VERSION "HNNBNNNYNNNNNNNNNNNNNNNNNNNNNNNNNNNNNNNNNN/4/%%%/4/'%**4NNN///"

NS_ :

BS_:

BU_: BAP_Tester BCM Gateway_Max TSGGen3_BFS TSGGen3_FS TSGGen3_HBFS TSGGen3_HFS WLC_01_CFD

BO_ 1178 Mem_FS_01: 8 Gateway_Max
 SG_ Mem_FS_01_MQB_CRC : 0|8@1+ (1,0) [0|255] ""  Vector__XXX
 SG_ Mem_FS_01_MQB_BZ : 8|4@1+ (1,0) [0|15] ""  Vector__XXX
 SG_ FS_Fond_Bed_enable : 12|1@1+ (1.0,0.0) [0.0|1] ""  Vector__XXX
 SG_ FS_Lehne_nicht_verriegelt : 13|1@1+ (1.0,0.0) [0.0|1] ""  Vector__XXX
 SG_ FS_Spezialposition_anfahren : 14|1@1+ (1.0,0.0) [0.0|1] ""  Vector__XXX
 SG_ FS_Gurtbringer_Sperre : 15|1@1+ (1.0,0.0) [0.0|1] ""  TSGGen3_BFS,TSGGen3_FS,TSGGen3_HBFS,TSGGen3_HFS
 SG_ FS_BFS_Sitzsym_Anfahrt : 16|1@1+ (1.0,0.0) [0.0|1] ""  Vector__XXX
 SG_ FS_Sitzfahrt_aktiv : 17|1@1+ (1.0,0.0) [0.0|1] ""  TSGGen3_BFS,TSGGen3_FS,TSGGen3_HBFS,TSGGen3_HFS
 SG_ FS_SLV_aktiv : 18|1@1+ (1.0,0.0) [0.0|1] ""  Vector__XXX
 SG_ FS_SHV_aktiv : 19|1@1+ (1.0,0.0) [0.0|1] ""  Vector__XXX
 SG_ FS_LNV_aktiv : 20|1@1+ (1.0,0.0) [0.0|1] ""  Vector__XXX
 SG_ FS_SNV_aktiv : 21|1@1+ (1.0,0.0) [0.0|1] ""  Vector__XXX
 SG_ FS_KSV_aktiv : 22|1@1+ (1.0,0.0) [0.0|1] ""  Vector__XXX
 SG_ FS_LKV_aktiv : 23|1@1+ (1.0,0.0) [0.0|1] ""  Vector__XXX
 SG_ FS_STV_aktiv : 24|1@1+ (1.0,0.0) [0.0|1] ""  Vector__XXX
 SG_ FS_LHV_aktiv : 25|1@1+ (1.0,0.0) [0.0|1] ""  Vector__XXX
 SG_ FS_LWV_aktiv : 26|1@1+ (1.0,0.0) [0.0|1] ""  Vector__XXX
 SG_ FS_GHV_aktiv : 27|1@1+ (1.0,0.0) [0.0|1] ""  Vector__XXX
 SG_ FS_BFS_KSS_Anfahrt : 28|1@1+ (1.0,0.0) [0.0|1] ""  Vector__XXX
 SG_ FS_MMB_lokal_Stop : 29|1@1+ (1.0,0.0) [0.0|1] ""  Vector__XXX
 SG_ FS_MMB_storage : 32|4@1+ (1.0,0.0) [0.0|15] ""  BCM,TSGGen3_FS
 SG_ FS_MMB_tipp : 36|1@1+ (1.0,0.0) [0.0|1] ""  BCM,TSGGen3_FS
 SG_ FS_MMB_tast : 37|1@1+ (1.0,0.0) [0.0|1] ""  BCM,TSGGen3_FS
 SG_ FS_MMB_store_LED_on : 38|1@1+ (1.0,0.0) [0.0|1] ""  TSGGen3_FS
 SG_ FS_MMB_storage_beep : 39|1@1+ (1.0,0.0) [0.0|1] ""  Vector__XXX
 SG_ FS_MMB_store : 40|1@1+ (1.0,0.0) [0.0|1] ""  TSGGen3_FS
 SG_ FS_MMB_glob_stop : 41|1@1+ (1.0,0.0) [0.0|1] ""  BCM,TSGGen3_FS
 SG_ FS_EE_Fond_FS_enable : 42|1@1+ (1.0,0.0) [0.0|1] ""  Vector__XXX
 SG_ FS_EE_Fond_BFS_enable : 43|1@1+ (1.0,0.0) [0.0|1] ""  Vector__XXX
 SG_ FS_BFS_Fond_Verst_enable : 44|1@1+ (1.0,0.0) [0.0|1] ""  Vector__XXX
 SG_ FS_EE_BFS_enable : 45|1@1+ (1.0,0.0) [0.0|1] ""  Vector__XXX

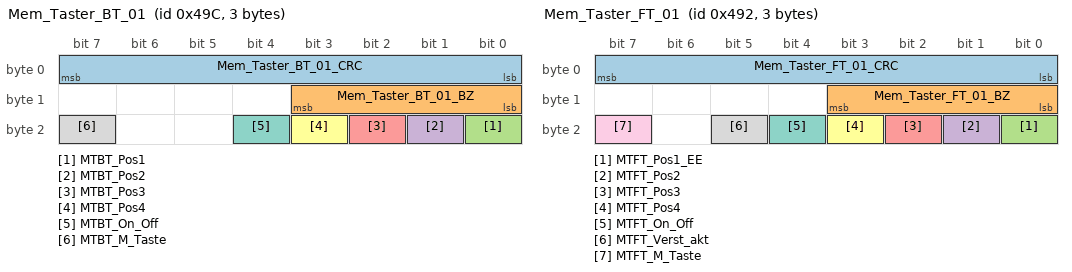
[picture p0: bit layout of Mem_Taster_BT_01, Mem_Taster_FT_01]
BO_ 1180 Mem_Taster_BT_01: 3 TSGGen3_BFS
 SG_ Mem_Taster_BT_01_CRC : 0|8@1+ (1,0) [0|255] ""  Gateway_Max
 SG_ Mem_Taster_BT_01_BZ : 8|4@1+ (1,0) [0|15] ""  Gateway_Max
 SG_ MTBT_Pos1 : 16|1@1+ (1.0,0.0) [0.0|1] ""  Gateway_Max
 SG_ MTBT_Pos2 : 17|1@1+ (1.0,0.0) [0.0|1] ""  Gateway_Max
 SG_ MTBT_Pos3 : 18|1@1+ (1.0,0.0) [0.0|1] ""  Gateway_Max
 SG_ MTBT_Pos4 : 19|1@1+ (1.0,0.0) [0.0|1] ""  Gateway_Max
 SG_ MTBT_On_Off : 20|1@1+ (1.0,0.0) [0.0|1] ""  Gateway_Max
 SG_ MTBT_M_Taste : 23|1@1+ (1.0,0.0) [0.0|1] ""  Gateway_Max

BO_ 1170 Mem_Taster_FT_01: 3 TSGGen3_FS
 SG_ Mem_Taster_FT_01_CRC : 0|8@1+ (1,0) [0|255] ""  Gateway_Max
 SG_ Mem_Taster_FT_01_BZ : 8|4@1+ (1,0) [0|15] ""  Gateway_Max
 SG_ MTFT_Pos1_EE : 16|1@1+ (1.0,0.0) [0.0|1] ""  Gateway_Max
 SG_ MTFT_Pos2 : 17|1@1+ (1.0,0.0) [0.0|1] ""  Gateway_Max
 SG_ MTFT_Pos3 : 18|1@1+ (1.0,0.0) [0.0|1] ""  Gateway_Max
 SG_ MTFT_Pos4 : 19|1@1+ (1.0,0.0) [0.0|1] ""  Gateway_Max
 SG_ MTFT_On_Off : 20|1@1+ (1.0,0.0) [0.0|1] ""  Gateway_Max
 SG_ MTFT_Verst_akt : 21|1@1+ (1.0,0.0) [0.0|1] ""  Gateway_Max
 SG_ MTFT_M_Taste : 23|1@1+ (1.0,0.0) [0.0|1] ""  Gateway_Max

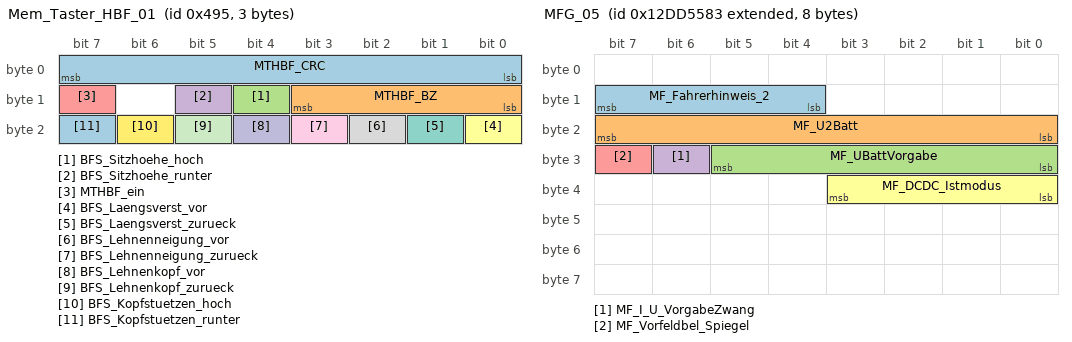
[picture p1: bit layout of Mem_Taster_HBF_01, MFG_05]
BO_ 1173 Mem_Taster_HBF_01: 3 TSGGen3_HBFS
 SG_ MTHBF_CRC : 0|8@1+ (1,0) [0|255] ""  Gateway_Max
 SG_ MTHBF_BZ : 8|4@1+ (1,0) [0|15] ""  Gateway_Max
 SG_ BFS_Sitzhoehe_hoch : 12|1@1+ (1.0,0.0) [0.0|1] ""  Gateway_Max
 SG_ BFS_Sitzhoehe_runter : 13|1@1+ (1.0,0.0) [0.0|1] ""  Gateway_Max
 SG_ MTHBF_ein : 15|1@1+ (1.0,0.0) [0.0|1] ""  Gateway_Max
 SG_ BFS_Laengsverst_vor : 16|1@1+ (1.0,0.0) [0.0|1] ""  Gateway_Max
 SG_ BFS_Laengsverst_zurueck : 17|1@1+ (1.0,0.0) [0.0|1] ""  Gateway_Max
 SG_ BFS_Lehnenneigung_vor : 18|1@1+ (1.0,0.0) [0.0|1] ""  Gateway_Max
 SG_ BFS_Lehnenneigung_zurueck : 19|1@1+ (1.0,0.0) [0.0|1] ""  Gateway_Max
 SG_ BFS_Lehnenkopf_vor : 20|1@1+ (1.0,0.0) [0.0|1] ""  Gateway_Max
 SG_ BFS_Lehnenkopf_zurueck : 21|1@1+ (1.0,0.0) [0.0|1] ""  Gateway_Max
 SG_ BFS_Kopfstuetzen_hoch : 22|1@1+ (1.0,0.0) [0.0|1] ""  Gateway_Max
 SG_ BFS_Kopfstuetzen_runter : 23|1@1+ (1.0,0.0) [0.0|1] ""  Gateway_Max

BO_ 1171 MFG_01: 8 Gateway_Max
 SG_ MFG_01_CRC : 0|8@1+ (1,0) [0|255] ""  BCM
 SG_ MFG_01_BZ : 8|4@1+ (1,0) [0|15] ""  BCM
 SG_ MF_ZV_Lock : 12|1@1+ (1.0,0.0) [0.0|1] ""  BCM
 SG_ MF_Motorweiterlauf : 13|1@1+ (1.0,0.0) [0.0|1] ""  BCM
 SG_ MF_Abzugssperre : 14|1@1+ (1.0,0.0) [0.0|1] ""  Vector__XXX
 SG_ MF_Anlassersperre : 15|1@1+ (1.0,0.0) [0.0|1] ""  Vector__XXX
 SG_ MF_Variante : 16|3@1+ (1.0,0.0) [0.0|7] ""  BCM,TSGGen3_BFS,TSGGen3_FS,TSGGen3_HBFS,TSGGen3_HFS
 SG_ MF_Schluessel_scan : 19|1@1+ (1.0,0.0) [0.0|1] ""  Vector__XXX
 SG_ MF_Laderelais : 20|1@1+ (1.0,0.0) [0.0|1] ""  Vector__XXX
 SG_ MF_StartStopp_Info : 21|2@1+ (1.0,0.0) [0.0|3] ""  Vector__XXX
 SG_ MF_Fernbed_ein : 23|1@1+ (1.0,0.0) [0.0|1] ""  BCM,TSGGen3_BFS,TSGGen3_FS,TSGGen3_HBFS,TSGGen3_HFS
 SG_ MF_Standlicht : 24|1@1+ (1.0,0.0) [0.0|1] ""  BCM
 SG_ MF_Fahrlicht : 25|1@1+ (1.0,0.0) [0.0|1] ""  BCM
 SG_ MF_interm_Fernlicht : 26|1@1+ (1.0,0.0) [0.0|1] ""  BCM
 SG_ MF_Warnblinker : 27|1@1+ (1.0,0.0) [0.0|1] ""  BCM
 SG_ MF_Fussraumbel : 28|1@1+ (1.0,0.0) [0.0|1] ""  BCM,TSGGen3_FS
 SG_ MF_Innenraumbel : 29|1@1+ (1.0,0.0) [0.0|1] ""  BCM,TSGGen3_BFS,TSGGen3_FS,TSGGen3_HBFS,TSGGen3_HFS
 SG_ MF_Innenraumbel_Unterdrueck : 30|1@1+ (1.0,0.0) [0.0|1] ""  BCM,TSGGen3_BFS,TSGGen3_FS,TSGGen3_HBFS,TSGGen3_HFS
 SG_ MF_Notstart : 31|1@1+ (1.0,0.0) [0.0|1] ""  Vector__XXX
 SG_ MF_Blk_li : 32|1@1+ (1.0,0.0) [0.0|1] ""  BCM
 SG_ MF_Blk_re : 33|1@1+ (1.0,0.0) [0.0|1] ""  BCM
 SG_ MF_Lichthupe : 34|1@1+ (1.0,0.0) [0.0|1] ""  BCM
 SG_ MF_Fernlicht : 35|1@1+ (1.0,0.0) [0.0|1] ""  BCM
 SG_ MF_HFS_verriegeln : 36|1@1+ (1.0,0.0) [0.0|1] ""  BCM
 SG_ MF_HFS_entriegeln : 37|1@1+ (1.0,0.0) [0.0|1] ""  BCM
 SG_ MF_HBFS_verriegeln : 38|1@1+ (1.0,0.0) [0.0|1] ""  BCM
 SG_ MF_HBFS_entriegeln : 39|1@1+ (1.0,0.0) [0.0|1] ""  BCM
 SG_ MF_Tippwischen : 40|1@1+ (1.0,0.0) [0.0|1] ""  BCM
 SG_ MF_Frontintervall : 41|1@1+ (1.0,0.0) [0.0|1] ""  BCM
 SG_ MF_Wischerstufe_1 : 42|1@1+ (1.0,0.0) [0.0|1] ""  BCM
 SG_ MF_Wischerstufe_2 : 43|1@1+ (1.0,0.0) [0.0|1] ""  BCM
 SG_ MF_Frontwaschen : 44|1@1+ (1.0,0.0) [0.0|1] ""  BCM
 SG_ MF_nachtr_Stopp_Anf : 45|1@1+ (1.0,0.0) [0.0|1] ""  Vector__XXX
 SG_ MF_Heckintervall : 46|1@1+ (1.0,0.0) [0.0|1] ""  BCM
 SG_ MF_Heckwaschen : 47|1@1+ (1.0,0.0) [0.0|1] ""  BCM
 SG_ MF_Summer : 48|1@1+ (1.0,0.0) [0.0|1] ""  Vector__XXX
 SG_ MF_Alarm_Blinkertakt : 49|1@1+ (1.0,0.0) [0.0|1] ""  BCM
 SG_ MF_Alarm_Blinker : 50|1@1+ (1.0,0.0) [0.0|1] ""  BCM
 SG_ MF_TFL_Abschaltung : 51|1@1+ (1.0,0.0) [0.0|1] ""  BCM
 SG_ MF_interm_Takt : 52|1@1+ (1.0,0.0) [0.0|1] ""  BCM
 SG_ MF_Tuerentriegelung_hinten : 53|1@1+ (1.0,0.0) [0.0|1] ""  BCM
 SG_ MF_interm_Fahrlicht : 54|1@1+ (1.0,0.0) [0.0|1] ""  BCM
 SG_ MF_Signalhorn : 55|1@1+ (1.0,0.0) [0.0|1] ""  BCM
 SG_ MF_FH_FT_hoch : 56|1@1+ (1.0,0.0) [0.0|1] ""  TSGGen3_FS
 SG_ MF_FH_FT_tief : 57|1@1+ (1.0,0.0) [0.0|1] ""  TSGGen3_FS
 SG_ MF_FH_BT_hoch : 58|1@1+ (1.0,0.0) [0.0|1] ""  TSGGen3_BFS
 SG_ MF_FH_BT_tief : 59|1@1+ (1.0,0.0) [0.0|1] ""  TSGGen3_BFS
 SG_ MF_FT_verriegeln : 60|1@1+ (1.0,0.0) [0.0|1] ""  BCM
 SG_ MF_FT_entriegeln : 61|1@1+ (1.0,0.0) [0.0|1] ""  BCM
 SG_ MF_BT_verriegeln : 62|1@1+ (1.0,0.0) [0.0|1] ""  BCM
 SG_ MF_BT_entriegeln : 63|1@1+ (1.0,0.0) [0.0|1] ""  BCM

BO_ 1164 MFG_03: 8 Gateway_Max
 SG_ MFG_Infotainment_Autark : 12|1@1+ (1.0,0.0) [0.0|1] ""  Vector__XXX
 SG_ MFG_Klappe_Status : 13|3@1+ (1.0,0.0) [0.0|7] ""  Vector__XXX
 SG_ MFG_LSH_DBetr_Ein : 16|1@1+ (1.0,0.0) [0.0|1] ""  Vector__XXX
 SG_ MFG_LSH_Betriebsdauer : 17|7@1+ (1,0) [0|120] "Unit_Minut"  Vector__XXX
 SG_ MFG_LSH_DBetr_Bestaet : 24|1@1+ (1.0,0.0) [0.0|1] ""  Vector__XXX
 SG_ MFG_LSH_Ansteuerung : 25|2@1+ (1.0,0.0) [0.0|3] ""  Vector__XXX
 SG_ MF_Radiomute : 27|1@1+ (1.0,0.0) [0.0|1] ""  Vector__XXX
 SG_ MF_Relais_2_Batterie : 28|1@1+ (1.0,0.0) [0.0|1] ""  Vector__XXX
 SG_ MF_Batteriediagnose : 29|3@1+ (1.0,0.0) [0.0|7] ""  Vector__XXX
 SG_ MFG_AppConnect_Anf : 32|2@1+ (1.0,0.0) [0.0|3] ""  Vector__XXX
 SG_ MF_Lampenausfall : 34|1@1+ (1.0,0.0) [0.0|1] ""  BCM
 SG_ MF_Blinker_L_Sta : 35|1@1+ (1.0,0.0) [0.0|1] ""  BCM
 SG_ MF_Blinker_R_Sta : 36|1@1+ (1.0,0.0) [0.0|1] ""  BCM
 SG_ MF_interm_Nebelscheinwerfer : 37|1@1+ (1.0,0.0) [0.0|1] ""  Vector__XXX
 SG_ MF_Generatordiagnose : 38|2@1+ (1.0,0.0) [0.0|3] ""  Vector__XXX
 SG_ MF_Heck_entriegeln : 40|1@1+ (1.0,0.0) [0.0|1] ""  BCM
 SG_ MF_Heck_verriegeln : 41|1@1+ (1.0,0.0) [0.0|1] ""  BCM
 SG_ MF_2BatSOCzugering : 42|1@1+ (1.0,0.0) [0.0|1] ""  Vector__XXX
 SG_ MF_Fahrerhinweis : 43|3@1+ (1.0,0.0) [0.0|7] ""  Vector__XXX
 SG_ MF_ZV_Unlock : 46|1@1+ (1.0,0.0) [0.0|1] ""  BCM
 SG_ MF_Tuerverriegelung_hinten : 47|1@1+ (1.0,0.0) [0.0|1] ""  BCM
 SG_ MF_2BattAb : 48|1@1+ (1.0,0.0) [0.0|1] ""  Vector__XXX
 SG_ MF_2BattHlkAnf : 49|1@1+ (1.0,0.0) [0.0|1] ""  Vector__XXX
 SG_ MF_2BattLadWarn : 50|1@1+ (1.0,0.0) [0.0|1] ""  Vector__XXX
 SG_ MF_2BattLlaAnf : 51|1@1+ (1.0,0.0) [0.0|1] ""  Vector__XXX
 SG_ MF_2BattSpannungsAnf : 52|2@1+ (1.0,0.0) [0.0|3] ""  Vector__XXX
 SG_ MF_NotStartAktiv : 54|1@1+ (1.0,0.0) [0.0|1] ""  Vector__XXX
 SG_ MF_ExterneLadungWarn : 55|1@1+ (1.0,0.0) [0.0|1] ""  Vector__XXX
 SG_ MF_LSH_Zielzeit : 56|4@1+ (10,0) [0|130] "Unit_Minut"  Vector__XXX
 SG_ MF_LSH_Abschaltstufe : 60|3@1+ (1.0,0.0) [0.0|7] ""  Vector__XXX
 SG_ MF_LSH_Einschaltverbot : 63|1@1+ (1.0,0.0) [0.0|1] ""  Vector__XXX

BO_ 2463978883 MFG_05: 8 Gateway_Max
 SG_ MF_Fahrerhinweis_2 : 12|4@1+ (1.0,0.0) [0.0|15] ""  Vector__XXX
 SG_ MF_U2Batt : 16|8@1+ (0.01,12.5) [12.50|15.00] "Unit_Volt"  Vector__XXX
 SG_ MF_UBattVorgabe : 24|6@1+ (0.1,12) [12.0|18.0] "Unit_Volt"  Vector__XXX
 SG_ MF_I_U_VorgabeZwang : 30|1@1+ (1.0,0.0) [0.0|1] ""  Vector__XXX
 SG_ MF_Vorfeldbel_Spiegel : 31|1@1+ (1.0,0.0) [0.0|1] ""  TSGGen3_BFS,TSGGen3_FS
 SG_ MF_DCDC_Istmodus : 32|4@1+ (1.0,0.0) [0.0|15] ""  Vector__XXX

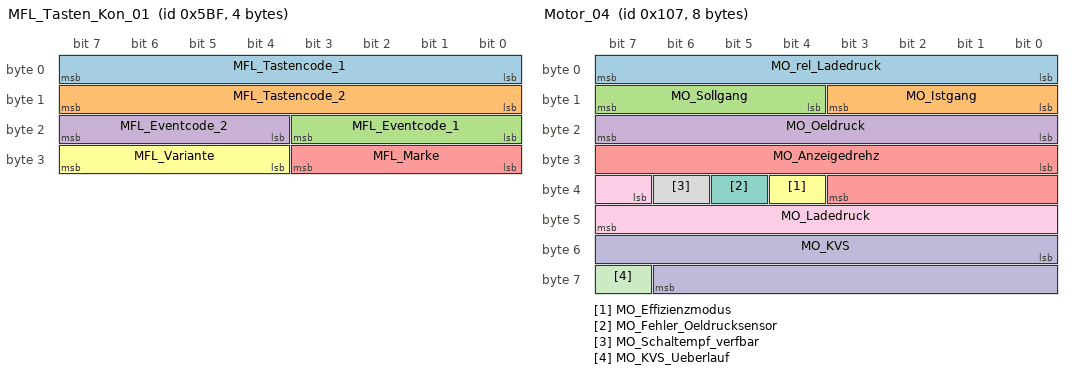
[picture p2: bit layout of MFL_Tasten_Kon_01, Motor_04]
BO_ 1471 MFL_Tasten_Kon_01: 4 Gateway_Max
 SG_ MFL_Tastencode_1 : 0|8@1+ (1.0,0.0) [0.0|255] ""  BCM
 SG_ MFL_Tastencode_2 : 8|8@1+ (1.0,0.0) [0.0|255] ""  BCM
 SG_ MFL_Eventcode_1 : 16|4@1+ (1.0,0.0) [0.0|15] ""  BCM
 SG_ MFL_Eventcode_2 : 20|4@1+ (1.0,0.0) [0.0|15] ""  BCM
 SG_ MFL_Marke : 24|4@1+ (1.0,0.0) [0.0|15] ""  BCM
 SG_ MFL_Variante : 28|4@1+ (1,0) [0|15] ""  BCM

BO_ 2463978865 MIK_01: 32 Gateway_Max
 SG_ MIK_01_CRC : 0|8@1+ (1,0) [0|255] ""  BCM
 SG_ MIK_01_BZ : 8|4@1+ (1,0) [0|15] ""  BCM
 SG_ MIK_Fahrer_erkannt : 12|2@1+ (1.0,0.0) [0.0|3] ""  BCM
 SG_ MIK_TotDurEyesNotOnTfc : 14|10@1+ (0.1,0) [0.0|102.0] "Unit_Secon"  Vector__XXX
 SG_ MIK_BlinkRate : 24|5@1+ (1,0) [0|27] "Unit_None"  Vector__XXX
 SG_ MIK_Status : 29|3@1+ (1.0,0.0) [0.0|7] ""  Vector__XXX
 SG_ MIK_LeftHandPos : 32|4@1+ (1.0,0.0) [0.0|15] ""  Vector__XXX
 SG_ MIK_LeftHandPosQual : 36|4@1+ (10,0) [0|100] "Unit_PerCent"  Vector__XXX
 SG_ MIK_RightHandPos : 40|4@1+ (1.0,0.0) [0.0|15] ""  Vector__XXX
 SG_ MIK_RightHandPosQual : 44|4@1+ (10,0) [0|100] "Unit_PerCent"  Vector__XXX
 SG_ MIK_DrowsinessLevel : 48|4@1+ (1.0,0.0) [0.0|15] ""  Vector__XXX
 SG_ MIK_DrowsinessLevelQual : 52|4@1+ (10,0) [0|100] "Unit_PerCent"  Vector__XXX
 SG_ MIK_DriverSmoking : 56|3@1+ (1.0,0.0) [0.0|7] ""  Vector__XXX
 SG_ MIK_PassengerPresence : 59|1@1+ (1.0,0.0) [0.0|1] ""  Vector__XXX
 SG_ MIK_DriverSmokingQual : 60|4@1+ (10,0) [0|100] "Unit_PerCent"  Vector__XXX
 SG_ MIK_DriverTelephoneUsage : 64|3@1+ (1.0,0.0) [0.0|7] ""  Vector__XXX
 SG_ MIK_DriverSpeaking : 67|1@1+ (1.0,0.0) [0.0|1] ""  Vector__XXX
 SG_ MIK_DriverTelephoneUsageQual : 68|4@1+ (10,0) [0|100] "Unit_PerCent"  Vector__XXX
 SG_ MIK_DriverYawning : 72|3@1+ (1.0,0.0) [0.0|7] ""  Vector__XXX
 SG_ FaceRec_Auth_Challenge_Request : 75|1@1+ (1.0,0.0) [0.0|1] ""  Vector__XXX
 SG_ MIK_DriverYawningQual : 76|4@1+ (10,0) [0|100] "Unit_PerCent"  Vector__XXX
 SG_ MIK_Microsleep : 80|3@1+ (1.0,0.0) [0.0|7] ""  Vector__XXX
 SG_ FaceRec2_Status_Challenge_Req : 83|1@1+ (1.0,0.0) [0.0|1] ""  Vector__XXX
 SG_ MIK_MicrosleepQual : 84|4@1+ (10,0) [0|100] "Unit_PerCent"  Vector__XXX
 SG_ MIK_UnusualHeadPose : 88|3@1+ (1.0,0.0) [0.0|7] ""  Vector__XXX
 SG_ MIK_UnusualHeadPoseQual : 92|4@1+ (10,0) [0|100] "Unit_PerCent"  Vector__XXX
 SG_ MIK_VisualDistractionLevel : 96|3@1+ (1.0,0.0) [0.0|7] ""  Vector__XXX
 SG_ MIK_VisualDistractionLevelQual : 100|4@1+ (10,0) [0|100] "Unit_PerCent"  Vector__XXX
 SG_ MIK_DurEyesNotOnTfc : 104|9@1+ (0.1,0) [0.0|50.7] "Unit_Secon"  Vector__XXX
 SG_ MIK_DurEyesCl : 113|7@1+ (0.1,0) [0.0|12.3] "Unit_Secon"  Vector__XXX
 SG_ MIK_PercentageEyesOnTraffic : 120|7@1+ (1,0) [0|100] "Unit_PerCent"  Vector__XXX
 SG_ MIK_SpaAttDstrAr_01 : 127|5@1+ (1.0,0.0) [0.0|31] ""  Vector__XXX
 SG_ MIK_SpaAttDstrProb_01 : 132|4@1+ (10,0) [0|100] "Unit_PerCent"  Vector__XXX
 SG_ MIK_DetectionMode : 136|3@1+ (1.0,0.0) [0.0|7] ""  Vector__XXX
 SG_ MIK_DriverChange : 139|1@1+ (1.0,0.0) [0.0|1] ""  Vector__XXX
 SG_ MIK_DriverPresence : 140|3@1+ (1.0,0.0) [0.0|7] ""  Vector__XXX
 SG_ MIK_FakeDetected : 143|1@1+ (1.0,0.0) [0.0|1] ""  Vector__XXX
 SG_ MIK_ICV_Brightness : 144|7@1+ (1,0) [0|100] "Unit_PerCent"  Vector__XXX
 SG_ MIK_ICV_FrameRate : 151|5@1+ (1,0) [15|30] "Unit_SeconInver"  Vector__XXX
 SG_ MIK_ICV_FieldOfView : 156|2@1+ (1.0,0.0) [0.0|3] ""  Vector__XXX
 SG_ MIK_ICV_FunctionState : 158|2@1+ (1.0,0.0) [0.0|3] ""  Vector__XXX
 SG_ MIK_ICV_Resolution : 160|3@1+ (1.0,0.0) [0.0|7] ""  Vector__XXX
 SG_ MIK_ICV_Videostream_State : 163|3@1+ (1.0,0.0) [0.0|7] ""  Vector__XXX
 SG_ MIK_ICV_VideostreamResult : 166|2@1+ (1.0,0.0) [0.0|3] ""  Vector__XXX
 SG_ MIK_ICV_ColorMode : 168|2@1+ (1.0,0.0) [0.0|3] ""  Vector__XXX
 SG_ MIK_ICV_HDR : 170|2@1+ (1.0,0.0) [0.0|3] ""  Vector__XXX
 SG_ MIK_ICV_Contrast : 172|7@1+ (1,0) [0|100] "Unit_PerCent"  Vector__XXX
 SG_ MIK_Selfie_FunctionState : 179|3@1+ (1.0,0.0) [0.0|7] ""  Vector__XXX
 SG_ MIK_Selfie_Resolution : 182|2@1+ (1.0,0.0) [0.0|3] ""  Vector__XXX
 SG_ MIK_ICV_AspectRatio : 184|3@1+ (1.0,0.0) [0.0|7] ""  Vector__XXX
 SG_ MIK_ICV_VideoLength : 187|3@1+ (1.0,0.0) [0.0|7] ""  Vector__XXX
 SG_ MIK_ChildStatus : 190|2@1+ (1.0,0.0) [0.0|3] ""  Vector__XXX
 SG_ MIK_PetPresence : 192|2@1+ (1.0,0.0) [0.0|3] ""  Vector__XXX
 SG_ MIK_CabinCare_state : 194|3@1+ (1.0,0.0) [0.0|7] ""  Vector__XXX
 SG_ MIK_PetsMode_Active : 197|1@1+ (1.0,0.0) [0.0|1] ""  Vector__XXX
 SG_ MIK_ChildPresence : 198|2@1+ (1.0,0.0) [0.0|3] ""  Vector__XXX
 SG_ MIK_CabinCare_Active : 200|1@1+ (1.0,0.0) [0.0|1] ""  Vector__XXX
 SG_ MIK_ICC_RemoteAccessStatus : 201|2@1+ (1.0,0.0) [0.0|3] ""  Vector__XXX

BO_ 2527679795 MKGO_FBS_01: 64 WLC_01_CFD
 SG_ MKGO_FBS_01 : 0|512@1+ (1.0,0.0) [0.0|13407807929942597099574024998205846127479365820592393377723561443721764030073546976801874298166903427690031858186486050853753882811946569946433649006084095] ""  BCM

BO_ 2527679796 MKGO_FBS_02: 64 WLC_01_CFD
 SG_ MKGO_FBS_02 : 0|512@1+ (1.0,0.0) [0.0|13407807929942597099574024998205846127479365820592393377723561443721764030073546976801874298166903427690031858186486050853753882811946569946433649006084095] ""  BCM

BO_ 2527679797 MKGO_FBS_03: 64 WLC_01_CFD
 SG_ MKGO_FBS_03 : 0|512@1+ (1.0,0.0) [0.0|13407807929942597099574024998205846127479365820592393377723561443721764030073546976801874298166903427690031858186486050853753882811946569946433649006084095] ""  BCM

BO_ 2527679798 MKGO_FBS_04: 64 WLC_01_CFD
 SG_ MKGO_FBS_04 : 0|512@1+ (1.0,0.0) [0.0|13407807929942597099574024998205846127479365820592393377723561443721764030073546976801874298166903427690031858186486050853753882811946569946433649006084095] ""  BCM

BO_ 2527679799 MKGO_FBS_05: 64 WLC_01_CFD
 SG_ MKGO_FBS_05 : 0|512@1+ (1.0,0.0) [0.0|13407807929942597099574024998205846127479365820592393377723561443721764030073546976801874298166903427690031858186486050853753882811946569946433649006084095] ""  BCM

BO_ 263 Motor_04: 8 Gateway_Max
 SG_ MO_rel_Ladedruck : 0|8@1+ (0.4,0) [0.0|100.0] "Unit_PerCent"  Vector__XXX
 SG_ MO_Istgang : 8|4@1+ (1.0,0.0) [0.0|15] ""  Vector__XXX
 SG_ MO_Sollgang : 12|4@1+ (1.0,0.0) [0.0|15] ""  Vector__XXX
 SG_ MO_Oeldruck : 16|8@1+ (0.04,0) [0.00|10.00] "Unit_Bar"  Vector__XXX
 SG_ MO_Anzeigedrehz : 24|12@1+ (3,0) [0|12282] "Unit_MinutInver"  BCM
 SG_ MO_Effizienzmodus : 36|1@1+ (1.0,0.0) [0.0|1] ""  Vector__XXX
 SG_ MO_Fehler_Oeldrucksensor : 37|1@1+ (1.0,0.0) [0.0|1] ""  Vector__XXX
 SG_ MO_Schaltempf_verfbar : 38|1@1+ (1.0,0.0) [0.0|1] ""  Vector__XXX
 SG_ MO_Ladedruck : 39|9@1+ (0.01,0) [0.00|5.10] "Unit_Bar"  Vector__XXX
 SG_ MO_KVS : 48|15@1+ (1,0) [0|32767] "Unit_MicroLiter"  Vector__XXX
 SG_ MO_KVS_Ueberlauf : 63|1@1+ (1.0,0.0) [0.0|1] ""  Vector__XXX

BO_ 1600 Motor_07: 8 Gateway_Max
 SG_ MO_QBit_Ansaugluft_Temp : 0|1@1+ (1.0,0.0) [0.0|1] ""  Vector__XXX
 SG_ MO_QBit_Oel_Temp : 1|1@1+ (1.0,0.0) [0.0|1] ""  Vector__XXX
 SG_ MO_QBit_Kuehlmittel_Temp : 2|1@1+ (1.0,0.0) [0.0|1] ""  Vector__XXX
 SG_ MO_KL15_Abschaltempfehlung : 3|1@1+ (1.0,0.0) [0.0|1] ""  BCM
 SG_ MO_HYB_Fehler_HV_Netz : 4|1@1+ (1.0,0.0) [0.0|1] ""  Vector__XXX
 SG_ MO_aktives_Getriebeheizen : 5|1@1+ (1.0,0.0) [0.0|1] ""  Vector__XXX
 SG_ MO_Absperrventil_oeffnen : 6|2@1+ (1.0,0.0) [0.0|3] ""  Vector__XXX
 SG_ MO_Ansaugluft_Temp : 8|8@1+ (0.75,-48) [-48.00|141.75] "Unit_DegreCelsi"  Vector__XXX
 SG_ MO_Oel_Temp : 16|8@1+ (1,-60) [-60|192] "Unit_DegreCelsi"  Vector__XXX
 SG_ MO_Kuehlmittel_Temp : 24|8@1+ (0.75,-48) [-48.00|141.75] "Unit_DegreCelsi"  Vector__XXX
 SG_ MO_Hoeheninfo : 32|8@1+ (0.00781,0) [0.00000|1.98374] ""  Vector__XXX
 SG_ MO_Kennfeldk : 40|1@1+ (1.0,0.0) [0.0|1] ""  Vector__XXX
 SG_ MO_Versionsinfo_02 : 41|5@1+ (1.0,0.0) [0.0|31] ""  Vector__XXX
 SG_ MO_QBit_Hoeheninfo : 46|1@1+ (1.0,0.0) [0.0|1] ""  Vector__XXX
 SG_ MO_Getriebe_kuehlen : 47|1@1+ (1.0,0.0) [0.0|1] ""  Vector__XXX
 SG_ MO_Mom_Traegheit_02 : 48|5@1+ (0.01,0) [0.00|0.31] "Unit_KiloGramMeterSquar"  Vector__XXX
 SG_ MO_Heizungspumpenansteuerung : 53|4@1+ (10,0) [0|100] "Unit_PerCent"  Vector__XXX
 SG_ MO_SpannungsAnf : 57|1@1+ (1.0,0.0) [0.0|1] ""  Vector__XXX
 SG_ MO_Nachlaufzeit_Heizungspumpe : 58|6@1+ (15,0) [0|945] "Unit_Secon"  Vector__XXX

BO_ 958 Motor_14: 8 Gateway_Max
 SG_ Motor_14_CRC : 0|8@1+ (1,0) [0|255] ""  BCM
 SG_ Motor_14_BZ : 8|4@1+ (1,0) [0|15] ""  BCM
 SG_ MO_StartStopp_Status : 12|2@1+ (1.0,0.0) [0.0|3] ""  BCM
 SG_ MO_StartStopp_Wiederstart : 14|1@1+ (1.0,0.0) [0.0|1] ""  BCM,TSGGen3_BFS,TSGGen3_FS,TSGGen3_HBFS,TSGGen3_HFS
 SG_ MO_StartStopp_Motorstopp : 15|1@1+ (1.0,0.0) [0.0|1] ""  BCM
 SG_ MO_Freig_Reku : 16|2@1+ (1.0,0.0) [0.0|3] ""  BCM
 SG_ MO_Kl_75 : 18|1@1+ (1.0,0.0) [0.0|1] ""  BCM,TSGGen3_BFS,TSGGen3_FS,TSGGen3_HBFS,TSGGen3_HFS
 SG_ MO_Kl_50 : 19|1@1+ (1.0,0.0) [0.0|1] ""  BCM,TSGGen3_BFS,TSGGen3_FS,TSGGen3_HBFS,TSGGen3_HFS
 SG_ MO_Gangposition : 20|4@1+ (1.0,0.0) [0.0|15] ""  BCM
 SG_ MO_StartStopp_Fahrerwunsch : 24|2@1+ (1.0,0.0) [0.0|3] ""  BCM
 SG_ MO_HYB_Fahrbereitschaft : 26|1@1+ (1.0,0.0) [0.0|1] ""  BCM
 SG_ MO_Ext_E_Fahrt_aktiv : 27|1@1+ (1.0,0.0) [0.0|1] ""  BCM
 SG_ MO_Fahrer_bremst : 28|1@1+ (1.0,0.0) [0.0|1] ""  BCM
 SG_ MO_QBit_Fahrer_bremst : 29|1@1+ (1.0,0.0) [0.0|1] ""  BCM
 SG_ MO_BLS : 30|1@1+ (1.0,0.0) [0.0|1] ""  BCM
 SG_ MO_Konsistenz_Bremsped : 31|1@1+ (1.0,0.0) [0.0|1] ""  BCM
 SG_ MO_Timeout_ESP : 32|1@1+ (1.0,0.0) [0.0|1] ""  BCM
 SG_ MO_Klima_Eingr : 33|2@1+ (1.0,0.0) [0.0|3] ""  BCM
 SG_ MO_Aussp_Anlass : 35|1@1+ (1.0,0.0) [0.0|1] ""  BCM
 SG_ MO_Freig_Anlass : 36|1@1+ (1.0,0.0) [0.0|1] ""  BCM
 SG_ MO_Kuppl_schalter : 37|1@1+ (1.0,0.0) [0.0|1] ""  BCM
 SG_ MO_Interlock : 38|1@1+ (1.0,0.0) [0.0|1] ""  BCM
 SG_ MO_Motor_laeuft : 39|1@1+ (1.0,0.0) [0.0|1] ""  BCM,TSGGen3_BFS,TSGGen3_FS,TSGGen3_HBFS,TSGGen3_HFS
 SG_ MO_Kickdown : 40|1@1+ (1.0,0.0) [0.0|1] ""  BCM
 SG_ MO_QBit_KL_75 : 41|1@1+ (1.0,0.0) [0.0|1] ""  BCM,TSGGen3_BFS,TSGGen3_FS,TSGGen3_HBFS,TSGGen3_HFS
 SG_ MO_EKlKomLeiRed : 42|2@1+ (1.0,0.0) [0.0|3] ""  BCM
 SG_ MO_Handshake_STH : 44|1@1+ (1.0,0.0) [0.0|1] ""  BCM
 SG_ MO_BKV_Unterdruckwarnung : 45|1@1+ (1.0,0.0) [0.0|1] ""  BCM
 SG_ MO_Freigabe_Segeln : 46|1@1+ (1.0,0.0) [0.0|1] ""  BCM
 SG_ MO_PTC_Status : 47|3@1+ (1.0,0.0) [0.0|7] ""  BCM
 SG_ MO_QBit_Gangposition : 50|1@1+ (1.0,0.0) [0.0|1] ""  BCM
 SG_ MO_Signalquelle_Gangposition : 51|1@1+ (1.0,0.0) [0.0|1] ""  BCM
 SG_ MO_Remotestart_Betrieb : 52|1@1+ (1.0,0.0) [0.0|1] ""  BCM
 SG_ MO_Remotestart_moeglich : 53|1@1+ (1.0,0.0) [0.0|1] ""  BCM
 SG_ MO_FMAus_aktiv : 55|1@1+ (1.0,0.0) [0.0|1] ""  BCM
 SG_ MO_FMAus_Startvariante : 56|2@1+ (1.0,0.0) [0.0|3] ""  BCM
 SG_ MO_BMS_NV_Anf_stuetzen : 58|1@1+ (1.0,0.0) [0.0|1] ""  BCM
 SG_ MO_Zylinderabschaltung : 59|2@1+ (1.0,0.0) [0.0|3] ""  BCM
 SG_ MO_HYB_VM_aktiv : 61|1@1+ (1.0,0.0) [0.0|1] ""  BCM
 SG_ MO_StartVorauss_erfuellt : 62|2@1+ (1.0,0.0) [0.0|3] ""  BCM

BO_ 1648 Motor_18: 8 Gateway_Max
 SG_ MO_max_Ladedruck : 0|6@1+ (0.1,0) [0.0|6.3] "Unit_Bar"  Vector__XXX
 SG_ MO_ANC_Kennfeld_Anf : 6|2@1+ (1.0,0.0) [0.0|3] ""  Vector__XXX
 SG_ MO_Bremslicht_Reku : 8|1@1+ (1.0,0.0) [0.0|1] ""  BCM
 SG_ MO_StartStopp_PopUp : 9|2@1+ (1.0,0.0) [0.0|3] ""  Vector__XXX
 SG_ MO1_Sperr_Info_WFS : 11|1@1+ (1.0,0.0) [0.0|1] ""  BCM
 SG_ MO1_Freigabe_Info_WFS : 12|1@1+ (1.0,0.0) [0.0|1] ""  Vector__XXX
 SG_ MO_EPCL : 13|3@1+ (1.0,0.0) [0.0|7] ""  Vector__XXX
 SG_ MO_Zylabsch_Texte_02 : 16|4@1+ (1.0,0.0) [0.0|15] ""  Vector__XXX
 SG_ MO_Fahrzeugtyp : 20|3@1+ (1.0,0.0) [0.0|7] ""  BCM
 SG_ MO_NMAX_Schaltanzeige : 23|9@1+ (25,0) [0|12775] "Unit_MinutInver"  Vector__XXX
 SG_ MO_Abstellzeit : 32|8@1+ (8,0) [0|2024] "Unit_Minut"  Vector__XXX
 SG_ MO_Abstellzeit_Status : 40|2@1+ (1.0,0.0) [0.0|3] ""  Vector__XXX
 SG_ MO1_Freigabe_Verfallsinfo_WFS : 42|1@1+ (1.0,0.0) [0.0|1] ""  Vector__XXX
 SG_ MO_Hybrid_StartStopp_LED : 43|2@1+ (1.0,0.0) [0.0|3] ""  BCM
 SG_ MO_Fehler_Zylabsch : 45|2@1+ (1.0,0.0) [0.0|3] ""  Vector__XXX
 SG_ MO_Anzahl_Abgesch_Zyl : 47|3@1+ (1.0,0.0) [0.0|7] ""  Vector__XXX
 SG_ MO_Zylabsch_Texte : 50|2@1+ (1.0,0.0) [0.0|3] ""  Vector__XXX
 SG_ MO_Ethanol_BS_Texte : 52|3@1+ (1.0,0.0) [0.0|7] ""  Vector__XXX
 SG_ MO_Drehzahl_Warnung : 55|1@1+ (1.0,0.0) [0.0|1] ""  Vector__XXX
 SG_ MO_obere_Drehzahlgrenze : 56|8@1+ (50,0) [50|12750] "Unit_MinutInver"  Vector__XXX

BO_ 967 Motor_26: 8 Gateway_Max
 SG_ MO_Kuehlerluefter_MUX M  : 0|1@1+ (1.0,0.0) [0.0|1] ""  BCM
 SG_ MO_Kuehlerluefter_1 m0  : 1|7@1+ (1,0) [0|100] "Unit_PerCent"  BCM
 SG_ MO_Kuehlerluefter_2 m1  : 1|7@1+ (1,0) [0|100] "Unit_PerCent"  BCM
 SG_ MO_EFLEX_Lampe : 8|2@1+ (1.0,0.0) [0.0|3] ""  BCM
 SG_ MO_KJS_nicht_bereit : 10|1@1+ (1.0,0.0) [0.0|1] ""  BCM
 SG_ MO_ITM_Warnung_Pumpe : 11|1@1+ (1.0,0.0) [0.0|1] ""  BCM
 SG_ WIV_Anzeige_aktiv : 12|1@1+ (1.0,0.0) [0.0|1] ""  BCM
 SG_ WIV_Oelmin_Warn : 13|1@1+ (1.0,0.0) [0.0|1] ""  BCM
 SG_ WIV_Sensorfehler : 14|1@1+ (1.0,0.0) [0.0|1] ""  BCM
 SG_ WIV_Schieflage : 15|1@1+ (1.0,0.0) [0.0|1] ""  BCM
 SG_ WIV_Oelstand : 16|4@1+ (12.5,0) [0.0|100.0] "Unit_PerCent"  BCM
 SG_ MO_Zustand_HWP : 20|2@1+ (1.0,0.0) [0.0|3] ""  BCM
 SG_ OLEV_Systemstoerung : 22|1@1+ (1.0,0.0) [0.0|1] ""  BCM
 SG_ MO_Oelwarnung_max : 23|1@1+ (1.0,0.0) [0.0|1] ""  BCM
 SG_ WIV_Oelsystem_aktiv : 24|1@1+ (1.0,0.0) [0.0|1] ""  BCM
 SG_ WIV_nicht_betriebswarm : 25|1@1+ (1.0,0.0) [0.0|1] ""  BCM
 SG_ WIV_Ueberfuell_Warn : 26|1@1+ (1.0,0.0) [0.0|1] ""  BCM
 SG_ WIV_laufender_Motor : 27|1@1+ (1.0,0.0) [0.0|1] ""  BCM
 SG_ MO_E_Warnungen : 28|4@1+ (1.0,0.0) [0.0|15] ""  BCM
 SG_ MO_Text_Motorstart : 32|4@1+ (1.0,0.0) [0.0|15] ""  BCM
 SG_ MO_E_Texte : 36|4@1+ (1.0,0.0) [0.0|15] ""  BCM
 SG_ WIV_Oeldyn_avl : 40|1@1+ (1.0,0.0) [0.0|1] ""  BCM
 SG_ MO_Text_Partikelfil_Reg : 41|1@1+ (1,0) [0|1] ""  BCM
 SG_ OLEV_Oelstand_nicht_vorhanden : 42|1@1+ (1.0,0.0) [0.0|1] ""  BCM
 SG_ WIV_Oelmenge : 43|5@1+ (125,0) [0|3875] "Unit_MilliLiter"  BCM
 SG_ MO_Systemlampe : 48|1@1+ (1.0,0.0) [0.0|1] ""  BCM
 SG_ MO_OBD2_Lampe : 49|1@1+ (1.0,0.0) [0.0|1] ""  BCM
 SG_ MO_Heissleuchte : 50|1@1+ (1.0,0.0) [0.0|1] ""  BCM
 SG_ MO_Partikel_Lampe : 51|1@1+ (1.0,0.0) [0.0|1] ""  BCM
 SG_ MO_RedFahrleistung_Lampe : 52|1@1+ (1.0,0.0) [0.0|1] ""  BCM
 SG_ WIV_Oelstand_nicht_vorhanden : 53|1@1+ (1.0,0.0) [0.0|1] ""  BCM
 SG_ WIV_nachfuellanzeige_ein : 54|1@1+ (1.0,0.0) [0.0|1] ""  BCM
 SG_ WIV_Ueberfuell_deaktiv : 55|1@1+ (1.0,0.0) [0.0|1] ""  BCM
 SG_ WIV_Unterfuell_Warn : 56|1@1+ (1.0,0.0) [0.0|1] ""  BCM
 SG_ MO_Tankdeckel_Lampe : 57|1@1+ (1.0,0.0) [0.0|1] ""  BCM
 SG_ MO_Text_Tankdeckelwarn : 58|1@1+ (1.0,0.0) [0.0|1] ""  BCM
 SG_ MO_Vorglueh_Lampe : 59|1@1+ (1.0,0.0) [0.0|1] ""  BCM
 SG_ WIV_Oeldr_Warn_Motor : 60|1@1+ (1.0,0.0) [0.0|1] ""  BCM
 SG_ MO_E_Mode : 61|3@1+ (1.0,0.0) [0.0|7] ""  BCM

BO_ 267 Motor_51_Auth: 48 Gateway_Max
 SG_ Motor_51_CRC : 0|8@1+ (1,0) [0|255] ""  BCM
 SG_ Motor_51_BZ : 8|4@1+ (1,0) [0|15] ""  BCM
 SG_ MO_Fahrpedalrohwert_01 : 12|8@1+ (0.4,0) [0.0|101.6] "Unit_PerCent"  BCM
 SG_ MO_QBit_Fahrpedalwerte_01 : 20|1@1+ (1.0,0.0) [0.0|1] ""  BCM
 SG_ MO_Fahrpedalgradient : 21|8@1+ (25,0) [0|6350] "Unit_PerCentPerSecon"  Vector__XXX
 SG_ MO_Sig_Fahrpedalgradient : 29|1@1+ (1.0,0.0) [0.0|1] ""  Vector__XXX
 SG_ MO_rel_Saugrohrdruck : 30|6@1+ (18,0) [0|1116] "Unit_MilliBar"  Vector__XXX
 SG_ MO_rel_Saugrohrdruck_gem_err : 36|1@1+ (1.0,0.0) [0.0|1] ""  Vector__XXX
 SG_ MO_Moment_im_Leerlauf : 37|1@1+ (1.0,0.0) [0.0|1] ""  Vector__XXX
 SG_ MO_Schubabschaltung : 38|1@1+ (1.0,0.0) [0.0|1] ""  Vector__XXX
 SG_ MO_StartStopp_StoppVorbereitung : 39|1@1+ (1.0,0.0) [0.0|1] ""  Vector__XXX
 SG_ MO_Solldrehz_Leerlauf : 40|8@1+ (10,0) [0|2540] "Unit_MinutInver"  Vector__XXX
 SG_ MO_Entkopplung_Sollschlupf : 48|7@1+ (20,0) [0|2480] "Unit_MinutInver"  Vector__XXX
 SG_ MO_temporaere_Fahrerabwesenheit : 55|1@1+ (1.0,0.0) [0.0|1] ""  Vector__XXX
 SG_ TSK_a_Soll_gradientenbegrenzt : 57|7@1+ (0.1,-7.2) [-7.2|5.4] "Unit_MeterPerSeconSquar"  Vector__XXX
 SG_ TSK_Radbremsmom : 76|12@1+ (8,0) [0|32760] "Unit_NewtoMeter"  Vector__XXX
 SG_ TSK_Status : 88|3@1+ (1.0,0.0) [0.0|7] ""  Vector__XXX
 SG_ TSK_v_Begrenzung_aktiv : 91|1@1+ (1.0,0.0) [0.0|1] ""  Vector__XXX
 SG_ TSK_Standby_Anf_ESP : 92|1@1+ (1.0,0.0) [0.0|1] ""  Vector__XXX
 SG_ TSK_Freig_Verzoeg_Anf : 94|1@1+ (1.0,0.0) [0.0|1] ""  Vector__XXX
 SG_ TSK_Limiter_ausgewaehlt : 95|1@1+ (1.0,0.0) [0.0|1] ""  Vector__XXX
 SG_ TSK_Hauptschalter_GRA_ACC : 106|2@1+ (1.0,0.0) [0.0|3] ""  Vector__XXX
 SG_ TSK_SRBM_Anf_ASIL : 108|3@1+ (1.0,0.0) [0.0|7] ""  Vector__XXX
 SG_ TSK_ax_Getriebe_02 : 112|9@1+ (0.024,-2.016) [-2.016|10.224] "Unit_MeterPerSeconSquar"  Vector__XXX
 SG_ TSK_Zwangszusch_ESP : 121|1@1+ (1.0,0.0) [0.0|1] ""  Vector__XXX
 SG_ TSK_zul_Regelabw : 122|6@1+ (0.024,0) [0.000|1.512] "Unit_MeterPerSeconSquar"  Vector__XXX
 SG_ TSK_Radsollmoment : 128|16@1+ (0.5,-16383) [-16383.0|16383.5] "Unit_NewtoMeter"  Vector__XXX
 SG_ TSK_Kategorie_Verzoegerungsfkt : 144|2@1+ (1.0,0.0) [0.0|3] ""  Vector__XXX
 SG_ TSK_Notstopp_Anf : 233|2@1+ (1.0,0.0) [0.0|3] ""  Vector__XXX
 SG_ MO_Status_MinDrzEingriff : 235|3@1+ (1.0,0.0) [0.0|7] ""  Vector__XXX
 SG_ MO_Status_MaxDrzEingriff : 238|3@1+ (1.0,0.0) [0.0|7] ""  Vector__XXX
 SG_ MO_Status_MinDrzEingriff_sek : 241|3@1+ (1.0,0.0) [0.0|7] ""  Vector__XXX
 SG_ MO_Status_MaxDrzEingriff_sek : 244|3@1+ (1.0,0.0) [0.0|7] ""  Vector__XXX
 SG_ TSK_SRBM_max_Gradient : 248|7@1+ (50,0) [0|6250] "Unit_NewtoMeterPerSecon"  Vector__XXX
 SG_ SOK_Motor_51_Signatur : 352|32@1+ (1,0) [0|4294967295] ""  Vector__XXX

CM_ BO_ 1178 "ab MQB 7.2";
CM_ BO_ 1180 "Ab MLBevo - CRC
";
CM_ BO_ 1170 "Ab MLBevo - CRC
";
CM_ BO_ 1173 "Ab MLBevo - CRC";
CM_ BO_ 1171 "ab MQB 7.2 gültig";
CM_ BO_ 1600 "ab MQB mit QBit Höheneinfo und MO_Versionsinfo_02";
CM_ BO_ 1648 "Kombischnittstelle";
CM_ BO_ 967 "MQB - vorher Motor_06 / Umbenennung wg. ID-Wechsel";

CM_ SG_ 1178 FS_BFS_Fond_Verst_enable "Verstellung Fond (vom MMI)
";
CM_ SG_ 1178 FS_BFS_KSS_Anfahrt "Komfortseitensicht Anfahrt BFS";
CM_ SG_ 1178 FS_BFS_Sitzsym_Anfahrt "Sitzsymetrie Anfahrt BFS";
CM_ SG_ 1178 FS_EE_BFS_enable "EasyEntry Freigabe für Befahrersitz.";
CM_ SG_ 1178 FS_EE_Fond_BFS_enable "EE Fond rechts

";
CM_ SG_ 1178 FS_EE_Fond_FS_enable "EE Fond links
";
CM_ SG_ 1178 FS_Fond_Bed_enable "Freigabe für Fondsitzverstellungen";
CM_ SG_ 1178 FS_GHV_aktiv "Verstellung Gurthöhe
";
CM_ SG_ 1178 FS_Gurtbringer_Sperre "Freigabesignal für den Gurtzubringer";
CM_ SG_ 1178 FS_KSV_aktiv "Verstellung Kopfstütze
";
CM_ SG_ 1178 FS_Lehne_nicht_verriegelt "Fahrer Sitz Lehne Verstellung Verriegelt Status

Verwendung nur im Bentley";
CM_ SG_ 1178 FS_LHV_aktiv "Verstellung Lordose Höhe
";
CM_ SG_ 1178 FS_LKV_aktiv "Verstellung Lehnenkopf
";
CM_ SG_ 1178 FS_LNV_aktiv "Verstellung Lehnenneigung
";
CM_ SG_ 1178 FS_LWV_aktiv "Verstellung Lordose W
";
CM_ SG_ 1178 FS_MMB_glob_stop "Abbruch Memoryverstellung";
CM_ SG_ 1178 FS_MMB_lokal_Stop "mit dem lokal Stop moechte man, dass ein Sitz mit Pneumatik - Lordose sich im Memoryfall wie ein Sitz mit elektromechanischer Lordose verhaelt. Nur lokler Abbruch im TIP-Betrieb.";
CM_ SG_ 1178 FS_MMB_storage "Memory-Positionstaste, Funkschlüssel-Memory-ID, Benutzerkonto-Nummer";
CM_ SG_ 1178 FS_MMB_storage_beep "Quittierungston Sitzmemory FS (Anforderung Kombi)";
CM_ SG_ 1178 FS_MMB_store "Memoryposition Speichern";
CM_ SG_ 1178 FS_MMB_store_LED_on "LED für Speichern
";
CM_ SG_ 1178 FS_MMB_tast "Memoryverstellung im Tastbetrieb";
CM_ SG_ 1178 FS_MMB_tipp "Memoryverstellung im Tippbetrieb";
CM_ SG_ 1178 FS_SHV_aktiv "Verstellung Sitzhöhe

";
CM_ SG_ 1178 FS_Sitzfahrt_aktiv "Aktive Sitzfahrt Fahrersitz
";
CM_ SG_ 1178 FS_SLV_aktiv "Sitzlängsverstellung
";
CM_ SG_ 1178 FS_SNV_aktiv "Verstellung Sitzneigung
";
CM_ SG_ 1178 FS_Spezialposition_anfahren "paralell zu diesem Signal wird eine Botschaft auf den KCAN gesendet in der spezielle Anforderungen für den Empfänger stehen. 
Dieses Signal dient zusätzlich der Checksummenabsicherung bei einer Remotverstellung ";
CM_ SG_ 1178 FS_STV_aktiv "Verstellung Sitztiefe
";
CM_ SG_ 1178 Mem_FS_01_MQB_BZ "4bit Botschaftszähler, wird mit jeder Sendebotschaft inkrementiert";
CM_ SG_ 1178 Mem_FS_01_MQB_CRC "Für MLB:
Berechnung siehe Lastenheft 'Kommunikationsabsicherung für FlexRay und CAN'
Ab MQB und MLBevo:
Berechnung siehe Lastenheft 'End-to-End Kommunikationsabsicherung'

Endwerte siehe Begleitdokument 'S-PDU Kennungsfolgen'";

CM_ SG_ 1180 Mem_Taster_BT_01_BZ "4bit Botschaftszähler, wird in jeder Sendebotschaft inkrementiert";
CM_ SG_ 1180 Mem_Taster_BT_01_CRC "Für MLB:
'Berechnung siehe Lastenheft 'Kommunikationsabsicherung für FlexRay und CAN''

Ab MQB und MLBevo:
'Berechnung siehe Lastenheft 'End-to-End Kommunikationsabsicherung''

Endwerte siehe Begleitdokument 'S-PDU Kennungsfolgen'";
CM_ SG_ 1180 MTBT_M_Taste "Betätigung M-Taste BT";
CM_ SG_ 1180 MTBT_On_Off "Betätigung On-Off Taste BT";
CM_ SG_ 1180 MTBT_Pos1 "Betätigung Postionstaste 1 BT";
CM_ SG_ 1180 MTBT_Pos2 "Betätigung Postionstaste 2 BT";
CM_ SG_ 1180 MTBT_Pos3 "Betätigung Postionstaste 3 BT";
CM_ SG_ 1180 MTBT_Pos4 "Betätigung Postionstaste 4 BT";

CM_ SG_ 1170 Mem_Taster_FT_01_BZ "4bit Botschaftszähler, wird in jeder Sendebotschaft inkrementiert";
CM_ SG_ 1170 Mem_Taster_FT_01_CRC "Für MLB:
'Berechnung siehe Lastenheft 'Kommunikationsabsicherung für FlexRay und CAN''

Ab MQB und MLBevo:
'Berechnung siehe Lastenheft 'End-to-End Kommunikationsabsicherung''

Endwerte siehe Begleitdokument 'S-PDU Kennungsfolgen'";
CM_ SG_ 1170 MTFT_M_Taste "Betätigung M-Taste FT";
CM_ SG_ 1170 MTFT_On_Off "Betätigung On-Off Taste FT";
CM_ SG_ 1170 MTFT_Pos1_EE "Betätigung Postionstaste 1 FT";
CM_ SG_ 1170 MTFT_Pos2 "Betätigung Postionstaste 2 FT";
CM_ SG_ 1170 MTFT_Pos3 "Betätigung Postionstaste 3 FT";
CM_ SG_ 1170 MTFT_Pos4 "Betätigung Postionstaste 4 FT";
CM_ SG_ 1170 MTFT_Verst_akt "Mem Taster Verstellung aktiv";

CM_ SG_ 1173 BFS_Kopfstuetzen_hoch "Kopfstützen hoch (Wird bei Rechtslenker vom TSG HL gesendet)";
CM_ SG_ 1173 BFS_Kopfstuetzen_runter "Kopfstützen runter (Wird bei Rechtslenker vom TSG HL gesendet)";
CM_ SG_ 1173 BFS_Laengsverst_vor "Längsverstellung vor (Wird bei Rechtslenker vom TSG HL gesendet)";
CM_ SG_ 1173 BFS_Laengsverst_zurueck "Längsverstellung zurück (Wird bei Rechtslenker vom TSG HL gesendet)";
CM_ SG_ 1173 BFS_Lehnenkopf_vor "Lehnenkopf vor (Wird bei Rechtslenker vom TSG HL gesendet)";
CM_ SG_ 1173 BFS_Lehnenkopf_zurueck "Lehnenkopf zurück (Wird bei Rechtslenker vom TSG HL gesendet)";
CM_ SG_ 1173 BFS_Lehnenneigung_vor "Lehnenneigung vor (Wird bei Rechtslenker vom TSG HL gesendet)";
CM_ SG_ 1173 BFS_Lehnenneigung_zurueck "Lehnenneigung zurück (Wird bei Rechtslenker vom TSG HL gesendet)";
CM_ SG_ 1173 BFS_Sitzhoehe_hoch "Dient der Sitzhoehenverstellung des Beifahrersitzes aus dem Fond";
CM_ SG_ 1173 BFS_Sitzhoehe_runter "Dient der Sitzhoehenverstellung des Beifahrersitzes aus dem Fond";
CM_ SG_ 1173 MTHBF_BZ "4bit Botschaftszähler, wird in jeder Sendebotschaft inkrementiert
(Wird bei Rechtslenker vom TSG HL gesendet)
";
CM_ SG_ 1173 MTHBF_CRC "Für MLB:
'Berechnung siehe Lastenheft 'Kommunikationsabsicherung für FlexRay und CAN''

Ab MQB und MLBevo:
'Berechnung siehe Lastenheft 'End-to-End Kommunikationsabsicherung''

Endwerte siehe Begleitdokument 'S-PDU Kennungsfolgen'";
CM_ SG_ 1173 MTHBF_ein "Wird bei Rechtslenker vom TSG HL gesendet";

CM_ SG_ 1171 MF_Abzugssperre "Schlüsselabzugssperre";
CM_ SG_ 1171 MF_Alarm_Blinker "Taxialarmblinken, wie DWA ohne Fanfare";
CM_ SG_ 1171 MF_Alarm_Blinkertakt "Ansteuerung Blinker bei Alarm. Signal wird getaktet.
0 = Blinker für Alarm aus
1 = Blinker für Alarm ein";
CM_ SG_ 1171 MF_Anlassersperre "Notarzt 230V-Steckdose";
CM_ SG_ 1171 MF_Blk_li "Versehrte oder Fahrschule; Prio über Fernbedienung ein";
CM_ SG_ 1171 MF_Blk_re "Versehrte oder Fahrschule; Prio über Fernbedienung ein";
CM_ SG_ 1171 MF_BT_entriegeln "Beifahrertür entriegeln";
CM_ SG_ 1171 MF_BT_verriegeln "Beifahrertür verriegeln";
CM_ SG_ 1171 MF_Fahrlicht "statisch oder auch mit Blink_modi für interm.  Fahrlicht";
CM_ SG_ 1171 MF_Fernbed_ein "Fernbedienung für Petri+Lehr; Versehrte und Fahrschule";
CM_ SG_ 1171 MF_Fernlicht "Versehrte oder Fahrschule; Oder-Verknüpfung";
CM_ SG_ 1171 MF_FH_BT_hoch "Versehrte";
CM_ SG_ 1171 MF_FH_BT_tief "Versehrte";
CM_ SG_ 1171 MF_FH_FT_hoch "Versehrte";
CM_ SG_ 1171 MF_FH_FT_tief "Versehrte";
CM_ SG_ 1171 MF_Frontintervall "Versehrte oder Fahrschule; Oder-Verknüpfung";
CM_ SG_ 1171 MF_Frontwaschen "Versehrte oder Fahrschule; Oder-Verknüpfung";
CM_ SG_ 1171 MF_FT_entriegeln "Fahrertür entriegeln";
CM_ SG_ 1171 MF_FT_verriegeln "Fahrertür verriegeln";
CM_ SG_ 1171 MF_Fussraumbel "Fussraumbeleuchtung, Fahrschule";
CM_ SG_ 1171 MF_HBFS_entriegeln "Hinten Beifahrertür entriegeln";
CM_ SG_ 1171 MF_HBFS_verriegeln "Hinten Beifahrertür verriegeln";
CM_ SG_ 1171 MF_Heckintervall "Versehrte oder Fahrschule; Oder-Verknüpfung";
CM_ SG_ 1171 MF_Heckwaschen "Versehrte oder Fahrschule; Oder-Verknüpfung";
CM_ SG_ 1171 MF_HFS_entriegeln "Hinten Fahrertür entriegeln";
CM_ SG_ 1171 MF_HFS_verriegeln "Hinten Fahrertür verriegeln";
CM_ SG_ 1171 MF_Innenraumbel "sämtliche Beleuchtungen akitivieren (Fussraum, Tür u.a.)";
CM_ SG_ 1171 MF_Innenraumbel_Unterdrueck "Unterdrückung des Innenlichts/Fussraumbeleuchtung, sowie Schließblinken";
CM_ SG_ 1171 MF_interm_Fahrlicht "Ansteuerung intermittierendes Abblendlicht";
CM_ SG_ 1171 MF_interm_Fernlicht "mit Blink_modi für SoSi oder Taxialarm";
CM_ SG_ 1171 MF_interm_Takt "Taktung von intermittierenden Fernlicht/Fahrlicht bei einer Einsatzfahrt
0 = Licht aus
1 = Licht ein";
CM_ SG_ 1171 MF_Laderelais "Signal für die Auswertung zur Anzeige der Batterie-Schwach-Anzeige im Kombi";
CM_ SG_ 1171 MF_Lichthupe "Versehrte oder Fahrschule; Oder-Verknuepfung
";
CM_ SG_ 1171 MF_Motorweiterlauf "Motorstop Behoerdenfahrzeug";
CM_ SG_ 1171 MF_nachtr_Stopp_Anf "Dieses Signal dient dem Motor als Trigger, dass ein nachträglicher Motorstopp eingeleitet werden kann, wenn es die Bedingungen des StSt Koordinators dies zulassen.";
CM_ SG_ 1171 MF_Notstart "Signal zeigt an, dass ein Notstart über DBMC erfolgte.

Verwendung in Verbindung mit Signal MF_Variante = DBMC.";
CM_ SG_ 1171 MF_Schluessel_scan "Anforderung eines Innenraumscans - Schlüsselsuche";
CM_ SG_ 1171 MF_Signalhorn "Versehrte, Fahrschule oder Taxi (bei Alarm)";
CM_ SG_ 1171 MF_Standlicht "statisch oder auch mit Blink_modi für Taxialarm";
CM_ SG_ 1171 MF_StartStopp_Info "Stopp-Freigabe und Start-Anforderung an den Start-Stopp-Koordinator";
CM_ SG_ 1171 MF_Summer "Warnsummer für Funkhauptschalter und Fahrschulpedal";
CM_ SG_ 1171 MF_TFL_Abschaltung "Abschaltung des Tagfahrlicht
0 = keine Auswirkung
1 = Tagfahrlicht deaktiviert";
CM_ SG_ 1171 MF_Tippwischen "Versehrte oder Fahrschule; Oder-Verknüpfung";
CM_ SG_ 1171 MF_Tuerentriegelung_hinten "Bei von innen verriegelten Fahrzeug Türen hinten entriegeln
0 = keine Auswirkung
1 = Türen hinten entriegeln
";
CM_ SG_ 1171 MF_Variante "Sonderfahrzeugvariante
0 = keine Sonderfunktion 
1 = Sondersignalfahrzeug
2 = Taxi 
3 = Fahrhilfe 
4 = Fahrschule+Extra 
5 = SSF
6 =  DBMC
7 = Arbeitsmaschine";
CM_ SG_ 1171 MF_Warnblinker "Versehrte";
CM_ SG_ 1171 MF_Wischerstufe_1 "Versehrte oder Fahrschule; Oder-Verknüpfung";
CM_ SG_ 1171 MF_Wischerstufe_2 "Versehrte oder Fahrschule; Oder-Verknüpfung";
CM_ SG_ 1171 MF_ZV_Lock "Verriegelungsanforderung durch MFG analog Meldung einer Locktasterbetätigung durch TSG.";
CM_ SG_ 1171 MFG_01_BZ "4bit Botschaftszähler, wird in jeder Sendebotschaft inkrementiert
";
CM_ SG_ 1171 MFG_01_CRC "Für MLB:
'Berechnung siehe Lastenheft 'Kommunikationsabsicherung für FlexRay und CAN''

Ab MQB und MLBevo:
'Berechnung siehe Lastenheft 'End-to-End Kommunikationsabsicherung''

Endwerte siehe Begleitdokument 'S-PDU Kennungsfolgen'";

CM_ SG_ 1164 MF_2BatSOCzugering "Anzeige bei geringer Ladung der Zweitbatterie";
CM_ SG_ 1164 MF_2BattAb "Batterie Ab Warnung der Zweitbatterie";
CM_ SG_ 1164 MF_2BattHlkAnf "Anforderung einer HLK - Stufe an das BEM";
CM_ SG_ 1164 MF_2BattLadWarn "Anzeige das bei Motorlauf die Zweitbatterie entladen wird im KI";
CM_ SG_ 1164 MF_2BattLlaAnf "Anforderung einer Drehzahlanhebung an das BEM";
CM_ SG_ 1164 MF_2BattSpannungsAnf "Mindestspannugnsanforderung der Zusatbatterie an den BEM";
CM_ SG_ 1164 MF_Batteriediagnose "Erstellt für Zusatzbatterie Crafter";
CM_ SG_ 1164 MF_Blinker_L_Sta "Status Blinker links Sonderaufbauten";
CM_ SG_ 1164 MF_Blinker_R_Sta "Status Blinker rechts Sonderaufbauten";
CM_ SG_ 1164 MF_ExterneLadungWarn "Warnung bei Motorlauf das externer Ladestecker gesteckt ist im KI";
CM_ SG_ 1164 MF_Fahrerhinweis "Fahrerhinweis Kombiinstrument";
CM_ SG_ 1164 MF_Generatordiagnose "Neu erstellt für Crafter";
CM_ SG_ 1164 MF_Heck_entriegeln "Entriegelung Heck über KFG";
CM_ SG_ 1164 MF_Heck_verriegeln "Verriegelung Heck über KFG";
CM_ SG_ 1164 MF_interm_Nebelscheinwerfer "Intermittierender Nebelscheinwerfer bei einer Einsatzfahrt";
CM_ SG_ 1164 MF_Lampenausfall "Meldung Lampenausfall Aufbauhersteller";
CM_ SG_ 1164 MF_LSH_Abschaltstufe "Abschaltstufen der Luftstandheizung an der Zweitbatterie. Das Signal dient der Steuerung des Klima SG an der ersten Batterie und der LSH an der zweiten Batterie durch das Zweitbatterie Em im KFG";
CM_ SG_ 1164 MF_LSH_Einschaltverbot "Statussignal für das Einschaltverbot der Luftstandheizung an der Zweitbatterie, Steuerung durch das Zweitbatterie EM im KFG.
0 volle Verfuegbarkeit Standheizung/-lueftung
1 Standheizung/-lueftung nicht aktivierbar";
CM_ SG_ 1164 MF_LSH_Zielzeit "Definition der Zielzeit für die Luftstandheizung an der zweiten Batterie, Steuerung durch das Zweitbatterie EM im KFG.";
CM_ SG_ 1164 MF_NotStartAktiv "Anzeige Notstart Aktiv für den Zeitraum der Schließung des Notstartrelais";
CM_ SG_ 1164 MF_Radiomute "Wird bei Sonderfahrzeugen wie Polizei dafür verwendet, um das Radio bei einem eingehenden Funkspruch zu muten.";
CM_ SG_ 1164 MF_Relais_2_Batterie "Zeigt den Zustand des vom KFG angesteuerten Laderelais einer verbauten 2. Batterie an";
CM_ SG_ 1164 MF_Tuerverriegelung_hinten "Internes Verriegeln der hinteren Türen";
CM_ SG_ 1164 MF_ZV_Unlock "Globales entriegeln über KFG";
CM_ SG_ 1164 MFG_AppConnect_Anf "AppConnect Anforderung durch das KFG";
CM_ SG_ 1164 MFG_Infotainment_Autark "Das Signal gibt an ob die Energieversorgung für ein Infotainment im Fahrzeug Autarkbetrieb sichergestellt ist";
CM_ SG_ 1164 MFG_Klappe_Status "Einstellung der Luftklappenposition an der Luftstandheizung";
CM_ SG_ 1164 MFG_LSH_Ansteuerung "Ansteuerung LSH";
CM_ SG_ 1164 MFG_LSH_Betriebsdauer "Betriebsdauer LSH";
CM_ SG_ 1164 MFG_LSH_DBetr_Bestaet "Bestätigung des KFGs an die LSH, dass Dauerbetrieb tatsächlich angefordert ist.";
CM_ SG_ 1164 MFG_LSH_DBetr_Ein "Dauerbetrieb der Luftstandheizung Ein";

CM_ SG_ 2463978883 MF_DCDC_Istmodus "aktuelle Betriebsart des NV DC/DC Wandlers";
CM_ SG_ 2463978883 MF_Fahrerhinweis_2 "Fahrerhinweis Kombiinstrument für Camperfunktionen";
CM_ SG_ 2463978883 MF_I_U_VorgabeZwang "Ladestrom und Spannungsvorgabe sind als Zwangsvorgaben der Zusatzbatterie zu behandeln";
CM_ SG_ 2463978883 MF_U2Batt "Spannung der Zweitbatterie";
CM_ SG_ 2463978883 MF_UBattVorgabe "Ladespannungsempfehlung Zusatz Batterie";
CM_ SG_ 2463978883 MF_Vorfeldbel_Spiegel "Schaltet die Vorfeldbeleuchtung der Außenspiegel";

CM_ SG_ 1471 MFL_Eventcode_1 "Siehe Q-LAH MFL-Protokoll";
CM_ SG_ 1471 MFL_Eventcode_2 "Siehe Q-LAH MFL-Protokoll";
CM_ SG_ 1471 MFL_Marke "Marke für markenspezifische Variantennummer des MFL";
CM_ SG_ 1471 MFL_Tastencode_1 "Beschreibt die Funktion einer fest zugeordneten Taste/Walze auf dem MFL. Bei Betätigung ändert sich der Wert von 0x0 auf den jeweiligen Tastencode.";
CM_ SG_ 1471 MFL_Tastencode_2 "Beschreibt die Funktion einer fest zugeordneten Taste/Walze auf dem MFL. Ist MFL_Tastencode_1 wegen Betätigung einer Taste/Walze bereits mit einem Wert ungleich 0x0 belegt, so ändert sich bei Betätigung einer weiteren Taste/Walze der Wert dieses Signals v";
CM_ SG_ 1471 MFL_Variante "Markenspezifische Variantennummer des MFL";

CM_ SG_ 2463978865 FaceRec2_Status_Challenge_Req "When IAA receives this signal it will provide a challenge via FaceRec2_Status_Challenge.

Duplicate of FaceRec signals for usage in separate messages using not SOK but own application level protection.";
CM_ SG_ 2463978865 FaceRec_Auth_Challenge_Request "When IAA receives this signal it will provide a challenge via SOK_FR_Auth_NAD_Challenge.";
CM_ SG_ 2463978865 MIK_01_BZ "4bit Botschaftszähler, wird mit jeder Sendebotschaft inkrementiert";
CM_ SG_ 2463978865 MIK_01_CRC "Für MLB:
Berechnung siehe Lastenheft 'Kommunikationsabsicherung für FlexRay und CAN'
Ab MQB und MLBevo:
Berechnung siehe Lastenheft 'End-to-End Kommunikationsabsicherung'

Endwerte siehe Begleitdokument 'S-PDU Kennungsfolgen'";
CM_ SG_ 2463978865 MIK_BlinkRate "Number of blinks detected within a fixed time window.";
CM_ SG_ 2463978865 MIK_CabinCare_Active "MIK ECU to HMI to transmit the de-/activation by the customer.";
CM_ SG_ 2463978865 MIK_CabinCare_state "current state of the cabin care function";
CM_ SG_ 2463978865 MIK_ChildPresence "child presence signal";
CM_ SG_ 2463978865 MIK_ChildStatus "child status signal";
CM_ SG_ 2463978865 MIK_DetectionMode "Indicates whether head pose, gaze, or a combination of head pose and gaze is used for visual perception estimation.";
CM_ SG_ 2463978865 MIK_DriverChange "Determines whether a driver change has been detected.";
CM_ SG_ 2463978865 MIK_DriverPresence "Determines whether a driver has been detected on the driver seat and whether the driver is buckled up.";
CM_ SG_ 2463978865 MIK_DriverSmoking "Determines whether the driver is smoking.";
CM_ SG_ 2463978865 MIK_DriverSmokingQual "Confidence factor of signal MIK_DriverSmoking.";
CM_ SG_ 2463978865 MIK_DriverSpeaking "Determines whether the driver is speaking.";
CM_ SG_ 2463978865 MIK_DriverTelephoneUsage "Determines whether the driver use continuously the mobile phone.";
CM_ SG_ 2463978865 MIK_DriverTelephoneUsageQual "Confidence factor of signal MIK_DriverTelephoneUsage.";
CM_ SG_ 2463978865 MIK_DriverYawning "Determines whether the driver is yawning.";
CM_ SG_ 2463978865 MIK_DriverYawningQual "Confidence factor of signal MIK_DriverYawning.";
CM_ SG_ 2463978865 MIK_DrowsinessLevel "Camera-based drowsiness level of the driver.";
CM_ SG_ 2463978865 MIK_DrowsinessLevelQual "Confidence factor of signal MIK_DrowsinessLevel.";
CM_ SG_ 2463978865 MIK_DurEyesCl "Duration the driver's eyes have been continuously closed.";
CM_ SG_ 2463978865 MIK_DurEyesNotOnTfc "Duration the driver has continuously not paid attention to traffic.";
CM_ SG_ 2463978865 MIK_Fahrer_erkannt "Erkennung der Anwesenheit einer Person auf der Fahrerseite vorne durch die MIK.";
CM_ SG_ 2463978865 MIK_FakeDetected "Indicates whether or not the driver monitoring system has detected an attempt at deception (e.g. masks).";
CM_ SG_ 2463978865 MIK_ICC_RemoteAccessStatus "This signal is needed to report the state of remote access (init,enabled, disabled)";
CM_ SG_ 2463978865 MIK_ICV_AspectRatio "This signal is needed to report the image and video's aspect ratio(init, 4:3, 16:9, 3:4, 9:16)";
CM_ SG_ 2463978865 MIK_ICV_Brightness "MIK_ICV_Brightness
the brightness of the videostream shall be configurable (0....100%)";
CM_ SG_ 2463978865 MIK_ICV_ColorMode "The color mode of the videostream shall be configurable (init, RGB, IR)";
CM_ SG_ 2463978865 MIK_ICV_Contrast "the contrast of the videostream shall be configurable [0...100%]";
CM_ SG_ 2463978865 MIK_ICV_FieldOfView "MIK_ICV_FieldOfView is needed to report the selected field of view (driver, CoDriver and fullCabine)";
CM_ SG_ 2463978865 MIK_ICV_FrameRate "MIK_ICV_FrameRate [15...30 frames per second]";
CM_ SG_ 2463978865 MIK_ICV_FunctionState "MIK_ICV_FunctionState is needed to report the current state of the MIK
(started, shutDown or error)";
CM_ SG_ 2463978865 MIK_ICV_HDR "The HDR (High Dynamic Range Image) of the videostream shall be configurable (init, on, off).";
CM_ SG_ 2463978865 MIK_ICV_Resolution "the resolution of the videostream shall be configurable 160x120, 320x240, 640x480,1280x720, 1920x1080";
CM_ SG_ 2463978865 MIK_ICV_VideoLength "This signal is needed to report the short video length to fits the social media directly. e.g. Tiktok, wechat. (init, 15s, 30s, 60s, customized)";
CM_ SG_ 2463978865 MIK_ICV_Videostream_State "MIK_ICV_Videostream_State is needed to report the state of the videostream.";
CM_ SG_ 2463978865 MIK_ICV_VideostreamResult "MIK_ICV_VideostreamResult is needed to provide the result of the videostream
(started, cancelled or freezed)";
CM_ SG_ 2463978865 MIK_LeftHandPos "Determines the most likely area of the driver´s left hand.";
CM_ SG_ 2463978865 MIK_LeftHandPosQual "Confidence factor of signal MIK_LeftHandPos.";
CM_ SG_ 2463978865 MIK_Microsleep "Camera-based microsleep detection.";
CM_ SG_ 2463978865 MIK_MicrosleepQual "Confidence factor of signal MIK_Microsleep.";
CM_ SG_ 2463978865 MIK_PassengerPresence "Determines whether passengers have been detected in the car.";
CM_ SG_ 2463978865 MIK_PercentageEyesOnTraffic "Relative duration the driver has monitored the traffic within a fixed time window.";
CM_ SG_ 2463978865 MIK_PetPresence "pet presence signal";
CM_ SG_ 2463978865 MIK_PetsMode_Active "MIK ECU to HMI to transmit the de-/activation by the customer.";
CM_ SG_ 2463978865 MIK_RightHandPos "Determines the most likely area of the driver´s right hand.";
CM_ SG_ 2463978865 MIK_RightHandPosQual "Confidence factor of signal MIK_RightHandPos.";
CM_ SG_ 2463978865 MIK_Selfie_FunctionState "This signal is needed to report the Selfie function state(init, VideoShot_Start, VideoShot_Stop, PhotoShot_Single, PhotoShot_Continuous, Cancel, Error)";
CM_ SG_ 2463978865 MIK_Selfie_Resolution "This signal is needed to report the image's resolution (int, 5M pixels, 2M pixels)";
CM_ SG_ 2463978865 MIK_SpaAttDstrAr_01 "Spatial Attention Distribution Area 1: Most likely Area of Interest the driver is currently looking at.";
CM_ SG_ 2463978865 MIK_SpaAttDstrProb_01 "Spatial Attention Distribution Probability 1: Probability the driver is currently looking at the Area of Interest given in signal 'MIK_SpaAttDstrAr_01'.";
CM_ SG_ 2463978865 MIK_Status "General status of the driver monitoring system.";
CM_ SG_ 2463978865 MIK_TotDurEyesNotOnTfc "Total duration the driver has not paid attention to traffic within a fixed time window including both continuous glances and short glances.";
CM_ SG_ 2463978865 MIK_UnusualHeadPose "Determines whether the driver's head is detected to be in an unusual pose.";
CM_ SG_ 2463978865 MIK_UnusualHeadPoseQual "Confidence factor of signal MIK_UnusualHeadPose.";
CM_ SG_ 2463978865 MIK_VisualDistractionLevel "Camera-based visual distraction of the driver.";
CM_ SG_ 2463978865 MIK_VisualDistractionLevelQual "Confidence factor of signal MIK_VisualDistractionLevel.";

CM_ SG_ 2527679795 MKGO_FBS_01 "NFC Kommunikation  MKGO zu FBS";

CM_ SG_ 2527679796 MKGO_FBS_02 "NFC Kommunikation  MKGO zu FBS";

CM_ SG_ 2527679797 MKGO_FBS_03 "NFC Kommunikation  MKGO zu FBS";

CM_ SG_ 2527679798 MKGO_FBS_04 "NFC Kommunikation  MKGO zu FBS";

CM_ SG_ 2527679799 MKGO_FBS_05 "NFC Kommunikation  MKGO zu FBS";

CM_ SG_ 263 MO_Anzeigedrehz "Optimierte Anzeigedrehzahl wegen sportlicherem Drehzahlmesser im Kombi. 
Bei Parallelhybrid: Anzeige VKM- Drehzahl nach Anzeigekonzept

Hinweis: Ehemaliger Fehlerwert 0xFFF wird senderseitig nicht unterstützt. Diesen Wert aus Kompatibilitätsgründen nic";
CM_ SG_ 263 MO_Effizienzmodus "Bei Handschaltern wird  das Fahrprogramm Effizienz signalisiert. 
Bei Automatikgetrieben wird das Fahrprogramm 'D' durch 'E' ersetzt.";
CM_ SG_ 263 MO_Fehler_Oeldrucksensor "Steuert  im Kombiinstrument die gelbe zentrale Warnlampe und das Symbol 'gelbe Ölkanne'  mit der Textmeldung 'Sensorfehler: Werkstatt aufsuchen' an
";
CM_ SG_ 263 MO_Istgang "Aktueller Gang für Anzeige Hochschaltempfehlung (gültig, wenn MO_Schaltempf_verfbar = 1).

Anzeige im Kombi:
Sollgang == Istgang         ==> Anzeige Istgang
Sollgang !=   Istgang         ==> Schaltempfehlung
Sollgang == Istgang == 0 ==> keine Anzeige";
CM_ SG_ 263 MO_KVS "Motorsteuergerätinterner Verbrauchszähler, der vom Kombi zyklisch ausgelesen wird, um die Einspritzmenge zur Verbrauchsmessung aufzusummieren; aus diesem Zählerstand werden Momentan- und Durchschnittsverbrauch berechnet; das Überlauf-Bit ist zu berücksich";
CM_ SG_ 263 MO_KVS_Ueberlauf "Der motorsteuergeräteinterne Verbrauchszähler ist mindestens einmal übergelaufen. Dieses Bit wird genutzt, um erkennen zu können, daß das Motorsteuergerät aus dem Reset-Zustand hochläuft.";
CM_ SG_ 263 MO_Ladedruck "absoluter Ladedruck";
CM_ SG_ 263 MO_Oeldruck "Öldruck analog zur Anzeige";
CM_ SG_ 263 MO_rel_Ladedruck "relativer Ladedruck (für Boostanzeige)";
CM_ SG_ 263 MO_Schaltempf_verfbar "Info, ob Schaltempfehlung im Fzg. verfügbar. Statischer Wert, ändert sich für ein Fzg. nicht!";
CM_ SG_ 263 MO_Sollgang "Motor sendet den Sollgang in den der Fahrer schalten soll. Wird im Kombi als Hochschaltempfehlung hervorgehoben (gültig, wenn MO_Schaltempf_verfbar = 1).

Anzeige im Kombi:
Sollgang == Istgang          ==> Anzeige Istgang
Sollgang !=  Istgang         ";

CM_ SG_ 1600 MO_Absperrventil_oeffnen "Signal an Klima-SG das Absperrrventil anzusteuern. Ab D4 auch 0x3 Ventil_schließen.

Im MQB wird hier der Soll-Status des Absperrventils ausgegeben.
Achtung: bei z. B. klemmendem Ventil entspricht das Signal nicht dem tatsächlichen Status!";
CM_ SG_ 1600 MO_aktives_Getriebeheizen "Information für Getriebe, ob ein Ventil für Getriebheizen angesteuert werden muss";
CM_ SG_ 1600 MO_Ansaugluft_Temp "In Fahrzeugen ohne Außentemperatur vom Kombi kann aus der Ansauglufttemperatur auf die Außentemperatur geschlossen werden. Beim SDI ist das mit einer gewissen Genauigkeit gegeben. Genutzt wird es vom ASG.";
CM_ SG_ 1600 MO_Getriebe_kuehlen "Anforderung Getriebekühlventilansteuerung";
CM_ SG_ 1600 MO_Heizungspumpenansteuerung "Anforderung Heizungspumpenansteuerung
MQB und Hybrid: Status der Heizungsunterstützungspumpe am MSG
";
CM_ SG_ 1600 MO_Hoeheninfo "Korrekturfaktor Höhe (1 entspricht 1013 mbar)";
CM_ SG_ 1600 MO_HYB_Fehler_HV_Netz "Im HV-Bordnetz ist fehlerbedingt kein generatorischer Betrieb möglich. Das 12V-Bordnetz wird über den DC/DC-Wandler allein aus der Traktionsbatterie gespeist. Um diesen Zustand möglichst lange aufrechterhalten zu können, sollten Komfort-Verbraucher abgesc";
CM_ SG_ 1600 MO_Kennfeldk "Die Kennfeldkühlung ist in diesem Fahrzeug verbaut und hat keinen Systemfehler";
CM_ SG_ 1600 MO_KL15_Abschaltempfehlung "Kessy Abschaltempfehlung nach Verlassen des Fahrzeugs";
CM_ SG_ 1600 MO_Kuehlmittel_Temp "Kuehlmitteltemperatur";
CM_ SG_ 1600 MO_Mom_Traegheit_02 "Massenträgheit (J) der Motors bzw. der Antriebsmaschinen in kgm².

Zur Berücksichtigung des E-Motor in Hybrid-Projekten:
in MLB-Projekten wird nur der J-Wert des Verbrennungsmotors und nicht der J-Wert des E-Motors berücksichtigt.
In MQB/MLBevo-Projek";
CM_ SG_ 1600 MO_Nachlaufzeit_Heizungspumpe "Nachlaufzeit für Heizungspumpe für Turboladerschutz";
CM_ SG_ 1600 MO_Oel_Temp "Realer Meßbereich ca. -40..150 Grad";
CM_ SG_ 1600 MO_QBit_Ansaugluft_Temp "
";
CM_ SG_ 1600 MO_QBit_Hoeheninfo "Qualifizierungsbit der Höheninfo. Gesetzt bei Ersatzwert, Init oder Fehler.";
CM_ SG_ 1600 MO_QBit_Kuehlmittel_Temp "
";
CM_ SG_ 1600 MO_SpannungsAnf "Forderung des Motor-SGs zur Spannungsanhebung";
CM_ SG_ 1600 MO_Versionsinfo_02 "Versioninformation vom Motor zur Steuerung bei inkompatiblen KMatrix-Änderung bzw. Einführung von neuen Funktionen, die in den Empfängern verriegelt werden müssen. Zu jedem Ereignis wird ein fixer Zählerstand zugeordnet, um dem Empfänger die funktionale Ä";

CM_ SG_ 958 MO_Aussp_Anlass "Das Signal zeigt an, ob die Wiederholstartsperre aktiv ist. D. h. eine Ansteuerung des Anlassers wird auch bei erfüllten Startvoraussetzungen (HS: Interlock betätigt bzw. AT: P/N eingelegt und Bremse betätigt) nicht erfolgen.";
CM_ SG_ 958 MO_BKV_Unterdruckwarnung "Über die Unterdruckwarnung signalisiert das MSG dem ESP, dass kein ausreichender Unterdruck für den BKV zur Verfügung gestellt werden kann.";
CM_ SG_ 958 MO_BLS "Ungefiltertes Rohsignal des Bremslichtschalters, nur wenn HW-Eingang bestückt und ausgewertet wird. Bei Motoren ohne genutzten HW-Eingang wird kein Ersatzwert (bspw. SW-Signal über CAN) ausgegeben!
Bei AUDI muss das Signal wg. Bremslichtfunktion immer be";
CM_ SG_ 958 MO_BMS_NV_Anf_stuetzen "Garantierte Unterstützung des Zusatzspeichers ist erforderlich. Zusatzspeicher muss an das Versorgungsnezt angebunden werden. ";
CM_ SG_ 958 MO_EKlKomLeiRed "Anforderung an die Klimasteuerung, die Leistungsaufnahme des E-Kompressors bei schlechtem SOC und in bestimmten Fahrsituationen zu begrenzen. (Das bereits bestehende Signal 'Klimakompressor aus' als stets umzusetzende Anforderung bleibt unverändert besteh";
CM_ SG_ 958 MO_Ext_E_Fahrt_aktiv "Funktionsrückmeldung zum erw. E-Fahr-Betrieb über Lampe/LED im E-Mode-Taster";
CM_ SG_ 958 MO_Fahrer_bremst "Redundante Bremsinformation vom Motor.

MLB:
AUDI D4: Zykluszeit: 10ms (siehe Zykluszeit schnell/Cycletime Fast)
Im AUDI B8 wird in diesem Bit der Wert der ESP-CAN-Information 'ESP_Fahrer_bremst' ausgegeben.

Achtung:
Reduktion der Zykluszeit Motor";
CM_ SG_ 958 MO_FMAus_aktiv "Das Signal gibt Rückmeldung ob Freilauf Motor aus aktiv ist. Beleibt auch 0km/h (unterhalb der StartStopp Schwelle) weiterhin aktiv.";
CM_ SG_ 958 MO_FMAus_Startvariante "Startvariante beim Motorstart aus der Freilauf-Motor-AUS Phase";
CM_ SG_ 958 MO_Freig_Anlass "Bit wird gesetzt, wenn der Motor beim Automatikstart gestartet werden darf (Motorstillstand, Emissionsmaßnahmen sind erfüllt).";
CM_ SG_ 958 MO_Freig_Reku "Empfehlung des Motor-SG's zur Spannungsabsenkung/-anhebung für den Rekuperationsbetrieb";
CM_ SG_ 958 MO_Freigabe_Segeln "Freigabebit des Segelbetriebs im Getriebe. Bedingt durch bestimmte Diagnosen und Adaptionen des MSGs, die nur im Schub möglich sind, darf nicht jede Schubphase für einen Segelbetrieb genutzt werden. Eine Freigabe bleibt auch außerhalb einer Schubphase bes";
CM_ SG_ 958 MO_Gangposition "MLB:
Stellung des Wählhebels in der Schaltgasse des Handschaltgetriebes.
MLBevo: 
Ausweitung der Bedienung auch auf Automatikgetriebe;
Routing des Signals GE_Fahrstufe: 
1. Position_R (dez. 6) auf MO_Gangposition: Gang_R (dez. 13) wegen Entfall Signa";
CM_ SG_ 958 MO_Handshake_STH "Es gilt: Signalspec MO_Handshake v1.0

Handshake zwischen MSG und STH. Wenn das MSG die EKP aufgrund einer STH-Anforderung ansteuert und kein Fehlereintrag bzgl. EKP/KPE/NDR vorliegt, wird das Bit gesetzt.";
CM_ SG_ 958 MO_HYB_Fahrbereitschaft "Signal steuert u.a. in der Lenkhilfe zusammen mit weiteren Informationen den Modewechsel in den 'Drivemode'
Grüne Anzeige im Kombiinstrument zur Signalisierung der Bereitschaft des Hybridsystems.";
CM_ SG_ 958 MO_HYB_VM_aktiv "0 = VMotor wird nicht aktiv gehalten (nVM < n_min und keine LL-Regelung aktiv)
1 = VMotor aktiv (ab der ersten Einspritzung; gilt auch für Schubbetrieb, wenn VMotor spätestens durch LLRegelung befeuert würde)
Verwendet zur Bestimmung des Ist-Zustandes";
CM_ SG_ 958 MO_Interlock "Das Motorsteuergerät gibt die Information aus, ab wann der Kupplungsschalter durch das Motorsteuergerät als getreten gesehen wird.
Bei Systemen für Start Stopp muss das Interlocksignal für einen Start durch das MSG generiert werden, sobald der Schalthebe";
CM_ SG_ 958 MO_Kickdown "Es gilt: Signalspec MO_Kickdown v1.0";
CM_ SG_ 958 MO_Kl_50 "Klemme 50: Startausführung durch Ritzelstarter

MLB: nicht von allen Motoren gesendet
MQB/MLBevo: gesendet von allen Motoren";
CM_ SG_ 958 MO_Kl_75 "Klemme X
";
CM_ SG_ 958 MO_Klima_Eingr "Eingriffe des Motor bei der Klima";
CM_ SG_ 958 MO_Konsistenz_Bremsped "MLB:

AUDI D4: Zykluszeit: 10ms (siehe Zykluszeit schnell/Cycletime Fast)
Siehe 'Funktionsspezifikation Bremslichtinfo B8'

Achtung:
Reduktion der Zykluszeit Motor_03 auf 10ms geplant.
Projektabhängig soll künftig mit 10ms gesendet werden.
Empfäng";
CM_ SG_ 958 MO_Kuppl_schalter "MLB:
Das Motorsteuergerät gibt die Information aus, ab wann der Kupplungsschalter durch das Motorsteuergerät als getreten gesehen wird
0x0: Schalter sagt betätigt (Ausgekuppelt)
0x1: Schalter sagt nicht betätigt (Eingekuppelt)

MQB:
Nur Handschalter";
CM_ SG_ 958 MO_Motor_laeuft "Das Motorsteuergerät gibt die Information aus, ab wann der Motor verbrennungsbedingt autark läuft und durch zuschaltbare Nebenaggregate mechanisch belastbar ist (z.B. durch Generator, Klimakompressor, etc.).

Die 'Motor läuft' Information wird ausgegebe";
CM_ SG_ 958 MO_PTC_Status "Status-Rückmeldung vom MSG zum aktuellen PTC-Status (stufiges PTC, Relais am MSG). Bei Ansteuerung eines stufigen PTC durch ein anderes SG beschreibt das Signal die vom MSG freigegebene PTC-Stufe.";
CM_ SG_ 958 MO_QBit_Fahrer_bremst "MLB:
AUDI D4: Zykluszeit: 10ms (siehe Zykluszeit schnell/Cycletime Fast)

Achtung:
Reduktion der Zykluszeit Motor_03 auf 10ms geplant.
Projektabhängig soll künftig mit 10ms gesendet werden.
Empfänger die in weiteren Konzern-Projekten eingesetzt werd";
CM_ SG_ 958 MO_QBit_Gangposition "Qualitätsbit zum Signal MO_Gangposition";
CM_ SG_ 958 MO_QBit_KL_75 "Q - Bit für das KL 75 Signal zur Vermeidung der fehlerhaften Erkennung von Motorstarts. 
Wird auf 1 gesetzt, solange das Motorsteuergerät KL15 = AUS erkannt hat.";
CM_ SG_ 958 MO_Remotestart_Betrieb "Das MSG ist für den Remotestart-Betrieb bereit. Nach Empfang der Motorstartanforderung für RSt-Betrieb durch BCM wird der Fahrzeugmotor gestartet und solange der Motor läuft, bleibt dieses Bit aktiv. Dieses Signal ist nur zur Verwendung durch das BCM zur ";
CM_ SG_ 958 MO_Remotestart_moeglich "Wenn Bit gesetzt, würde das MSG bei entsprechender Anforderung durch das BCM den Remotestartbetrieb einleiten, d.h. das MSG ist remotestartfähig und es liegen aktuell keine relevanten Fehler oder andere Abbruchgründe vor.";
CM_ SG_ 958 MO_Signalquelle_Gangposition "Signalquelle des Signals MO_Gangposition
0: Signalquelle Gangpositionssensor
1: Signalquelle Modellwert (v/n)";
CM_ SG_ 958 MO_StartStopp_Fahrerwunsch "Fahreraktivität Start/Stop";
CM_ SG_ 958 MO_StartStopp_Motorstopp "Motor-Stopp durch Start/Stopp-Koordinator
HYBRID:
Wenn MO_Hybridfahrzeug = 1 gilt:
Verbrennungsmotor durch Hybrid-Koordinator im MSG ausgeschaltet. 
Die definierten Start/Stopp-Signale beziehen sich nur auf den Verbrennungsmotor!";
CM_ SG_ 958 MO_StartStopp_Status "Aktivitätsstatus Start/Stopp-Koordinator
HYBRID:
Wenn MO_Hybridfahrzeug = 1 gilt:
Signal bezieht sich nur auf den Verbrennungsmotor, nicht auf den Hybridantrieb
";
CM_ SG_ 958 MO_StartStopp_Wiederstart "Motorwiederstart durch Start/Stopp-Koordinator
HYBRID:
Wenn MO_Hybridfahrzeug =1 gilt:
Warnung vor Spannungseinbruch beim Zustart des Verbrennungsmotors. 
-nicht relevant, da derzeit kein Start über 12V-Starter geplant-
Dieses Signal wird nur vom Hyb";
CM_ SG_ 958 MO_StartVorauss_erfuellt "Dient der Fallunterscheidung bei ZAT-Betätigung im Zustand 'KL15 ein' (bei nicht gesetztem Signal folgt KL15 aus, bei gesetztem Signal folgt setzen KL50-Anf.)

0: Signal nicht bedient 
1: Voraussetzungen zur Antriebsstrangaktivierung / Startvoraussetzu";
CM_ SG_ 958 MO_Timeout_ESP "500 ms Timeout auf Bremsen-Botschaft ist >= 1 mal aufgelaufen, Löschen des Bits nach Neustart (KL15).

MLB:
AUDI D4: Zykluszeit: 10ms (siehe Zykluszeit schnell/Cycletime Fast)

Achtung:
Reduktion der Zykluszeit Motor_03 auf 10ms geplant.
Projektabh";
CM_ SG_ 958 MO_Zylinderabschaltung "Status Zylinderabschaltung Motor";
CM_ SG_ 958 Motor_14_CRC "Ab MQB und MLBevo:
'Berechnung siehe Lastenheft 'End-to-End Kommunikationsabsicherung'

Endwerte siehe Begleitdokument 'S-PDU Kennungsfolgen'";

CM_ SG_ 1648 MO1_Freigabe_Info_WFS "WFS-Freigabeinformation";
CM_ SG_ 1648 MO1_Freigabe_Verfallsinfo_WFS "WFS-Freigabeverfallsinformation";
CM_ SG_ 1648 MO1_Sperr_Info_WFS "WFS-Sperrinformation";
CM_ SG_ 1648 MO_Abstellzeit "Abstelldauer nach letztem KL15 aus

Hinweis: 
Ehemaliger Fehlerwert 0xFF wird senderseitig nicht unterstützt. 
Diesen Wert aus Kompatibilitätsgründen nicht neu belegen!";
CM_ SG_ 1648 MO_Abstellzeit_Status "Statusinformation zur Abstellzeit
0: Die dem Status zugeordnete Variable konnte noch nicht berechnet werden. 
1: Die dem Status zugehörige Variable wurde korrekt berechnet. 
2: Der Wert der zugehörigen Variablen ist nur ein Minimalwert. 
3: Der Wert d";
CM_ SG_ 1648 MO_ANC_Kennfeld_Anf "Anforderung ANC Kennfeldumschaltung";
CM_ SG_ 1648 MO_Anzahl_Abgesch_Zyl "Gibt die Anzahl der abgeschalteten Zylinder an. In Übergangszuständen wird der Zielbetriebszustand angezeigt.";
CM_ SG_ 1648 MO_Bremslicht_Reku "Bremslicht (ggf. bei Rekuperation durch E-Motor) wird angesteuert";
CM_ SG_ 1648 MO_Drehzahl_Warnung "Warnhinweis zum Kombi im Fall einer fehlerbehafteten Drehzahlbegrenzung";
CM_ SG_ 1648 MO_EPCL "Die Anforderung der EPC-Lampe vom MSG ans Kombi soll durch das Bus-Signal MO_EPCL gemäß folgender Logik erfolgen:
MO_EPCL = 0 dez -> EPC Lampe aus, kein Text
MO_EPCL = 1 dez -> gelbe EPC-Symbolik, Text „Antrieb: Störung! Bitte Service aufsuchen“
MO_EPC";
CM_ SG_ 1648 MO_Ethanol_BS_Texte "Ethanol Brennstoff-Texte im Kombi

0 = kein Text
1 = E85 Warm_Up
2 = FlexFuel Warnung 3.Stufe (Too cold for ethanol)
3 = Warmfahrempfehlung MQB / FlexFuel Warnung 1.Stufe (Refuel with gasoline)
4 = FlexFuel Warnung 2. Stufe (Refuel with gasoline)
5";
CM_ SG_ 1648 MO_Fahrzeugtyp "Unterscheidet die Fahrzeugtypen bzgl. der Antriebsart";
CM_ SG_ 1648 MO_Fehler_Zylabsch "Fehlerstatus der Funktion Zylinderabschaltung ";
CM_ SG_ 1648 MO_Hybrid_StartStopp_LED "Ansteuerung der Funktions-LED der Hybrid Taste bzw. Start/Stop Deaktivierungstaste.
Der Start/Stopp-Master (derzeit im MSG) (oder ein künftiger Hybrid-Master) soll die Ansteuerung senden.";
CM_ SG_ 1648 MO_max_Ladedruck "maximal möglicher Ladedruck (zur Anpassung des Anzeigebereichs bei absoluter Ladedruckanzeige)";
CM_ SG_ 1648 MO_NMAX_Schaltanzeige "Maximaldrehzahl für Schaltanzeige";
CM_ SG_ 1648 MO_obere_Drehzahlgrenze "obere Drehzahlgrenze des Motors";
CM_ SG_ 1648 MO_StartStopp_PopUp "Das Signal zeigt an, ob der StSt-Status mittels Deaktivierungstaster geändert wurde. Ein Wechsel auf die Werte 01 oder 10 löst im Kombi ein entsprechendes PopUp aus. Bei einem Statuswechsel durch andere Signalquellen (z.B. Charisma, fehlerbedingte Abschal";
CM_ SG_ 1648 MO_Zylabsch_Texte "Zylinderabschaltung mode in Kombi, fuer Zylinderabschaltung";
CM_ SG_ 1648 MO_Zylabsch_Texte_02 "ZAS-Anzeige für den Fahrer im Kombi
0: kein ZAS (generell keinerlei ZAS-Anzeigen)  (Init für nicht ZAS-Motor)
1: ZAS im Vollmotorbetrieb  (Init für ZAS-Motor)
2: ZAS im Abschaltbetrieb: 1 Zyl aktiv
3: ZAS im Abschaltbetrieb: 2 Zyl aktiv
4: ZAS im Abs";

CM_ SG_ 967 MO_E_Mode "Anforderung der E-Mode Statusanzeige";
CM_ SG_ 967 MO_E_Texte "Anforderung von Hinweistexten des E-Systems separat für HEV/BEV bzw. erweiterbar für PHEV";
CM_ SG_ 967 MO_E_Warnungen "Anforderung von Warnanzeigen des E-Systems separat für HEV/BEV bzw. erweiterbar für PHEV";
CM_ SG_ 967 MO_EFLEX_Lampe "Um ein Starten mit E100 zu ermöglichen, wird Kraftstoff ggf. vorgeheizt. Das Signal dient der Anzeige des Heizungsstatus.

Heizung aus -> Lampe aus
Heizung ein -> Lampe ein
Heizung ein und Startversuch -> Lampe blinkend
Heizung nicht möglich -> Lampe";
CM_ SG_ 967 MO_Heissleuchte "Ansteuerung der Kühlwassertemperatur-Heißleuchte (Sensor nur noch am Motorsteuergerät): Temperaturschaltschwellen mit Hysterese (bei VW D1/Colorado Kombi derzeit noch nicht genutzt).";
CM_ SG_ 967 MO_ITM_Warnung_Pumpe "Textanzeige: 'Motor sofort abstellen, geschaltete Wasserpumpe defekt / klemmt'";
CM_ SG_ 967 MO_KJS_nicht_bereit "Dieses Signal zeigen einen Fehler der Kühlerjalousie mit unbekannter Stellung der Lamellen. ";
CM_ SG_ 967 MO_Kuehlerluefter_1 "Ansteuertastverhaeltnis (PWM) der Kuehlerluefterendstufe 1";
CM_ SG_ 967 MO_Kuehlerluefter_2 "Ansteuertastverhaeltnis (PWM) der Kuehlerluefterendstufe 2";
CM_ SG_ 967 MO_Kuehlerluefter_MUX "Multiplexer für das Signal 'MO_Kuehlerlüfter'";
CM_ SG_ 967 MO_OBD2_Lampe "OBD bzw. MIL-Lampe wird vom Motorsteuergerät angesteuert, die Information im Signal GE_OBD_Status wird vom Motorsteuergerät an das Kombi weitergereicht";
CM_ SG_ 967 MO_Oelwarnung_max "Ölstandswarnung mit der Aufforderung zum Ölwechsel.
Hintergrund: Bei Kraftstoffeintrag (B20) ins Öl verbleibt der RME-Anteil irreversibel im Öl.";
CM_ SG_ 967 MO_Partikel_Lampe "Partikelfilter-Lampe wird eingeschaltet";
CM_ SG_ 967 MO_RedFahrleistung_Lampe "Ansteuerung der Turtle-Mode Lampe für E-Traktion Fahrzeuge";
CM_ SG_ 967 MO_Systemlampe "EGas Systemlampe (EPC) oder Vorglühlampe im Kombi, Kombi steuert immer gleiche
LED an, nur über Ziffernblatt wird die EPC von der Vorglühlampe differenziert";
CM_ SG_ 967 MO_Tankdeckel_Lampe "Ansteuerung Tankdeckel-Warnlampe Kombiinstrument (nur Ottomotoren) z.Zt. Vorhalt VW";
CM_ SG_ 967 MO_Text_Motorstart "Anzeigetexte für Start/Stopp und Motor-Start
0xB Fehler_Kupplungsschalter nur für PAG-MLB";
CM_ SG_ 967 MO_Text_Partikelfil_Reg "Über dieses Bit im Kombi wird ein Klartextanzeige erzeugt werden: 'Partikelfilter benötigt Regeneration'.
";
CM_ SG_ 967 MO_Text_Tankdeckelwarn "Textbit der Tankdeckelwarnung, z.Zt. Vorhalt VW";
CM_ SG_ 967 MO_Vorglueh_Lampe "Vorglühlampe im Kombi, Kombi steuert immer gleiche LED an. 
Mit Einführung des Einheits-Kombis sind getrennte Signalwege für Vorglühlampe und EPCL notwendig.";
CM_ SG_ 967 MO_Zustand_HWP "Rückmeldung des  Ansteuerzustand der Hauptwasserpumpe an das Klima-SG .
Der Zustand 'HWP fördert' wird übermittelt, wenn die Schaufeln der Hauptwasserpumpe frei drehen können und die Motordrehzahl und damit die Wasserpumpendrehzahl größer als Null ist. B";
CM_ SG_ 967 OLEV_Oelstand_nicht_vorhanden "Kein aktueller Ölstand vorhanden";
CM_ SG_ 967 OLEV_Systemstoerung "Systemstörung im Ölsystem";
CM_ SG_ 967 WIV_Anzeige_aktiv "Peilstabsanzeigefunktion aktiv";
CM_ SG_ 967 WIV_laufender_Motor "Messung bei laufendem Motor nicht möglich";
CM_ SG_ 967 WIV_nachfuellanzeige_ein "Steuert das Aufblenden der Nachfüllanzeige im Kombi, nach Klemme 15 ein und geöffneter Motorhaube";
CM_ SG_ 967 WIV_nicht_betriebswarm "Motor nicht betriebswarm, Messung ungenau";
CM_ SG_ 967 WIV_Oeldr_Warn_Motor "Löst im Kombiinstrument die rote Prio1-Öldruckwarnung (inkl. 3xBeep) aus.
nur MLB: die Warnauslösung erfolgt nur bei gleichzeitig gesetztem 'WIV_Enable_Oeldr_Motor'";
CM_ SG_ 967 WIV_Oeldyn_avl "Ölstand aus dynamischer Messung vorhanden";
CM_ SG_ 967 WIV_Oelmenge "Ölmenge zwischen Min und Max";
CM_ SG_ 967 WIV_Oelmin_Warn "Signal gibt an wenn der Ölstand die Min-Schwelle unterschritten hat";
CM_ SG_ 967 WIV_Oelstand "8 Segmente zur Balkenanzeige des Ölstands";
CM_ SG_ 967 WIV_Oelstand_nicht_vorhanden "Kein aktueller Ölstand vorhanden";
CM_ SG_ 967 WIV_Oelsystem_aktiv "Gesamtölsystem aktiv (entspricht Ölsensor verbaut) und das Ölstand-Untermenu im MMI aktiv";
CM_ SG_ 967 WIV_Schieflage "Fahrzeug steht nicht waagerecht, Messung ungenau";
CM_ SG_ 967 WIV_Sensorfehler "Ölstand/Öltemperatursensor (TOG) defekt";
CM_ SG_ 967 WIV_Ueberfuell_deaktiv "Unterdrückung der Warnung im Kombi die durch Signal WIV_Ueberfuel_Warn ausgelöst wird";
CM_ SG_ 967 WIV_Ueberfuell_Warn "Ölstand hat die Überfüllschwelle überschritten";
CM_ SG_ 967 WIV_Unterfuell_Warn "Ölstand hat die Unterfüllschwelle unterschritten";

CM_ SG_ 267 MO_Entkopplung_Sollschlupf "MSG fordert von GSG an, das Anfahrelement (Fahr-/Wandlerkupplung) zu entkoppeln; das GSG soll die gesendete Drehzahl als Schlupf einstellen und ggf. die Regler-Parameter umschalten, damit Rucke aus dem Antrieb nicht im Fahrzeug spürbar werden; nutzbar z.B";
CM_ SG_ 267 MO_Fahrpedalgradient "Das Motorsteuergerät besitzt 2 analoge Fahrpedalsignale. Das Signal des ersten Kanals wird alle 4ms abgetastet. Um Bitschwankungen des A/D-Wandler herauszufiltern wird das Signal entjittert. Anschließend wird der Gradient berechnet. Entsprechend der Zyklu";
CM_ SG_ 267 MO_Fahrpedalrohwert_01 "AUDI D4: Zykluszeit: 10ms (siehe Zykluszeit schnell/Cycletime Fast)

Stellung des Fahrpedales (Rohwert, ohne Überlagerung durch GRA-Eingriffe etc.)

Die Funktionen zur Berechung des Fahrpedalrohwerts laufen im 10ms Raster. Der Fahrpedalwert berechnet ";
CM_ SG_ 267 MO_Moment_im_Leerlauf "Fahrerwunschmoment ist minimal: keine Momentenanforderung durch Fahrpedal, ACC oder GRA+; (Das Signal ist unabhängig von Momentenerhöhungen durch Leerlaufregler oder MSR).

AUDI D4: Zykluszeit: 10ms (siehe Zykluszeit schnell/Cycletime Fast)

Achtung:";
CM_ SG_ 267 MO_QBit_Fahrpedalwerte_01 "AUDI D4: Zykluszeit: 10ms (siehe Zykluszeit schnell/Cycletime Fast)

QBit für beide Fahrpedalwerte des Motors (Fahrpedalrohsignal für ESP, EPB, ACC; Fahrpedalwert für Getriebe)

Achtung:
Reduktion der Zykluszeit Motor_03 auf 10ms geplant.
Projektabh";
CM_ SG_ 267 MO_rel_Saugrohrdruck "Der Wert gibt an, um wieviel mbar der Saugrohrdruck unterhalb des Umgebungsdrucks liegt. Überdruck im Saugrohr wird nicht ausgegeben.
0: Saugrohrdruck=Umgebungsdruck";
CM_ SG_ 267 MO_rel_Saugrohrdruck_gem_err "0: mind. eine Modellrechnung wird zur Berechnung des relativen Saugdrucks herangezogen
1: Relativer Saugrohrdruck wird ausschließlich über Messgrößen bestimmt";
CM_ SG_ 267 MO_Schubabschaltung "ESP plausibilisiert Unterdrucksensor nur bei aktiver Schubabschaltung

MLBevo:
Signal wird nur in MLBevo Projekten mit PDKII Getriebe bedient. In allen anderen MLBevo Projekten wird das Signal mit '0' bedient
PDKII berücksichtigt Verzugszeiten, die in";
CM_ SG_ 267 MO_Sig_Fahrpedalgradient "Kennzeichnet das Vorzeichen des Signal 'Fahrpedalgradient'. Die Ausgabe erfolgt nur parallel statisch mit gesendetem Signal: 'Steuerungsbit Fahrpedalgradient' ";
CM_ SG_ 267 MO_Solldrehz_Leerlauf "Leerlaufsolldrehzahl, die im Motor eingestellt ist (Bei Parallelhybrid im E-Fahr-Betrieb Leerlaufsolldrehzahl der E-Maschine). Der Motor paßt aufgrund der Anforderung von anderen Steuergeräten seine Leerlaufsolldrehzahl an, bspw. Kat-Heizen, Anforderung v";
CM_ SG_ 267 MO_StartStopp_StoppVorbereitung "Zeigt allen aktiven Start-/Stoppteilnehmern einen möglichen Motorstopp im Anhaltevorgang an (Empfänger notwendige Vorbereitungen treffen)
Es liegen keine Vetos vor.";
CM_ SG_ 267 MO_Status_MaxDrzEingriff "Aktuell drehzahlführender Anforderer der Maximaldrehzahl (Begrenzungsregelung) des Pulswechselrichters der Primärachse.";
CM_ SG_ 267 MO_Status_MaxDrzEingriff_sek "Aktuell drehzahlführender Anforderer der Maximaldrehzahl (Begrenzungsregelung) des Pulswechselrichters der Sekundärachse.";
CM_ SG_ 267 MO_Status_MinDrzEingriff "Aktuell drehzahlführender Anforderer der Minimaldrehzahl (Begrenzungsregelung) des Pulswechselrichters der Primärachse.";
CM_ SG_ 267 MO_Status_MinDrzEingriff_sek "Aktuell drehzahlführender Anforderer der Minimaldrehzahl (Begrenzungsregelung) des Pulswechselrichters der Sekundärachse.";
CM_ SG_ 267 MO_temporaere_Fahrerabwesenheit "Das Signal dient zur Signalisierung einer temporären Abwesenheit des Fahrers. In dieser Zeit ist es ihm möglich, sich durch gewisse ¿ im Verlassenskonzept definierte ¿ Fahreraktionen im aktuellen Fahrzyklus zurückzumelden.
Das Signal wird gesetzt, sobald";
CM_ SG_ 267 Motor_51_BZ "4bit Botschaftszähler, wird mit jeder Sendebotschaft inkrementiert
Botschaft asynchron geroutet. Zählerwert kann springen.";
CM_ SG_ 267 Motor_51_CRC "Für MLB:
Berechnung siehe Lastenheft 'Kommunikationsabsicherung für FlexRay und CAN'
Ab MQB und MLBevo:
Berechnung siehe Lastenheft 'End-to-End Kommunikationsabsicherung'

Endwerte siehe Begleitdokument 'S-PDU Kennungsfolgen'";
CM_ SG_ 267 SOK_Motor_51_Signatur "Signatur im Rahmen der durch SOK geschützten Broadcast-Kommunikation

Geschützte Funktion: Bremsfunktion HDC und Airbag-Funktionen 
Geschützte Botschaft: Motor_51";
CM_ SG_ 267 TSK_a_Soll_gradientenbegrenzt "TSK Sollbeschleunigung für Fahrerassistenzsysteme mit aktiver Längsführung (GRA, ACC, IPA...). Der Wert stellt den ruckbegrenzten Sollwert der TSK-Regelung dar und ist Basis der TSK-Antriebs- und Bremsmomentenvorsteuerung.";
CM_ SG_ 267 TSK_ax_Getriebe_02 "Beschleunigungsanforderung des Beschleunigungsreglers (u. a. für ACC, GRA, Speed Limiter). Das Signal wird vom Getriebe benutzt, um die von GRA/ACC geforderte Sollbeschleunigung in dem verbrauchsgünstigsten Gang einzustellen.
MQB: Im MQB wird die Sollbes";
CM_ SG_ 267 TSK_Freig_Verzoeg_Anf "Freigabe der Verzögerungsanforderung der ACC oder ggf. GRA+ Funktion für ECD Regelung im ESP";
CM_ SG_ 267 TSK_Hauptschalter_GRA_ACC "Stellung des GRA/ACC Hauptschalters. Das Signal wird auch bei Fehlerabschaltungen von GRA/ACC weiterhin bedient und ermöglicht für ACC die Steuerung der ACC-Anzeige auch in Fehlerfällen.";
CM_ SG_ 267 TSK_Kategorie_Verzoegerungsfkt "Zeigt der Bremslichtfunktion an, ob die aktuell verzögerungswirksame Teilnehmerfunktion am TSK als Fahrerassistenzsystem oder als Schubrekuperation zu interpretieren ist.";
CM_ SG_ 267 TSK_Limiter_ausgewaehlt "ACC/GRA-Betrieb nur bei nicht ausgewähltem Limiter möglich";
CM_ SG_ 267 TSK_Notstopp_Anf "Anforderung Notstopp des TSK";
CM_ SG_ 267 TSK_Radbremsmom "Bei der Schnittstelle vom TSK zum ESP soll in Folgeprojekten des B8 und insbesondere bei VW-Projekten die Ansteuerung der Bremse nicht über Sollbeschleunigung sondern Bremsmoment erfolgen.  Es handelt sich genauer um das Summenradbremsmoment, welches die ";
CM_ SG_ 267 TSK_Radsollmoment "Sollradmoment vom TSK";
CM_ SG_ 267 TSK_SRBM_Anf_ASIL "ASIL-Level des TSK-Anforderers, der aktuell eine Bremsmomentenanforderung auslöst";
CM_ SG_ 267 TSK_SRBM_max_Gradient "In diesem Signal wird der vom TSK maximal geforderte SummenRadBremsMomentengradient gesendet, der von der Bremse bei der Umsetzung der TSK-Verzögerung nicht überschritten werden darf.";
CM_ SG_ 267 TSK_Standby_Anf_ESP "Mit diesem Bit wird das aktive Bremssystem auf eine anstehende TSK-Verzögerungsanforderung vorbereitet (Überfahren Leerweg, Anlegen Bremsbeläge)";
CM_ SG_ 267 TSK_Status "Betriebszustand des TSK-Reglers";
CM_ SG_ 267 TSK_v_Begrenzung_aktiv "Limiter oder HGB begrenzen die Beschleunigung/das Moment";
CM_ SG_ 267 TSK_zul_Regelabw "Anforderung der zulässigen Regelabweichung vom Triebstrangkoordinator. Zulässiger Betrag der Abweichung zwischen angeforderter 'TSK_Sollbeschleunigung_Getriebe' und umzusetzender Sollbeschleunigung  im Getriebe. Im TSK wird, abhängig vom Arbeitspunkt die ";
CM_ SG_ 267 TSK_Zwangszusch_ESP "Mit diesem Bit wird das ESP/ASR zwangsweise aktiviert. Bei gesetztem Bit ist ein ausgetastetes ESP (oder ASR) wieder aktiviert bzw. wird die Austastung verhindert.";
BA_DEF_REL_ BU_SG_REL_  "GenSigTimeoutTime" INT 0 65535;
BA_DEF_ BO_  "DiagRequest" ENUM "No", "Yes";
BA_DEF_ BO_  "DiagResponse" ENUM "No", "Yes";
BA_DEF_ BO_  "DiagState" ENUM "No", "Yes";
BA_DEF_ BO_  "GenMsgChkConstant" HEX 0 4095;
BA_DEF_ BO_  "GenMsgCycleTime" INT 0 65535;
BA_DEF_ BO_  "GenMsgCycleTimeFast" INT 0 65535;
BA_DEF_ BO_  "GenMsgDelayTime" INT 0 100000;
BA_DEF_ BO_  "GenMsgILSupport" ENUM "No", "Yes";
BA_DEF_ BO_  "GenMsgNrOfRepetition" INT 0 100;
BA_DEF_ BO_  "GenMsgPDUConstants" STRING;
BA_DEF_ BO_  "GenMsgSendType" ENUM "Cyclic", "not_used", "not_used", "not_used", "not_used", "not_used", "not_used", "IfActive", "NoMsgSendType";
BA_DEF_ BO_  "GenMsgStartDelayTime" INT 0 100000;
BA_DEF_ BO_  "NmMessage" ENUM "No", "Yes";
BA_DEF_ BO_  "NmhMessage" ENUM "No", "Yes";
BA_DEF_ BO_  "MsgType" ENUM "Application", "NM ", "NMH", "TP2.0", "ISO-TP ", "BAP", "EID", "KS", "XCP_PRE_CONFIGURED", "XCP_RUNTIME_CONFIGURED";
BA_DEF_ BO_  "VAGTP20_API" HEX 0 255;
BA_DEF_ BO_  "VAGTP20_DynConnection" ENUM "No", "Yes";
BA_DEF_ BO_  "VAGTP20_DynSetup" ENUM "No", "Yes";
BA_DEF_ BO_  "VAGTP20_StatConnection" ENUM "No", "Yes";
BA_DEF_ BO_  "CANFD_BRS" ENUM "0", "1";
BA_DEF_ BO_  "VFrameFormat" ENUM "StandardCAN", "ExtendedCAN", "reserved", "reserved", "reserved", "reserved", "reserved", "reserved", "reserved", "reserved", "reserved", "reserved", "reserved", "reserved", "StandardCAN_FD", "ExtendedCAN_FD";
BA_DEF_ SG_  "GenSigActiveRepetitions" INT -2147483648 2147483647;
BA_DEF_ SG_  "GenSigInactiveValue" INT -2147483648 2147483647;
BA_DEF_ SG_  "GenSigSendType" ENUM "Cyclic", "OnWrite", "OnWriteWithRepetition", "OnChange", "OnChangeWithRepetition", "IfActive", "IfActiveWithRepetition", "NoSigSendType", "OnChangeAndIfActive", "OnChangeAndIfActiveWithRepetition";
BA_DEF_ SG_  "GenSigStartValue" INT -2147483648 2147483647;
BA_DEF_ SG_  "NWM-WakeupAllowed" ENUM "No", "Yes";
BA_DEF_ SG_  "GenSigFuncType" ENUM "NoFunction", "MsgCounter", "CRC-8", "XOR", "XOR-2", "DatedBit", "SW-Kl15", "CHK", "Constant", "Protocol", "CRC-8-SAE_J1850", "CRC-32", "DataLength", "DataID", "MsgCounter16", "SOK-Signatur", "Cluster";
BA_DEF_ SG_  "GenSigSwitchedByIgnition" ENUM "No", "Yes";
BA_DEF_ SG_  "Fehlerwert" HEX 0 2147483647;
BA_DEF_ SG_  "GenSigMissingSourceValue" HEX 0 2147483647;
BA_DEF_DEF_REL_  "GenSigTimeoutTime" 0;
BA_DEF_DEF_  "DiagRequest" "No";
BA_DEF_DEF_  "DiagResponse" "No";
BA_DEF_DEF_  "DiagState" "No";
BA_DEF_DEF_  "GenMsgChkConstant" 0;
BA_DEF_DEF_  "GenMsgCycleTime" 0;
BA_DEF_DEF_  "GenMsgCycleTimeFast" 0;
BA_DEF_DEF_  "GenMsgDelayTime" 0;
BA_DEF_DEF_  "GenMsgILSupport" "No";
BA_DEF_DEF_  "GenMsgNrOfRepetition" 0;
BA_DEF_DEF_  "GenMsgPDUConstants" "";
BA_DEF_DEF_  "GenMsgSendType" "NoMsgSendType";
BA_DEF_DEF_  "GenMsgStartDelayTime" 0;
BA_DEF_DEF_  "NmMessage" "No";
BA_DEF_DEF_  "NmhMessage" "No";
BA_DEF_DEF_  "MsgType" "Application";
BA_DEF_DEF_  "VAGTP20_API" 0;
BA_DEF_DEF_  "VAGTP20_DynConnection" "No";
BA_DEF_DEF_  "VAGTP20_DynSetup" "No";
BA_DEF_DEF_  "VAGTP20_StatConnection" "No";
BA_DEF_DEF_  "CANFD_BRS" "1";
BA_DEF_DEF_  "VFrameFormat" "StandardCAN";
BA_DEF_DEF_  "GenSigActiveRepetitions" 0;
BA_DEF_DEF_  "GenSigInactiveValue" 0;
BA_DEF_DEF_  "GenSigSendType" "NoSigSendType";
BA_DEF_DEF_  "GenSigStartValue" 0;
BA_DEF_DEF_  "NWM-WakeupAllowed" "No";
BA_DEF_DEF_  "GenSigFuncType" "NoFunction";
BA_DEF_DEF_  "GenSigSwitchedByIgnition" "Yes";
BA_DEF_DEF_  "Fehlerwert" 0;
BA_DEF_DEF_  "GenSigMissingSourceValue" 0;
BA_ "GenMsgCycleTime" BO_ 1178 100;
BA_ "GenMsgDelayTime" BO_ 1178 50;
BA_ "GenMsgILSupport" BO_ 1178 1;
BA_ "GenMsgPDUConstants" BO_ 1178 "0xd0,0xc5,0xac,0x82,0xb1,0xfb,0x24,0x4d,0xc0,0x20,0x4b,0xbc,0x86,0x3b,0x22,0x25";
BA_ "GenMsgSendType" BO_ 1178 0;
BA_ "CANFD_BRS" BO_ 1178 0;
BA_ "VFrameFormat" BO_ 1178 14;
BA_ "GenMsgChkConstant" BO_ 1180 152;
BA_ "GenMsgCycleTime" BO_ 1180 100;
BA_ "GenMsgCycleTimeFast" BO_ 1180 50;
BA_ "GenMsgDelayTime" BO_ 1180 30;
BA_ "GenMsgILSupport" BO_ 1180 1;
BA_ "GenMsgNrOfRepetition" BO_ 1180 6;
BA_ "GenMsgPDUConstants" BO_ 1180 "0x98,0x98,0x98,0x98,0x98,0x98,0x98,0x98,0x98,0x98,0x98,0x98,0x98,0x98,0x98,0x98";
BA_ "GenMsgSendType" BO_ 1180 0;
BA_ "CANFD_BRS" BO_ 1180 0;
BA_ "VFrameFormat" BO_ 1180 14;
BA_ "GenMsgChkConstant" BO_ 1170 150;
BA_ "GenMsgCycleTime" BO_ 1170 100;
BA_ "GenMsgCycleTimeFast" BO_ 1170 50;
BA_ "GenMsgDelayTime" BO_ 1170 30;
BA_ "GenMsgILSupport" BO_ 1170 1;
BA_ "GenMsgNrOfRepetition" BO_ 1170 6;
BA_ "GenMsgPDUConstants" BO_ 1170 "0x96,0x96,0x96,0x96,0x96,0x96,0x96,0x96,0x96,0x96,0x96,0x96,0x96,0x96,0x96,0x96";
BA_ "GenMsgSendType" BO_ 1170 0;
BA_ "CANFD_BRS" BO_ 1170 0;
BA_ "VFrameFormat" BO_ 1170 14;
BA_ "GenMsgChkConstant" BO_ 1173 145;
BA_ "GenMsgCycleTime" BO_ 1173 100;
BA_ "GenMsgILSupport" BO_ 1173 1;
BA_ "GenMsgPDUConstants" BO_ 1173 "0x91,0x91,0x91,0x91,0x91,0x91,0x91,0x91,0x91,0x91,0x91,0x91,0x91,0x91,0x91,0x91";
BA_ "GenMsgSendType" BO_ 1173 0;
BA_ "CANFD_BRS" BO_ 1173 0;
BA_ "VFrameFormat" BO_ 1173 14;
BA_ "GenMsgChkConstant" BO_ 1171 151;
BA_ "GenMsgCycleTime" BO_ 1171 200;
BA_ "GenMsgDelayTime" BO_ 1171 20;
BA_ "GenMsgILSupport" BO_ 1171 1;
BA_ "GenMsgPDUConstants" BO_ 1171 "0x97,0x97,0x97,0x97,0x97,0x97,0x97,0x97,0x97,0x97,0x97,0x97,0x97,0x97,0x97,0x97";
BA_ "GenMsgSendType" BO_ 1171 0;
BA_ "CANFD_BRS" BO_ 1171 0;
BA_ "VFrameFormat" BO_ 1171 14;
BA_ "GenMsgCycleTime" BO_ 1164 200;
BA_ "GenMsgCycleTimeFast" BO_ 1164 50;
BA_ "GenMsgDelayTime" BO_ 1164 20;
BA_ "GenMsgILSupport" BO_ 1164 1;
BA_ "GenMsgNrOfRepetition" BO_ 1164 5;
BA_ "GenMsgSendType" BO_ 1164 0;
BA_ "CANFD_BRS" BO_ 1164 0;
BA_ "VFrameFormat" BO_ 1164 14;
BA_ "GenMsgCycleTime" BO_ 2463978883 100;
BA_ "GenMsgILSupport" BO_ 2463978883 1;
BA_ "GenMsgSendType" BO_ 2463978883 0;
BA_ "CANFD_BRS" BO_ 2463978883 0;
BA_ "VFrameFormat" BO_ 2463978883 15;
BA_ "GenMsgCycleTimeFast" BO_ 1471 1000;
BA_ "GenMsgDelayTime" BO_ 1471 30;
BA_ "GenMsgILSupport" BO_ 1471 1;
BA_ "GenMsgNrOfRepetition" BO_ 1471 5;
BA_ "CANFD_BRS" BO_ 1471 0;
BA_ "VFrameFormat" BO_ 1471 14;
BA_ "GenMsgCycleTime" BO_ 2463978865 100;
BA_ "GenMsgPDUConstants" BO_ 2463978865 "0x08,0xe6,0xd9,0x58,0x2a,0xed,0x72,0xb7,0xb6,0xcc,0xd2,0x03,0x43,0xf2,0xa2,0x85";
BA_ "GenMsgSendType" BO_ 2463978865 0;
BA_ "CANFD_BRS" BO_ 2463978865 0;
BA_ "VFrameFormat" BO_ 2463978865 15;
BA_ "GenMsgDelayTime" BO_ 2527679795 10;
BA_ "GenMsgILSupport" BO_ 2527679795 1;
BA_ "CANFD_BRS" BO_ 2527679795 0;
BA_ "VFrameFormat" BO_ 2527679795 15;
BA_ "GenMsgDelayTime" BO_ 2527679796 10;
BA_ "GenMsgILSupport" BO_ 2527679796 1;
BA_ "CANFD_BRS" BO_ 2527679796 0;
BA_ "VFrameFormat" BO_ 2527679796 15;
BA_ "GenMsgDelayTime" BO_ 2527679797 10;
BA_ "GenMsgILSupport" BO_ 2527679797 1;
BA_ "CANFD_BRS" BO_ 2527679797 0;
BA_ "VFrameFormat" BO_ 2527679797 15;
BA_ "GenMsgDelayTime" BO_ 2527679798 10;
BA_ "GenMsgILSupport" BO_ 2527679798 1;
BA_ "CANFD_BRS" BO_ 2527679798 0;
BA_ "VFrameFormat" BO_ 2527679798 15;
BA_ "GenMsgDelayTime" BO_ 2527679799 10;
BA_ "GenMsgILSupport" BO_ 2527679799 1;
BA_ "CANFD_BRS" BO_ 2527679799 0;
BA_ "VFrameFormat" BO_ 2527679799 15;
BA_ "GenMsgCycleTime" BO_ 263 100;
BA_ "GenMsgILSupport" BO_ 263 1;
BA_ "GenMsgSendType" BO_ 263 0;
BA_ "CANFD_BRS" BO_ 263 0;
BA_ "VFrameFormat" BO_ 263 14;
BA_ "GenMsgCycleTime" BO_ 1600 500;
BA_ "GenMsgILSupport" BO_ 1600 1;
BA_ "GenMsgSendType" BO_ 1600 0;
BA_ "CANFD_BRS" BO_ 1600 0;
BA_ "VFrameFormat" BO_ 1600 14;
BA_ "GenMsgCycleTime" BO_ 958 100;
BA_ "GenMsgDelayTime" BO_ 958 10;
BA_ "GenMsgILSupport" BO_ 958 1;
BA_ "GenMsgPDUConstants" BO_ 958 "0x1f,0x28,0xc6,0x85,0xe6,0xf8,0xb0,0x19,0x5b,0x64,0x35,0x21,0xe4,0xf7,0x9c,0x24";
BA_ "GenMsgSendType" BO_ 958 0;
BA_ "CANFD_BRS" BO_ 958 0;
BA_ "VFrameFormat" BO_ 958 14;
BA_ "GenMsgCycleTime" BO_ 1648 500;
BA_ "GenMsgDelayTime" BO_ 1648 20;
BA_ "GenMsgILSupport" BO_ 1648 1;
BA_ "GenMsgSendType" BO_ 1648 0;
BA_ "CANFD_BRS" BO_ 1648 0;
BA_ "VFrameFormat" BO_ 1648 14;
BA_ "GenMsgCycleTime" BO_ 967 100;
BA_ "GenMsgILSupport" BO_ 967 1;
BA_ "GenMsgSendType" BO_ 967 0;
BA_ "CANFD_BRS" BO_ 967 0;
BA_ "VFrameFormat" BO_ 967 14;
BA_ "GenMsgCycleTime" BO_ 267 100;
BA_ "GenMsgILSupport" BO_ 267 1;
BA_ "GenMsgPDUConstants" BO_ 267 "0x2c,0xb1,0x1a,0x75,0xbb,0x65,0x79,0x47,0x81,0x2b,0xcc,0x96,0x17,0xdb,0xc0,0x94";
BA_ "GenMsgSendType" BO_ 267 0;
BA_ "CANFD_BRS" BO_ 267 0;
BA_ "VFrameFormat" BO_ 267 14;
BA_ "GenSigSendType" SG_ 1178 FS_BFS_Fond_Verst_enable 3;
BA_ "GenSigSwitchedByIgnition" SG_ 1178 FS_BFS_Fond_Verst_enable 0;
BA_ "GenSigSendType" SG_ 1178 FS_BFS_KSS_Anfahrt 3;
BA_ "GenSigSwitchedByIgnition" SG_ 1178 FS_BFS_KSS_Anfahrt 0;
BA_ "GenSigSendType" SG_ 1178 FS_BFS_Sitzsym_Anfahrt 3;
BA_ "GenSigSwitchedByIgnition" SG_ 1178 FS_BFS_Sitzsym_Anfahrt 0;
BA_ "GenSigSendType" SG_ 1178 FS_EE_BFS_enable 3;
BA_ "GenSigSwitchedByIgnition" SG_ 1178 FS_EE_BFS_enable 0;
BA_ "GenSigSendType" SG_ 1178 FS_EE_Fond_BFS_enable 3;
BA_ "GenSigSwitchedByIgnition" SG_ 1178 FS_EE_Fond_BFS_enable 0;
BA_ "GenSigSendType" SG_ 1178 FS_EE_Fond_FS_enable 3;
BA_ "GenSigSwitchedByIgnition" SG_ 1178 FS_EE_Fond_FS_enable 0;
BA_ "GenSigSendType" SG_ 1178 FS_Fond_Bed_enable 3;
BA_ "GenSigSwitchedByIgnition" SG_ 1178 FS_Fond_Bed_enable 0;
BA_ "GenSigSendType" SG_ 1178 FS_GHV_aktiv 3;
BA_ "GenSigSwitchedByIgnition" SG_ 1178 FS_GHV_aktiv 0;
BA_ "GenSigSendType" SG_ 1178 FS_Gurtbringer_Sperre 0;
BA_ "GenSigSwitchedByIgnition" SG_ 1178 FS_Gurtbringer_Sperre 0;
BA_ "GenSigSendType" SG_ 1178 FS_KSV_aktiv 3;
BA_ "GenSigSwitchedByIgnition" SG_ 1178 FS_KSV_aktiv 0;
BA_ "GenSigSendType" SG_ 1178 FS_Lehne_nicht_verriegelt 3;
BA_ "GenSigSwitchedByIgnition" SG_ 1178 FS_Lehne_nicht_verriegelt 0;
BA_ "GenSigSendType" SG_ 1178 FS_LHV_aktiv 3;
BA_ "GenSigSwitchedByIgnition" SG_ 1178 FS_LHV_aktiv 0;
BA_ "GenSigSendType" SG_ 1178 FS_LKV_aktiv 3;
BA_ "GenSigSwitchedByIgnition" SG_ 1178 FS_LKV_aktiv 0;
BA_ "GenSigSendType" SG_ 1178 FS_LNV_aktiv 3;
BA_ "GenSigSwitchedByIgnition" SG_ 1178 FS_LNV_aktiv 0;
BA_ "GenSigSendType" SG_ 1178 FS_LWV_aktiv 3;
BA_ "GenSigSwitchedByIgnition" SG_ 1178 FS_LWV_aktiv 0;
BA_ "GenSigSendType" SG_ 1178 FS_MMB_glob_stop 3;
BA_ "GenSigSwitchedByIgnition" SG_ 1178 FS_MMB_glob_stop 0;
BA_ "GenSigSendType" SG_ 1178 FS_MMB_lokal_Stop 3;
BA_ "GenSigSwitchedByIgnition" SG_ 1178 FS_MMB_lokal_Stop 0;
BA_ "GenSigSendType" SG_ 1178 FS_MMB_storage 3;
BA_ "GenSigSwitchedByIgnition" SG_ 1178 FS_MMB_storage 0;
BA_ "GenSigSendType" SG_ 1178 FS_MMB_storage_beep 3;
BA_ "GenSigSwitchedByIgnition" SG_ 1178 FS_MMB_storage_beep 0;
BA_ "GenSigSendType" SG_ 1178 FS_MMB_store 3;
BA_ "GenSigSwitchedByIgnition" SG_ 1178 FS_MMB_store 0;
BA_ "GenSigSendType" SG_ 1178 FS_MMB_store_LED_on 3;
BA_ "GenSigSwitchedByIgnition" SG_ 1178 FS_MMB_store_LED_on 0;
BA_ "GenSigSendType" SG_ 1178 FS_MMB_tast 3;
BA_ "GenSigSwitchedByIgnition" SG_ 1178 FS_MMB_tast 0;
BA_ "GenSigSendType" SG_ 1178 FS_MMB_tipp 3;
BA_ "GenSigSwitchedByIgnition" SG_ 1178 FS_MMB_tipp 0;
BA_ "GenSigSendType" SG_ 1178 FS_SHV_aktiv 3;
BA_ "GenSigSwitchedByIgnition" SG_ 1178 FS_SHV_aktiv 0;
BA_ "GenSigSendType" SG_ 1178 FS_Sitzfahrt_aktiv 3;
BA_ "GenSigSwitchedByIgnition" SG_ 1178 FS_Sitzfahrt_aktiv 0;
BA_ "GenSigSendType" SG_ 1178 FS_SLV_aktiv 3;
BA_ "GenSigSwitchedByIgnition" SG_ 1178 FS_SLV_aktiv 0;
BA_ "GenSigSendType" SG_ 1178 FS_SNV_aktiv 3;
BA_ "GenSigSwitchedByIgnition" SG_ 1178 FS_SNV_aktiv 0;
BA_ "GenSigSendType" SG_ 1178 FS_Spezialposition_anfahren 3;
BA_ "GenSigSwitchedByIgnition" SG_ 1178 FS_Spezialposition_anfahren 0;
BA_ "GenSigSendType" SG_ 1178 FS_STV_aktiv 3;
BA_ "GenSigSwitchedByIgnition" SG_ 1178 FS_STV_aktiv 0;
BA_ "GenSigSendType" SG_ 1178 Mem_FS_01_MQB_BZ 0;
BA_ "GenSigFuncType" SG_ 1178 Mem_FS_01_MQB_BZ 1;
BA_ "GenSigSwitchedByIgnition" SG_ 1178 Mem_FS_01_MQB_BZ 0;
BA_ "GenSigSendType" SG_ 1178 Mem_FS_01_MQB_CRC 0;
BA_ "GenSigFuncType" SG_ 1178 Mem_FS_01_MQB_CRC 2;
BA_ "GenSigSwitchedByIgnition" SG_ 1178 Mem_FS_01_MQB_CRC 0;
BA_ "GenSigSendType" SG_ 1180 Mem_Taster_BT_01_BZ 0;
BA_ "GenSigFuncType" SG_ 1180 Mem_Taster_BT_01_BZ 1;
BA_ "GenSigSwitchedByIgnition" SG_ 1180 Mem_Taster_BT_01_BZ 0;
BA_ "GenSigSendType" SG_ 1180 Mem_Taster_BT_01_CRC 0;
BA_ "GenSigFuncType" SG_ 1180 Mem_Taster_BT_01_CRC 2;
BA_ "GenSigActiveRepetitions" SG_ 1180 MTBT_M_Taste 6;
BA_ "GenSigSendType" SG_ 1180 MTBT_M_Taste 4;
BA_ "GenSigSwitchedByIgnition" SG_ 1180 MTBT_M_Taste 0;
BA_ "GenSigActiveRepetitions" SG_ 1180 MTBT_On_Off 6;
BA_ "GenSigSendType" SG_ 1180 MTBT_On_Off 4;
BA_ "GenSigSwitchedByIgnition" SG_ 1180 MTBT_On_Off 0;
BA_ "GenSigActiveRepetitions" SG_ 1180 MTBT_Pos1 6;
BA_ "GenSigSendType" SG_ 1180 MTBT_Pos1 4;
BA_ "GenSigSwitchedByIgnition" SG_ 1180 MTBT_Pos1 0;
BA_ "GenSigActiveRepetitions" SG_ 1180 MTBT_Pos2 6;
BA_ "GenSigSendType" SG_ 1180 MTBT_Pos2 4;
BA_ "GenSigSwitchedByIgnition" SG_ 1180 MTBT_Pos2 0;
BA_ "GenSigActiveRepetitions" SG_ 1180 MTBT_Pos3 6;
BA_ "GenSigSendType" SG_ 1180 MTBT_Pos3 4;
BA_ "GenSigSwitchedByIgnition" SG_ 1180 MTBT_Pos3 0;
BA_ "GenSigActiveRepetitions" SG_ 1180 MTBT_Pos4 6;
BA_ "GenSigSendType" SG_ 1180 MTBT_Pos4 4;
BA_ "GenSigSwitchedByIgnition" SG_ 1180 MTBT_Pos4 0;
BA_ "GenSigSendType" SG_ 1170 Mem_Taster_FT_01_BZ 0;
BA_ "GenSigFuncType" SG_ 1170 Mem_Taster_FT_01_BZ 1;
BA_ "GenSigSwitchedByIgnition" SG_ 1170 Mem_Taster_FT_01_BZ 0;
BA_ "GenSigSendType" SG_ 1170 Mem_Taster_FT_01_CRC 0;
BA_ "GenSigFuncType" SG_ 1170 Mem_Taster_FT_01_CRC 2;
BA_ "GenSigActiveRepetitions" SG_ 1170 MTFT_M_Taste 6;
BA_ "GenSigSendType" SG_ 1170 MTFT_M_Taste 4;
BA_ "GenSigSwitchedByIgnition" SG_ 1170 MTFT_M_Taste 0;
BA_ "GenSigActiveRepetitions" SG_ 1170 MTFT_On_Off 6;
BA_ "GenSigSendType" SG_ 1170 MTFT_On_Off 4;
BA_ "GenSigSwitchedByIgnition" SG_ 1170 MTFT_On_Off 0;
BA_ "GenSigActiveRepetitions" SG_ 1170 MTFT_Pos1_EE 6;
BA_ "GenSigSendType" SG_ 1170 MTFT_Pos1_EE 4;
BA_ "GenSigSwitchedByIgnition" SG_ 1170 MTFT_Pos1_EE 0;
BA_ "GenSigActiveRepetitions" SG_ 1170 MTFT_Pos2 6;
BA_ "GenSigSendType" SG_ 1170 MTFT_Pos2 4;
BA_ "GenSigSwitchedByIgnition" SG_ 1170 MTFT_Pos2 0;
BA_ "GenSigActiveRepetitions" SG_ 1170 MTFT_Pos3 6;
BA_ "GenSigSendType" SG_ 1170 MTFT_Pos3 4;
BA_ "GenSigSwitchedByIgnition" SG_ 1170 MTFT_Pos3 0;
BA_ "GenSigActiveRepetitions" SG_ 1170 MTFT_Pos4 6;
BA_ "GenSigSendType" SG_ 1170 MTFT_Pos4 4;
BA_ "GenSigSwitchedByIgnition" SG_ 1170 MTFT_Pos4 0;
BA_ "GenSigActiveRepetitions" SG_ 1170 MTFT_Verst_akt 6;
BA_ "GenSigSendType" SG_ 1170 MTFT_Verst_akt 4;
BA_ "GenSigSwitchedByIgnition" SG_ 1170 MTFT_Verst_akt 0;
BA_ "GenSigSendType" SG_ 1173 BFS_Kopfstuetzen_hoch 0;
BA_ "GenSigSwitchedByIgnition" SG_ 1173 BFS_Kopfstuetzen_hoch 0;
BA_ "GenSigSendType" SG_ 1173 BFS_Kopfstuetzen_runter 0;
BA_ "GenSigSwitchedByIgnition" SG_ 1173 BFS_Kopfstuetzen_runter 0;
BA_ "GenSigSendType" SG_ 1173 BFS_Laengsverst_vor 0;
BA_ "GenSigSwitchedByIgnition" SG_ 1173 BFS_Laengsverst_vor 0;
BA_ "GenSigSendType" SG_ 1173 BFS_Laengsverst_zurueck 0;
BA_ "GenSigSwitchedByIgnition" SG_ 1173 BFS_Laengsverst_zurueck 0;
BA_ "GenSigSendType" SG_ 1173 BFS_Lehnenkopf_vor 0;
BA_ "GenSigSwitchedByIgnition" SG_ 1173 BFS_Lehnenkopf_vor 0;
BA_ "GenSigSendType" SG_ 1173 BFS_Lehnenkopf_zurueck 0;
BA_ "GenSigSwitchedByIgnition" SG_ 1173 BFS_Lehnenkopf_zurueck 0;
BA_ "GenSigSendType" SG_ 1173 BFS_Lehnenneigung_vor 0;
BA_ "GenSigSwitchedByIgnition" SG_ 1173 BFS_Lehnenneigung_vor 0;
BA_ "GenSigSendType" SG_ 1173 BFS_Lehnenneigung_zurueck 0;
BA_ "GenSigSwitchedByIgnition" SG_ 1173 BFS_Lehnenneigung_zurueck 0;
BA_ "GenSigSendType" SG_ 1173 BFS_Sitzhoehe_hoch 0;
BA_ "GenSigSwitchedByIgnition" SG_ 1173 BFS_Sitzhoehe_hoch 0;
BA_ "GenSigSendType" SG_ 1173 BFS_Sitzhoehe_runter 0;
BA_ "GenSigSwitchedByIgnition" SG_ 1173 BFS_Sitzhoehe_runter 0;
BA_ "GenSigSendType" SG_ 1173 MTHBF_BZ 0;
BA_ "GenSigFuncType" SG_ 1173 MTHBF_BZ 1;
BA_ "GenSigSwitchedByIgnition" SG_ 1173 MTHBF_BZ 0;
BA_ "GenSigSendType" SG_ 1173 MTHBF_CRC 0;
BA_ "GenSigFuncType" SG_ 1173 MTHBF_CRC 2;
BA_ "GenSigSendType" SG_ 1173 MTHBF_ein 0;
BA_ "GenSigSwitchedByIgnition" SG_ 1173 MTHBF_ein 0;
BA_ "GenSigSendType" SG_ 1171 MF_Abzugssperre 3;
BA_ "GenSigSwitchedByIgnition" SG_ 1171 MF_Abzugssperre 0;
BA_ "GenSigSendType" SG_ 1171 MF_Alarm_Blinker 3;
BA_ "GenSigSwitchedByIgnition" SG_ 1171 MF_Alarm_Blinker 0;
BA_ "GenSigSendType" SG_ 1171 MF_Alarm_Blinkertakt 3;
BA_ "GenSigSwitchedByIgnition" SG_ 1171 MF_Alarm_Blinkertakt 0;
BA_ "GenSigSendType" SG_ 1171 MF_Anlassersperre 3;
BA_ "GenSigSwitchedByIgnition" SG_ 1171 MF_Anlassersperre 0;
BA_ "GenSigSendType" SG_ 1171 MF_Blk_li 3;
BA_ "GenSigSwitchedByIgnition" SG_ 1171 MF_Blk_li 0;
BA_ "GenSigSendType" SG_ 1171 MF_Blk_re 3;
BA_ "GenSigSwitchedByIgnition" SG_ 1171 MF_Blk_re 0;
BA_ "GenSigSendType" SG_ 1171 MF_BT_entriegeln 3;
BA_ "GenSigSwitchedByIgnition" SG_ 1171 MF_BT_entriegeln 0;
BA_ "GenSigSendType" SG_ 1171 MF_BT_verriegeln 3;
BA_ "GenSigSwitchedByIgnition" SG_ 1171 MF_BT_verriegeln 0;
BA_ "GenSigSendType" SG_ 1171 MF_Fahrlicht 3;
BA_ "GenSigSwitchedByIgnition" SG_ 1171 MF_Fahrlicht 0;
BA_ "GenSigSendType" SG_ 1171 MF_Fernbed_ein 3;
BA_ "GenSigSwitchedByIgnition" SG_ 1171 MF_Fernbed_ein 0;
BA_ "GenSigSendType" SG_ 1171 MF_Fernlicht 3;
BA_ "GenSigSwitchedByIgnition" SG_ 1171 MF_Fernlicht 0;
BA_ "GenSigSendType" SG_ 1171 MF_FH_BT_hoch 3;
BA_ "GenSigSwitchedByIgnition" SG_ 1171 MF_FH_BT_hoch 0;
BA_ "GenSigSendType" SG_ 1171 MF_FH_BT_tief 3;
BA_ "GenSigSwitchedByIgnition" SG_ 1171 MF_FH_BT_tief 0;
BA_ "GenSigSendType" SG_ 1171 MF_FH_FT_hoch 3;
BA_ "GenSigSwitchedByIgnition" SG_ 1171 MF_FH_FT_hoch 0;
BA_ "GenSigSendType" SG_ 1171 MF_FH_FT_tief 3;
BA_ "GenSigSwitchedByIgnition" SG_ 1171 MF_FH_FT_tief 0;
BA_ "GenSigSendType" SG_ 1171 MF_Frontintervall 3;
BA_ "GenSigSwitchedByIgnition" SG_ 1171 MF_Frontintervall 0;
BA_ "GenSigSendType" SG_ 1171 MF_Frontwaschen 3;
BA_ "GenSigSwitchedByIgnition" SG_ 1171 MF_Frontwaschen 0;
BA_ "GenSigSendType" SG_ 1171 MF_FT_entriegeln 3;
BA_ "GenSigSwitchedByIgnition" SG_ 1171 MF_FT_entriegeln 0;
BA_ "GenSigSendType" SG_ 1171 MF_FT_verriegeln 3;
BA_ "GenSigSwitchedByIgnition" SG_ 1171 MF_FT_verriegeln 0;
BA_ "GenSigSendType" SG_ 1171 MF_Fussraumbel 3;
BA_ "GenSigSwitchedByIgnition" SG_ 1171 MF_Fussraumbel 0;
BA_ "GenSigSendType" SG_ 1171 MF_HBFS_entriegeln 3;
BA_ "GenSigSwitchedByIgnition" SG_ 1171 MF_HBFS_entriegeln 0;
BA_ "GenSigSendType" SG_ 1171 MF_HBFS_verriegeln 3;
BA_ "GenSigSwitchedByIgnition" SG_ 1171 MF_HBFS_verriegeln 0;
BA_ "GenSigSendType" SG_ 1171 MF_Heckintervall 3;
BA_ "GenSigSwitchedByIgnition" SG_ 1171 MF_Heckintervall 0;
BA_ "GenSigSendType" SG_ 1171 MF_Heckwaschen 3;
BA_ "GenSigSwitchedByIgnition" SG_ 1171 MF_Heckwaschen 0;
BA_ "GenSigSendType" SG_ 1171 MF_HFS_entriegeln 3;
BA_ "GenSigSwitchedByIgnition" SG_ 1171 MF_HFS_entriegeln 0;
BA_ "GenSigSendType" SG_ 1171 MF_HFS_verriegeln 3;
BA_ "GenSigSwitchedByIgnition" SG_ 1171 MF_HFS_verriegeln 0;
BA_ "GenSigSendType" SG_ 1171 MF_Innenraumbel 3;
BA_ "GenSigSwitchedByIgnition" SG_ 1171 MF_Innenraumbel 0;
BA_ "GenSigSendType" SG_ 1171 MF_Innenraumbel_Unterdrueck 3;
BA_ "GenSigSwitchedByIgnition" SG_ 1171 MF_Innenraumbel_Unterdrueck 0;
BA_ "GenSigSendType" SG_ 1171 MF_interm_Fahrlicht 3;
BA_ "GenSigSwitchedByIgnition" SG_ 1171 MF_interm_Fahrlicht 0;
BA_ "GenSigSendType" SG_ 1171 MF_interm_Fernlicht 3;
BA_ "GenSigSwitchedByIgnition" SG_ 1171 MF_interm_Fernlicht 0;
BA_ "GenSigSendType" SG_ 1171 MF_interm_Takt 3;
BA_ "GenSigSwitchedByIgnition" SG_ 1171 MF_interm_Takt 0;
BA_ "GenSigSendType" SG_ 1171 MF_Laderelais 3;
BA_ "GenSigSwitchedByIgnition" SG_ 1171 MF_Laderelais 0;
BA_ "GenSigSendType" SG_ 1171 MF_Lichthupe 3;
BA_ "GenSigSwitchedByIgnition" SG_ 1171 MF_Lichthupe 0;
BA_ "GenSigSendType" SG_ 1171 MF_Motorweiterlauf 3;
BA_ "GenSigSwitchedByIgnition" SG_ 1171 MF_Motorweiterlauf 0;
BA_ "GenSigSendType" SG_ 1171 MF_nachtr_Stopp_Anf 0;
BA_ "GenSigSwitchedByIgnition" SG_ 1171 MF_nachtr_Stopp_Anf 0;
BA_ "GenSigSendType" SG_ 1171 MF_Notstart 3;
BA_ "GenSigSwitchedByIgnition" SG_ 1171 MF_Notstart 0;
BA_ "GenSigSendType" SG_ 1171 MF_Schluessel_scan 3;
BA_ "GenSigSwitchedByIgnition" SG_ 1171 MF_Schluessel_scan 0;
BA_ "GenSigSendType" SG_ 1171 MF_Signalhorn 3;
BA_ "GenSigSwitchedByIgnition" SG_ 1171 MF_Signalhorn 0;
BA_ "GenSigSendType" SG_ 1171 MF_Standlicht 3;
BA_ "GenSigSwitchedByIgnition" SG_ 1171 MF_Standlicht 0;
BA_ "GenSigSendType" SG_ 1171 MF_StartStopp_Info 0;
BA_ "GenSigSwitchedByIgnition" SG_ 1171 MF_StartStopp_Info 0;
BA_ "GenSigSendType" SG_ 1171 MF_Summer 3;
BA_ "GenSigSwitchedByIgnition" SG_ 1171 MF_Summer 0;
BA_ "GenSigSendType" SG_ 1171 MF_TFL_Abschaltung 3;
BA_ "GenSigSwitchedByIgnition" SG_ 1171 MF_TFL_Abschaltung 0;
BA_ "GenSigSendType" SG_ 1171 MF_Tippwischen 3;
BA_ "GenSigSwitchedByIgnition" SG_ 1171 MF_Tippwischen 0;
BA_ "GenSigSendType" SG_ 1171 MF_Tuerentriegelung_hinten 3;
BA_ "GenSigSwitchedByIgnition" SG_ 1171 MF_Tuerentriegelung_hinten 0;
BA_ "GenSigSendType" SG_ 1171 MF_Variante 3;
BA_ "GenSigSwitchedByIgnition" SG_ 1171 MF_Variante 0;
BA_ "GenSigSendType" SG_ 1171 MF_Warnblinker 3;
BA_ "GenSigSwitchedByIgnition" SG_ 1171 MF_Warnblinker 0;
BA_ "GenSigSendType" SG_ 1171 MF_Wischerstufe_1 3;
BA_ "GenSigSwitchedByIgnition" SG_ 1171 MF_Wischerstufe_1 0;
BA_ "GenSigSendType" SG_ 1171 MF_Wischerstufe_2 3;
BA_ "GenSigSwitchedByIgnition" SG_ 1171 MF_Wischerstufe_2 0;
BA_ "GenSigSendType" SG_ 1171 MF_ZV_Lock 3;
BA_ "GenSigSwitchedByIgnition" SG_ 1171 MF_ZV_Lock 0;
BA_ "GenSigSendType" SG_ 1171 MFG_01_BZ 0;
BA_ "GenSigFuncType" SG_ 1171 MFG_01_BZ 1;
BA_ "GenSigSwitchedByIgnition" SG_ 1171 MFG_01_BZ 0;
BA_ "GenSigSendType" SG_ 1171 MFG_01_CRC 0;
BA_ "GenSigFuncType" SG_ 1171 MFG_01_CRC 2;
BA_ "GenSigSwitchedByIgnition" SG_ 1171 MFG_01_CRC 0;
BA_ "GenSigSendType" SG_ 1164 MF_2BatSOCzugering 0;
BA_ "GenSigSendType" SG_ 1164 MF_2BattAb 0;
BA_ "GenSigSendType" SG_ 1164 MF_2BattHlkAnf 0;
BA_ "GenSigSendType" SG_ 1164 MF_2BattLadWarn 0;
BA_ "GenSigSendType" SG_ 1164 MF_2BattLlaAnf 0;
BA_ "GenSigSendType" SG_ 1164 MF_2BattSpannungsAnf 0;
BA_ "GenSigSendType" SG_ 1164 MF_Batteriediagnose 0;
BA_ "GenSigSwitchedByIgnition" SG_ 1164 MF_Batteriediagnose 0;
BA_ "Fehlerwert" SG_ 1164 MF_Batteriediagnose 7;
BA_ "GenSigSendType" SG_ 1164 MF_Blinker_L_Sta 3;
BA_ "GenSigSwitchedByIgnition" SG_ 1164 MF_Blinker_L_Sta 0;
BA_ "GenSigSendType" SG_ 1164 MF_Blinker_R_Sta 3;
BA_ "GenSigSwitchedByIgnition" SG_ 1164 MF_Blinker_R_Sta 0;
BA_ "GenSigSendType" SG_ 1164 MF_ExterneLadungWarn 0;
BA_ "GenSigSendType" SG_ 1164 MF_Fahrerhinweis 0;
BA_ "GenSigSendType" SG_ 1164 MF_Generatordiagnose 0;
BA_ "GenSigStartValue" SG_ 1164 MF_Generatordiagnose 3;
BA_ "GenSigSwitchedByIgnition" SG_ 1164 MF_Generatordiagnose 0;
BA_ "GenSigSendType" SG_ 1164 MF_Heck_entriegeln 0;
BA_ "GenSigSendType" SG_ 1164 MF_Heck_verriegeln 0;
BA_ "GenSigSendType" SG_ 1164 MF_interm_Nebelscheinwerfer 0;
BA_ "GenSigSwitchedByIgnition" SG_ 1164 MF_interm_Nebelscheinwerfer 0;
BA_ "GenSigSendType" SG_ 1164 MF_Lampenausfall 0;
BA_ "GenSigSwitchedByIgnition" SG_ 1164 MF_Lampenausfall 0;
BA_ "GenSigSendType" SG_ 1164 MF_LSH_Abschaltstufe 0;
BA_ "GenSigSwitchedByIgnition" SG_ 1164 MF_LSH_Abschaltstufe 0;
BA_ "GenSigSendType" SG_ 1164 MF_LSH_Einschaltverbot 0;
BA_ "GenSigSwitchedByIgnition" SG_ 1164 MF_LSH_Einschaltverbot 0;
BA_ "GenSigSendType" SG_ 1164 MF_LSH_Zielzeit 0;
BA_ "GenSigStartValue" SG_ 1164 MF_LSH_Zielzeit 14;
BA_ "GenSigSwitchedByIgnition" SG_ 1164 MF_LSH_Zielzeit 0;
BA_ "Fehlerwert" SG_ 1164 MF_LSH_Zielzeit 15;
BA_ "GenSigSendType" SG_ 1164 MF_NotStartAktiv 0;
BA_ "GenSigSendType" SG_ 1164 MF_Radiomute 3;
BA_ "GenSigSwitchedByIgnition" SG_ 1164 MF_Radiomute 0;
BA_ "GenSigSendType" SG_ 1164 MF_Relais_2_Batterie 3;
BA_ "GenSigSwitchedByIgnition" SG_ 1164 MF_Relais_2_Batterie 0;
BA_ "GenSigSendType" SG_ 1164 MF_Tuerverriegelung_hinten 3;
BA_ "GenSigSwitchedByIgnition" SG_ 1164 MF_Tuerverriegelung_hinten 0;
BA_ "GenSigSendType" SG_ 1164 MF_ZV_Unlock 0;
BA_ "GenSigSwitchedByIgnition" SG_ 1164 MF_ZV_Unlock 0;
BA_ "GenSigSendType" SG_ 1164 MFG_AppConnect_Anf 4;
BA_ "GenSigSwitchedByIgnition" SG_ 1164 MFG_AppConnect_Anf 0;
BA_ "GenSigSendType" SG_ 1164 MFG_Infotainment_Autark 0;
BA_ "GenSigSwitchedByIgnition" SG_ 1164 MFG_Infotainment_Autark 0;
BA_ "GenSigSendType" SG_ 1164 MFG_Klappe_Status 0;
BA_ "GenSigSwitchedByIgnition" SG_ 1164 MFG_Klappe_Status 0;
BA_ "GenSigSendType" SG_ 1164 MFG_LSH_Ansteuerung 0;
BA_ "GenSigSwitchedByIgnition" SG_ 1164 MFG_LSH_Ansteuerung 0;
BA_ "GenSigSendType" SG_ 1164 MFG_LSH_Betriebsdauer 0;
BA_ "GenSigSwitchedByIgnition" SG_ 1164 MFG_LSH_Betriebsdauer 0;
BA_ "GenSigSendType" SG_ 1164 MFG_LSH_DBetr_Bestaet 0;
BA_ "GenSigSwitchedByIgnition" SG_ 1164 MFG_LSH_DBetr_Bestaet 0;
BA_ "GenSigSendType" SG_ 1164 MFG_LSH_DBetr_Ein 0;
BA_ "GenSigSwitchedByIgnition" SG_ 1164 MFG_LSH_DBetr_Ein 0;
BA_ "GenSigSendType" SG_ 2463978883 MF_DCDC_Istmodus 0;
BA_ "GenSigStartValue" SG_ 2463978883 MF_DCDC_Istmodus 7;
BA_ "GenSigSwitchedByIgnition" SG_ 2463978883 MF_DCDC_Istmodus 0;
BA_ "Fehlerwert" SG_ 2463978883 MF_DCDC_Istmodus 5;
BA_ "GenSigSendType" SG_ 2463978883 MF_Fahrerhinweis_2 0;
BA_ "GenSigSwitchedByIgnition" SG_ 2463978883 MF_Fahrerhinweis_2 0;
BA_ "GenSigSendType" SG_ 2463978883 MF_I_U_VorgabeZwang 0;
BA_ "GenSigSwitchedByIgnition" SG_ 2463978883 MF_I_U_VorgabeZwang 0;
BA_ "GenSigSendType" SG_ 2463978883 MF_U2Batt 0;
BA_ "GenSigStartValue" SG_ 2463978883 MF_U2Batt 255;
BA_ "GenSigSwitchedByIgnition" SG_ 2463978883 MF_U2Batt 0;
BA_ "GenSigSendType" SG_ 2463978883 MF_UBattVorgabe 0;
BA_ "GenSigStartValue" SG_ 2463978883 MF_UBattVorgabe 63;
BA_ "GenSigSwitchedByIgnition" SG_ 2463978883 MF_UBattVorgabe 0;
BA_ "GenSigSendType" SG_ 2463978883 MF_Vorfeldbel_Spiegel 0;
BA_ "GenSigSwitchedByIgnition" SG_ 2463978883 MF_Vorfeldbel_Spiegel 0;
BA_ "GenSigSendType" SG_ 1471 MFL_Eventcode_1 9;
BA_ "GenSigSwitchedByIgnition" SG_ 1471 MFL_Eventcode_1 0;
BA_ "GenSigSendType" SG_ 1471 MFL_Eventcode_2 9;
BA_ "GenSigSwitchedByIgnition" SG_ 1471 MFL_Eventcode_2 0;
BA_ "GenSigFuncType" SG_ 1471 MFL_Marke 8;
BA_ "GenSigSwitchedByIgnition" SG_ 1471 MFL_Marke 0;
BA_ "GenSigSendType" SG_ 1471 MFL_Tastencode_1 9;
BA_ "GenSigSwitchedByIgnition" SG_ 1471 MFL_Tastencode_1 0;
BA_ "GenSigSendType" SG_ 1471 MFL_Tastencode_2 9;
BA_ "GenSigSwitchedByIgnition" SG_ 1471 MFL_Tastencode_2 0;
BA_ "GenSigFuncType" SG_ 1471 MFL_Variante 8;
BA_ "GenSigSwitchedByIgnition" SG_ 1471 MFL_Variante 0;
BA_ "GenSigSendType" SG_ 2463978865 FaceRec2_Status_Challenge_Req 0;
BA_ "GenSigSwitchedByIgnition" SG_ 2463978865 FaceRec2_Status_Challenge_Req 0;
BA_ "GenSigSendType" SG_ 2463978865 FaceRec_Auth_Challenge_Request 0;
BA_ "GenSigSwitchedByIgnition" SG_ 2463978865 FaceRec_Auth_Challenge_Request 0;
BA_ "GenSigSendType" SG_ 2463978865 MIK_01_BZ 0;
BA_ "GenSigFuncType" SG_ 2463978865 MIK_01_BZ 1;
BA_ "GenSigSwitchedByIgnition" SG_ 2463978865 MIK_01_BZ 0;
BA_ "GenSigSendType" SG_ 2463978865 MIK_01_CRC 0;
BA_ "GenSigFuncType" SG_ 2463978865 MIK_01_CRC 2;
BA_ "GenSigSwitchedByIgnition" SG_ 2463978865 MIK_01_CRC 0;
BA_ "GenSigSendType" SG_ 2463978865 MIK_BlinkRate 0;
BA_ "GenSigStartValue" SG_ 2463978865 MIK_BlinkRate 30;
BA_ "GenSigSendType" SG_ 2463978865 MIK_CabinCare_Active 0;
BA_ "GenSigSendType" SG_ 2463978865 MIK_CabinCare_state 0;
BA_ "GenSigSwitchedByIgnition" SG_ 2463978865 MIK_CabinCare_state 0;
BA_ "GenSigSendType" SG_ 2463978865 MIK_ChildPresence 0;
BA_ "GenSigStartValue" SG_ 2463978865 MIK_ChildPresence 2;
BA_ "GenSigSwitchedByIgnition" SG_ 2463978865 MIK_ChildPresence 0;
BA_ "GenSigSendType" SG_ 2463978865 MIK_ChildStatus 0;
BA_ "GenSigSwitchedByIgnition" SG_ 2463978865 MIK_ChildStatus 0;
BA_ "GenSigSendType" SG_ 2463978865 MIK_DetectionMode 0;
BA_ "GenSigStartValue" SG_ 2463978865 MIK_DetectionMode 6;
BA_ "GenSigSendType" SG_ 2463978865 MIK_DriverChange 0;
BA_ "GenSigSendType" SG_ 2463978865 MIK_DriverPresence 0;
BA_ "GenSigStartValue" SG_ 2463978865 MIK_DriverPresence 6;
BA_ "GenSigSendType" SG_ 2463978865 MIK_DriverSmoking 0;
BA_ "GenSigStartValue" SG_ 2463978865 MIK_DriverSmoking 6;
BA_ "GenSigSendType" SG_ 2463978865 MIK_DriverSmokingQual 0;
BA_ "GenSigStartValue" SG_ 2463978865 MIK_DriverSmokingQual 14;
BA_ "GenSigSendType" SG_ 2463978865 MIK_DriverSpeaking 0;
BA_ "GenSigSendType" SG_ 2463978865 MIK_DriverTelephoneUsage 0;
BA_ "GenSigStartValue" SG_ 2463978865 MIK_DriverTelephoneUsage 6;
BA_ "GenSigSendType" SG_ 2463978865 MIK_DriverTelephoneUsageQual 0;
BA_ "GenSigStartValue" SG_ 2463978865 MIK_DriverTelephoneUsageQual 14;
BA_ "GenSigSendType" SG_ 2463978865 MIK_DriverYawning 0;
BA_ "GenSigStartValue" SG_ 2463978865 MIK_DriverYawning 6;
BA_ "GenSigSendType" SG_ 2463978865 MIK_DriverYawningQual 0;
BA_ "GenSigStartValue" SG_ 2463978865 MIK_DriverYawningQual 14;
BA_ "GenSigSendType" SG_ 2463978865 MIK_DrowsinessLevel 0;
BA_ "GenSigStartValue" SG_ 2463978865 MIK_DrowsinessLevel 14;
BA_ "GenSigSendType" SG_ 2463978865 MIK_DrowsinessLevelQual 0;
BA_ "GenSigStartValue" SG_ 2463978865 MIK_DrowsinessLevelQual 14;
BA_ "GenSigSendType" SG_ 2463978865 MIK_DurEyesCl 0;
BA_ "GenSigStartValue" SG_ 2463978865 MIK_DurEyesCl 126;
BA_ "GenSigSendType" SG_ 2463978865 MIK_DurEyesNotOnTfc 0;
BA_ "GenSigStartValue" SG_ 2463978865 MIK_DurEyesNotOnTfc 510;
BA_ "GenSigSendType" SG_ 2463978865 MIK_Fahrer_erkannt 0;
BA_ "GenSigSwitchedByIgnition" SG_ 2463978865 MIK_Fahrer_erkannt 0;
BA_ "Fehlerwert" SG_ 2463978865 MIK_Fahrer_erkannt 3;
BA_ "GenSigSendType" SG_ 2463978865 MIK_FakeDetected 0;
BA_ "GenSigSendType" SG_ 2463978865 MIK_ICC_RemoteAccessStatus 0;
BA_ "GenSigSwitchedByIgnition" SG_ 2463978865 MIK_ICC_RemoteAccessStatus 0;
BA_ "GenSigSendType" SG_ 2463978865 MIK_ICV_AspectRatio 0;
BA_ "GenSigSwitchedByIgnition" SG_ 2463978865 MIK_ICV_AspectRatio 0;
BA_ "GenSigSendType" SG_ 2463978865 MIK_ICV_Brightness 0;
BA_ "GenSigStartValue" SG_ 2463978865 MIK_ICV_Brightness 126;
BA_ "GenSigSwitchedByIgnition" SG_ 2463978865 MIK_ICV_Brightness 0;
BA_ "GenSigSendType" SG_ 2463978865 MIK_ICV_ColorMode 0;
BA_ "GenSigSwitchedByIgnition" SG_ 2463978865 MIK_ICV_ColorMode 0;
BA_ "GenSigSendType" SG_ 2463978865 MIK_ICV_Contrast 0;
BA_ "GenSigStartValue" SG_ 2463978865 MIK_ICV_Contrast 126;
BA_ "GenSigSwitchedByIgnition" SG_ 2463978865 MIK_ICV_Contrast 0;
BA_ "GenSigSendType" SG_ 2463978865 MIK_ICV_FieldOfView 0;
BA_ "GenSigSwitchedByIgnition" SG_ 2463978865 MIK_ICV_FieldOfView 0;
BA_ "GenSigSendType" SG_ 2463978865 MIK_ICV_FrameRate 0;
BA_ "GenSigStartValue" SG_ 2463978865 MIK_ICV_FrameRate 31;
BA_ "GenSigSwitchedByIgnition" SG_ 2463978865 MIK_ICV_FrameRate 0;
BA_ "GenSigSendType" SG_ 2463978865 MIK_ICV_FunctionState 0;
BA_ "GenSigSwitchedByIgnition" SG_ 2463978865 MIK_ICV_FunctionState 0;
BA_ "GenSigSendType" SG_ 2463978865 MIK_ICV_HDR 0;
BA_ "GenSigSwitchedByIgnition" SG_ 2463978865 MIK_ICV_HDR 0;
BA_ "GenSigSendType" SG_ 2463978865 MIK_ICV_Resolution 0;
BA_ "GenSigSwitchedByIgnition" SG_ 2463978865 MIK_ICV_Resolution 0;
BA_ "GenSigSendType" SG_ 2463978865 MIK_ICV_VideoLength 0;
BA_ "GenSigSwitchedByIgnition" SG_ 2463978865 MIK_ICV_VideoLength 0;
BA_ "GenSigSendType" SG_ 2463978865 MIK_ICV_Videostream_State 0;
BA_ "GenSigSwitchedByIgnition" SG_ 2463978865 MIK_ICV_Videostream_State 0;
BA_ "GenSigSendType" SG_ 2463978865 MIK_ICV_VideostreamResult 0;
BA_ "GenSigSwitchedByIgnition" SG_ 2463978865 MIK_ICV_VideostreamResult 0;
BA_ "GenSigSendType" SG_ 2463978865 MIK_LeftHandPos 0;
BA_ "GenSigStartValue" SG_ 2463978865 MIK_LeftHandPos 14;
BA_ "GenSigSendType" SG_ 2463978865 MIK_LeftHandPosQual 0;
BA_ "GenSigStartValue" SG_ 2463978865 MIK_LeftHandPosQual 14;
BA_ "GenSigSendType" SG_ 2463978865 MIK_Microsleep 0;
BA_ "GenSigStartValue" SG_ 2463978865 MIK_Microsleep 6;
BA_ "GenSigSendType" SG_ 2463978865 MIK_MicrosleepQual 0;
BA_ "GenSigStartValue" SG_ 2463978865 MIK_MicrosleepQual 14;
BA_ "GenSigSendType" SG_ 2463978865 MIK_PassengerPresence 0;
BA_ "GenSigSendType" SG_ 2463978865 MIK_PercentageEyesOnTraffic 0;
BA_ "GenSigStartValue" SG_ 2463978865 MIK_PercentageEyesOnTraffic 126;
BA_ "GenSigSendType" SG_ 2463978865 MIK_PetPresence 0;
BA_ "GenSigStartValue" SG_ 2463978865 MIK_PetPresence 2;
BA_ "GenSigSwitchedByIgnition" SG_ 2463978865 MIK_PetPresence 0;
BA_ "GenSigSendType" SG_ 2463978865 MIK_PetsMode_Active 0;
BA_ "GenSigSwitchedByIgnition" SG_ 2463978865 MIK_PetsMode_Active 0;
BA_ "GenSigSendType" SG_ 2463978865 MIK_RightHandPos 0;
BA_ "GenSigStartValue" SG_ 2463978865 MIK_RightHandPos 14;
BA_ "GenSigSendType" SG_ 2463978865 MIK_RightHandPosQual 0;
BA_ "GenSigStartValue" SG_ 2463978865 MIK_RightHandPosQual 14;
BA_ "GenSigSendType" SG_ 2463978865 MIK_Selfie_FunctionState 0;
BA_ "GenSigSwitchedByIgnition" SG_ 2463978865 MIK_Selfie_FunctionState 0;
BA_ "GenSigSendType" SG_ 2463978865 MIK_Selfie_Resolution 0;
BA_ "GenSigSwitchedByIgnition" SG_ 2463978865 MIK_Selfie_Resolution 0;
BA_ "GenSigSendType" SG_ 2463978865 MIK_SpaAttDstrAr_01 0;
BA_ "GenSigStartValue" SG_ 2463978865 MIK_SpaAttDstrAr_01 30;
BA_ "GenSigSendType" SG_ 2463978865 MIK_SpaAttDstrProb_01 0;
BA_ "GenSigStartValue" SG_ 2463978865 MIK_SpaAttDstrProb_01 14;
BA_ "GenSigSendType" SG_ 2463978865 MIK_Status 0;
BA_ "GenSigStartValue" SG_ 2463978865 MIK_Status 6;
BA_ "GenSigSendType" SG_ 2463978865 MIK_TotDurEyesNotOnTfc 0;
BA_ "GenSigStartValue" SG_ 2463978865 MIK_TotDurEyesNotOnTfc 1022;
BA_ "GenSigSendType" SG_ 2463978865 MIK_UnusualHeadPose 0;
BA_ "GenSigStartValue" SG_ 2463978865 MIK_UnusualHeadPose 6;
BA_ "GenSigSendType" SG_ 2463978865 MIK_UnusualHeadPoseQual 0;
BA_ "GenSigStartValue" SG_ 2463978865 MIK_UnusualHeadPoseQual 14;
BA_ "GenSigSendType" SG_ 2463978865 MIK_VisualDistractionLevel 0;
BA_ "GenSigStartValue" SG_ 2463978865 MIK_VisualDistractionLevel 6;
BA_ "GenSigSendType" SG_ 2463978865 MIK_VisualDistractionLevelQual 0;
BA_ "GenSigStartValue" SG_ 2463978865 MIK_VisualDistractionLevelQual 14;
BA_ "GenSigSendType" SG_ 2527679795 MKGO_FBS_01 1;
BA_ "GenSigSwitchedByIgnition" SG_ 2527679795 MKGO_FBS_01 0;
BA_ "GenSigSendType" SG_ 2527679796 MKGO_FBS_02 1;
BA_ "GenSigSwitchedByIgnition" SG_ 2527679796 MKGO_FBS_02 0;
BA_ "GenSigSendType" SG_ 2527679797 MKGO_FBS_03 1;
BA_ "GenSigSwitchedByIgnition" SG_ 2527679797 MKGO_FBS_03 0;
BA_ "GenSigSendType" SG_ 2527679798 MKGO_FBS_04 1;
BA_ "GenSigSwitchedByIgnition" SG_ 2527679798 MKGO_FBS_04 0;
BA_ "GenSigSendType" SG_ 2527679799 MKGO_FBS_05 1;
BA_ "GenSigSwitchedByIgnition" SG_ 2527679799 MKGO_FBS_05 0;
BA_ "GenSigSendType" SG_ 263 MO_Anzeigedrehz 0;
BA_ "GenSigSwitchedByIgnition" SG_ 263 MO_Anzeigedrehz 0;
BA_ "GenSigSendType" SG_ 263 MO_Effizienzmodus 0;
BA_ "GenSigSwitchedByIgnition" SG_ 263 MO_Effizienzmodus 0;
BA_ "GenSigSendType" SG_ 263 MO_Fehler_Oeldrucksensor 0;
BA_ "GenSigSwitchedByIgnition" SG_ 263 MO_Fehler_Oeldrucksensor 0;
BA_ "Fehlerwert" SG_ 263 MO_Fehler_Oeldrucksensor 1;
BA_ "GenSigSendType" SG_ 263 MO_Istgang 0;
BA_ "GenSigSwitchedByIgnition" SG_ 263 MO_Istgang 0;
BA_ "GenSigSendType" SG_ 263 MO_KVS 0;
BA_ "GenSigSwitchedByIgnition" SG_ 263 MO_KVS 0;
BA_ "GenSigSendType" SG_ 263 MO_KVS_Ueberlauf 0;
BA_ "GenSigSwitchedByIgnition" SG_ 263 MO_KVS_Ueberlauf 0;
BA_ "GenSigSendType" SG_ 263 MO_Ladedruck 0;
BA_ "GenSigSwitchedByIgnition" SG_ 263 MO_Ladedruck 0;
BA_ "Fehlerwert" SG_ 263 MO_Ladedruck 511;
BA_ "GenSigSendType" SG_ 263 MO_Oeldruck 0;
BA_ "GenSigStartValue" SG_ 263 MO_Oeldruck 254;
BA_ "GenSigSwitchedByIgnition" SG_ 263 MO_Oeldruck 0;
BA_ "Fehlerwert" SG_ 263 MO_Oeldruck 255;
BA_ "GenSigSendType" SG_ 263 MO_rel_Ladedruck 0;
BA_ "GenSigSwitchedByIgnition" SG_ 263 MO_rel_Ladedruck 0;
BA_ "Fehlerwert" SG_ 263 MO_rel_Ladedruck 255;
BA_ "GenSigSendType" SG_ 263 MO_Schaltempf_verfbar 0;
BA_ "GenSigSwitchedByIgnition" SG_ 263 MO_Schaltempf_verfbar 0;
BA_ "GenSigSendType" SG_ 263 MO_Sollgang 0;
BA_ "GenSigSwitchedByIgnition" SG_ 263 MO_Sollgang 0;
BA_ "GenSigSendType" SG_ 1600 MO_Absperrventil_oeffnen 0;
BA_ "GenSigSwitchedByIgnition" SG_ 1600 MO_Absperrventil_oeffnen 0;
BA_ "GenSigSendType" SG_ 1600 MO_aktives_Getriebeheizen 0;
BA_ "GenSigSwitchedByIgnition" SG_ 1600 MO_aktives_Getriebeheizen 0;
BA_ "GenSigSendType" SG_ 1600 MO_Ansaugluft_Temp 0;
BA_ "GenSigStartValue" SG_ 1600 MO_Ansaugluft_Temp 254;
BA_ "GenSigSwitchedByIgnition" SG_ 1600 MO_Ansaugluft_Temp 0;
BA_ "Fehlerwert" SG_ 1600 MO_Ansaugluft_Temp 255;
BA_ "GenSigSendType" SG_ 1600 MO_Getriebe_kuehlen 0;
BA_ "GenSigSwitchedByIgnition" SG_ 1600 MO_Getriebe_kuehlen 0;
BA_ "GenSigSendType" SG_ 1600 MO_Heizungspumpenansteuerung 0;
BA_ "GenSigStartValue" SG_ 1600 MO_Heizungspumpenansteuerung 14;
BA_ "GenSigSwitchedByIgnition" SG_ 1600 MO_Heizungspumpenansteuerung 0;
BA_ "Fehlerwert" SG_ 1600 MO_Heizungspumpenansteuerung 13;
BA_ "GenSigSendType" SG_ 1600 MO_Hoeheninfo 0;
BA_ "GenSigSwitchedByIgnition" SG_ 1600 MO_Hoeheninfo 0;
BA_ "Fehlerwert" SG_ 1600 MO_Hoeheninfo 255;
BA_ "GenSigSendType" SG_ 1600 MO_HYB_Fehler_HV_Netz 0;
BA_ "GenSigSwitchedByIgnition" SG_ 1600 MO_HYB_Fehler_HV_Netz 0;
BA_ "GenSigSendType" SG_ 1600 MO_Kennfeldk 0;
BA_ "GenSigSwitchedByIgnition" SG_ 1600 MO_Kennfeldk 0;
BA_ "GenSigSendType" SG_ 1600 MO_KL15_Abschaltempfehlung 0;
BA_ "GenSigSwitchedByIgnition" SG_ 1600 MO_KL15_Abschaltempfehlung 0;
BA_ "GenSigSendType" SG_ 1600 MO_Kuehlmittel_Temp 0;
BA_ "GenSigStartValue" SG_ 1600 MO_Kuehlmittel_Temp 254;
BA_ "GenSigSwitchedByIgnition" SG_ 1600 MO_Kuehlmittel_Temp 0;
BA_ "Fehlerwert" SG_ 1600 MO_Kuehlmittel_Temp 255;
BA_ "GenSigSendType" SG_ 1600 MO_Mom_Traegheit_02 0;
BA_ "GenSigSwitchedByIgnition" SG_ 1600 MO_Mom_Traegheit_02 0;
BA_ "GenSigSendType" SG_ 1600 MO_Nachlaufzeit_Heizungspumpe 0;
BA_ "GenSigSwitchedByIgnition" SG_ 1600 MO_Nachlaufzeit_Heizungspumpe 0;
BA_ "GenSigSendType" SG_ 1600 MO_Oel_Temp 0;
BA_ "GenSigStartValue" SG_ 1600 MO_Oel_Temp 254;
BA_ "GenSigSwitchedByIgnition" SG_ 1600 MO_Oel_Temp 0;
BA_ "Fehlerwert" SG_ 1600 MO_Oel_Temp 255;
BA_ "GenSigSendType" SG_ 1600 MO_QBit_Ansaugluft_Temp 0;
BA_ "GenSigStartValue" SG_ 1600 MO_QBit_Ansaugluft_Temp 1;
BA_ "GenSigSwitchedByIgnition" SG_ 1600 MO_QBit_Ansaugluft_Temp 0;
BA_ "GenSigSendType" SG_ 1600 MO_QBit_Hoeheninfo 0;
BA_ "GenSigStartValue" SG_ 1600 MO_QBit_Hoeheninfo 1;
BA_ "GenSigSwitchedByIgnition" SG_ 1600 MO_QBit_Hoeheninfo 0;
BA_ "GenSigSendType" SG_ 1600 MO_QBit_Kuehlmittel_Temp 0;
BA_ "GenSigStartValue" SG_ 1600 MO_QBit_Kuehlmittel_Temp 1;
BA_ "GenSigSwitchedByIgnition" SG_ 1600 MO_QBit_Kuehlmittel_Temp 0;
BA_ "GenSigSendType" SG_ 1600 MO_QBit_Oel_Temp 0;
BA_ "GenSigStartValue" SG_ 1600 MO_QBit_Oel_Temp 1;
BA_ "GenSigSwitchedByIgnition" SG_ 1600 MO_QBit_Oel_Temp 0;
BA_ "GenSigSendType" SG_ 1600 MO_SpannungsAnf 0;
BA_ "GenSigSwitchedByIgnition" SG_ 1600 MO_SpannungsAnf 0;
BA_ "GenSigSendType" SG_ 1600 MO_Versionsinfo_02 0;
BA_ "GenSigSwitchedByIgnition" SG_ 1600 MO_Versionsinfo_02 0;
BA_ "GenSigSendType" SG_ 958 MO_Aussp_Anlass 3;
BA_ "GenSigSwitchedByIgnition" SG_ 958 MO_Aussp_Anlass 0;
BA_ "GenSigSendType" SG_ 958 MO_BKV_Unterdruckwarnung 0;
BA_ "GenSigSwitchedByIgnition" SG_ 958 MO_BKV_Unterdruckwarnung 0;
BA_ "GenSigSendType" SG_ 958 MO_BLS 3;
BA_ "GenSigSwitchedByIgnition" SG_ 958 MO_BLS 0;
BA_ "GenSigSendType" SG_ 958 MO_BMS_NV_Anf_stuetzen 3;
BA_ "GenSigSwitchedByIgnition" SG_ 958 MO_BMS_NV_Anf_stuetzen 0;
BA_ "GenSigSendType" SG_ 958 MO_EKlKomLeiRed 0;
BA_ "GenSigSwitchedByIgnition" SG_ 958 MO_EKlKomLeiRed 0;
BA_ "GenSigSendType" SG_ 958 MO_Ext_E_Fahrt_aktiv 3;
BA_ "NWM-WakeupAllowed" SG_ 958 MO_Ext_E_Fahrt_aktiv 1;
BA_ "GenSigSwitchedByIgnition" SG_ 958 MO_Ext_E_Fahrt_aktiv 0;
BA_ "GenSigSendType" SG_ 958 MO_Fahrer_bremst 3;
BA_ "GenSigSwitchedByIgnition" SG_ 958 MO_Fahrer_bremst 0;
BA_ "GenSigSendType" SG_ 958 MO_FMAus_aktiv 3;
BA_ "GenSigSwitchedByIgnition" SG_ 958 MO_FMAus_aktiv 0;
BA_ "GenSigSendType" SG_ 958 MO_FMAus_Startvariante 3;
BA_ "GenSigSwitchedByIgnition" SG_ 958 MO_FMAus_Startvariante 0;
BA_ "GenSigSendType" SG_ 958 MO_Freig_Anlass 3;
BA_ "GenSigSwitchedByIgnition" SG_ 958 MO_Freig_Anlass 0;
BA_ "GenSigSendType" SG_ 958 MO_Freig_Reku 0;
BA_ "GenSigSwitchedByIgnition" SG_ 958 MO_Freig_Reku 0;
BA_ "GenSigSendType" SG_ 958 MO_Freigabe_Segeln 0;
BA_ "GenSigSwitchedByIgnition" SG_ 958 MO_Freigabe_Segeln 0;
BA_ "GenSigSendType" SG_ 958 MO_Gangposition 3;
BA_ "GenSigStartValue" SG_ 958 MO_Gangposition 14;
BA_ "GenSigSwitchedByIgnition" SG_ 958 MO_Gangposition 0;
BA_ "Fehlerwert" SG_ 958 MO_Gangposition 15;
BA_ "GenSigSendType" SG_ 958 MO_Handshake_STH 0;
BA_ "GenSigSwitchedByIgnition" SG_ 958 MO_Handshake_STH 0;
BA_ "GenSigSendType" SG_ 958 MO_HYB_Fahrbereitschaft 0;
BA_ "GenSigSwitchedByIgnition" SG_ 958 MO_HYB_Fahrbereitschaft 0;
BA_ "GenSigSendType" SG_ 958 MO_HYB_VM_aktiv 3;
BA_ "GenSigSwitchedByIgnition" SG_ 958 MO_HYB_VM_aktiv 0;
BA_ "GenSigSendType" SG_ 958 MO_Interlock 3;
BA_ "GenSigSwitchedByIgnition" SG_ 958 MO_Interlock 0;
BA_ "GenSigSendType" SG_ 958 MO_Kickdown 3;
BA_ "GenSigSwitchedByIgnition" SG_ 958 MO_Kickdown 0;
BA_ "GenSigSendType" SG_ 958 MO_Kl_50 3;
BA_ "GenSigSwitchedByIgnition" SG_ 958 MO_Kl_50 0;
BA_ "GenSigSendType" SG_ 958 MO_Kl_75 3;
BA_ "GenSigSwitchedByIgnition" SG_ 958 MO_Kl_75 0;
BA_ "GenSigSendType" SG_ 958 MO_Klima_Eingr 3;
BA_ "GenSigSwitchedByIgnition" SG_ 958 MO_Klima_Eingr 0;
BA_ "GenSigSendType" SG_ 958 MO_Konsistenz_Bremsped 3;
BA_ "GenSigSwitchedByIgnition" SG_ 958 MO_Konsistenz_Bremsped 0;
BA_ "GenSigSendType" SG_ 958 MO_Kuppl_schalter 3;
BA_ "GenSigSwitchedByIgnition" SG_ 958 MO_Kuppl_schalter 0;
BA_ "GenSigSendType" SG_ 958 MO_Motor_laeuft 3;
BA_ "GenSigSwitchedByIgnition" SG_ 958 MO_Motor_laeuft 0;
BA_ "GenSigSendType" SG_ 958 MO_PTC_Status 0;
BA_ "GenSigSwitchedByIgnition" SG_ 958 MO_PTC_Status 0;
BA_ "GenSigSendType" SG_ 958 MO_QBit_Fahrer_bremst 3;
BA_ "GenSigStartValue" SG_ 958 MO_QBit_Fahrer_bremst 1;
BA_ "GenSigSwitchedByIgnition" SG_ 958 MO_QBit_Fahrer_bremst 0;
BA_ "GenSigSendType" SG_ 958 MO_QBit_Gangposition 3;
BA_ "GenSigStartValue" SG_ 958 MO_QBit_Gangposition 1;
BA_ "GenSigSwitchedByIgnition" SG_ 958 MO_QBit_Gangposition 0;
BA_ "GenSigSendType" SG_ 958 MO_QBit_KL_75 3;
BA_ "GenSigStartValue" SG_ 958 MO_QBit_KL_75 1;
BA_ "GenSigSwitchedByIgnition" SG_ 958 MO_QBit_KL_75 0;
BA_ "GenSigSendType" SG_ 958 MO_Remotestart_Betrieb 3;
BA_ "GenSigSwitchedByIgnition" SG_ 958 MO_Remotestart_Betrieb 0;
BA_ "GenSigSendType" SG_ 958 MO_Remotestart_moeglich 0;
BA_ "GenSigSwitchedByIgnition" SG_ 958 MO_Remotestart_moeglich 0;
BA_ "GenSigSendType" SG_ 958 MO_Signalquelle_Gangposition 0;
BA_ "GenSigSwitchedByIgnition" SG_ 958 MO_Signalquelle_Gangposition 0;
BA_ "GenSigSendType" SG_ 958 MO_StartStopp_Fahrerwunsch 0;
BA_ "GenSigSwitchedByIgnition" SG_ 958 MO_StartStopp_Fahrerwunsch 0;
BA_ "GenSigSendType" SG_ 958 MO_StartStopp_Motorstopp 3;
BA_ "GenSigSwitchedByIgnition" SG_ 958 MO_StartStopp_Motorstopp 0;
BA_ "GenSigSendType" SG_ 958 MO_StartStopp_Status 0;
BA_ "GenSigSwitchedByIgnition" SG_ 958 MO_StartStopp_Status 0;
BA_ "GenSigSendType" SG_ 958 MO_StartStopp_Wiederstart 3;
BA_ "GenSigSwitchedByIgnition" SG_ 958 MO_StartStopp_Wiederstart 0;
BA_ "GenSigSendType" SG_ 958 MO_StartVorauss_erfuellt 3;
BA_ "GenSigStartValue" SG_ 958 MO_StartVorauss_erfuellt 1;
BA_ "GenSigSwitchedByIgnition" SG_ 958 MO_StartVorauss_erfuellt 0;
BA_ "GenSigSendType" SG_ 958 MO_Timeout_ESP 3;
BA_ "GenSigSwitchedByIgnition" SG_ 958 MO_Timeout_ESP 0;
BA_ "GenSigSendType" SG_ 958 MO_Zylinderabschaltung 3;
BA_ "GenSigSwitchedByIgnition" SG_ 958 MO_Zylinderabschaltung 0;
BA_ "GenSigSendType" SG_ 958 Motor_14_BZ 0;
BA_ "GenSigFuncType" SG_ 958 Motor_14_BZ 1;
BA_ "GenSigSwitchedByIgnition" SG_ 958 Motor_14_BZ 0;
BA_ "GenSigSendType" SG_ 958 Motor_14_CRC 0;
BA_ "GenSigFuncType" SG_ 958 Motor_14_CRC 2;
BA_ "GenSigSwitchedByIgnition" SG_ 958 Motor_14_CRC 0;
BA_ "GenSigSendType" SG_ 1648 MO1_Freigabe_Info_WFS 3;
BA_ "GenSigSwitchedByIgnition" SG_ 1648 MO1_Freigabe_Info_WFS 0;
BA_ "GenSigSendType" SG_ 1648 MO1_Freigabe_Verfallsinfo_WFS 3;
BA_ "GenSigSwitchedByIgnition" SG_ 1648 MO1_Freigabe_Verfallsinfo_WFS 0;
BA_ "GenSigSendType" SG_ 1648 MO1_Sperr_Info_WFS 3;
BA_ "GenSigSwitchedByIgnition" SG_ 1648 MO1_Sperr_Info_WFS 0;
BA_ "GenSigSendType" SG_ 1648 MO_Abstellzeit 0;
BA_ "GenSigStartValue" SG_ 1648 MO_Abstellzeit 254;
BA_ "GenSigSwitchedByIgnition" SG_ 1648 MO_Abstellzeit 0;
BA_ "GenSigSendType" SG_ 1648 MO_Abstellzeit_Status 0;
BA_ "GenSigSwitchedByIgnition" SG_ 1648 MO_Abstellzeit_Status 0;
BA_ "GenSigSendType" SG_ 1648 MO_ANC_Kennfeld_Anf 3;
BA_ "GenSigSwitchedByIgnition" SG_ 1648 MO_ANC_Kennfeld_Anf 0;
BA_ "GenSigSendType" SG_ 1648 MO_Anzahl_Abgesch_Zyl 3;
BA_ "GenSigSwitchedByIgnition" SG_ 1648 MO_Anzahl_Abgesch_Zyl 0;
BA_ "GenSigSendType" SG_ 1648 MO_Bremslicht_Reku 3;
BA_ "GenSigSwitchedByIgnition" SG_ 1648 MO_Bremslicht_Reku 0;
BA_ "GenSigSendType" SG_ 1648 MO_Drehzahl_Warnung 0;
BA_ "GenSigSwitchedByIgnition" SG_ 1648 MO_Drehzahl_Warnung 0;
BA_ "GenSigSendType" SG_ 1648 MO_EPCL 3;
BA_ "GenSigSwitchedByIgnition" SG_ 1648 MO_EPCL 0;
BA_ "GenSigSendType" SG_ 1648 MO_Ethanol_BS_Texte 0;
BA_ "GenSigSwitchedByIgnition" SG_ 1648 MO_Ethanol_BS_Texte 0;
BA_ "GenSigSendType" SG_ 1648 MO_Fahrzeugtyp 0;
BA_ "GenSigFuncType" SG_ 1648 MO_Fahrzeugtyp 8;
BA_ "GenSigSwitchedByIgnition" SG_ 1648 MO_Fahrzeugtyp 0;
BA_ "GenSigSendType" SG_ 1648 MO_Fehler_Zylabsch 0;
BA_ "GenSigSwitchedByIgnition" SG_ 1648 MO_Fehler_Zylabsch 0;
BA_ "GenSigSendType" SG_ 1648 MO_Hybrid_StartStopp_LED 3;
BA_ "GenSigSwitchedByIgnition" SG_ 1648 MO_Hybrid_StartStopp_LED 0;
BA_ "GenSigSendType" SG_ 1648 MO_max_Ladedruck 0;
BA_ "GenSigFuncType" SG_ 1648 MO_max_Ladedruck 8;
BA_ "GenSigSwitchedByIgnition" SG_ 1648 MO_max_Ladedruck 0;
BA_ "GenSigSendType" SG_ 1648 MO_NMAX_Schaltanzeige 3;
BA_ "GenSigSwitchedByIgnition" SG_ 1648 MO_NMAX_Schaltanzeige 0;
BA_ "GenSigSendType" SG_ 1648 MO_obere_Drehzahlgrenze 0;
BA_ "GenSigSwitchedByIgnition" SG_ 1648 MO_obere_Drehzahlgrenze 0;
BA_ "GenSigSendType" SG_ 1648 MO_StartStopp_PopUp 3;
BA_ "GenSigSwitchedByIgnition" SG_ 1648 MO_StartStopp_PopUp 0;
BA_ "GenSigSendType" SG_ 1648 MO_Zylabsch_Texte 0;
BA_ "GenSigSwitchedByIgnition" SG_ 1648 MO_Zylabsch_Texte 0;
BA_ "GenSigSendType" SG_ 1648 MO_Zylabsch_Texte_02 3;
BA_ "GenSigSwitchedByIgnition" SG_ 1648 MO_Zylabsch_Texte_02 0;
BA_ "GenSigSendType" SG_ 967 MO_E_Mode 0;
BA_ "GenSigSwitchedByIgnition" SG_ 967 MO_E_Mode 0;
BA_ "GenSigSendType" SG_ 967 MO_E_Texte 0;
BA_ "GenSigSwitchedByIgnition" SG_ 967 MO_E_Texte 0;
BA_ "GenSigSendType" SG_ 967 MO_E_Warnungen 0;
BA_ "GenSigSwitchedByIgnition" SG_ 967 MO_E_Warnungen 0;
BA_ "GenSigSendType" SG_ 967 MO_EFLEX_Lampe 0;
BA_ "GenSigSwitchedByIgnition" SG_ 967 MO_EFLEX_Lampe 0;
BA_ "GenSigSendType" SG_ 967 MO_Heissleuchte 0;
BA_ "GenSigSwitchedByIgnition" SG_ 967 MO_Heissleuchte 0;
BA_ "GenSigSendType" SG_ 967 MO_ITM_Warnung_Pumpe 0;
BA_ "GenSigSwitchedByIgnition" SG_ 967 MO_ITM_Warnung_Pumpe 0;
BA_ "GenSigSendType" SG_ 967 MO_KJS_nicht_bereit 0;
BA_ "GenSigSwitchedByIgnition" SG_ 967 MO_KJS_nicht_bereit 0;
BA_ "Fehlerwert" SG_ 967 MO_KJS_nicht_bereit 1;
BA_ "GenSigStartValue" SG_ 967 MO_Kuehlerluefter_1 126;
BA_ "GenSigSwitchedByIgnition" SG_ 967 MO_Kuehlerluefter_1 0;
BA_ "Fehlerwert" SG_ 967 MO_Kuehlerluefter_1 127;
BA_ "GenSigStartValue" SG_ 967 MO_Kuehlerluefter_2 126;
BA_ "GenSigSwitchedByIgnition" SG_ 967 MO_Kuehlerluefter_2 0;
BA_ "Fehlerwert" SG_ 967 MO_Kuehlerluefter_2 127;
BA_ "GenSigSendType" SG_ 967 MO_Kuehlerluefter_MUX 0;
BA_ "GenSigSwitchedByIgnition" SG_ 967 MO_Kuehlerluefter_MUX 0;
BA_ "GenSigSendType" SG_ 967 MO_OBD2_Lampe 0;
BA_ "GenSigSwitchedByIgnition" SG_ 967 MO_OBD2_Lampe 0;
BA_ "GenSigSendType" SG_ 967 MO_Oelwarnung_max 0;
BA_ "GenSigSwitchedByIgnition" SG_ 967 MO_Oelwarnung_max 0;
BA_ "GenSigSendType" SG_ 967 MO_Partikel_Lampe 0;
BA_ "GenSigSwitchedByIgnition" SG_ 967 MO_Partikel_Lampe 0;
BA_ "GenSigSendType" SG_ 967 MO_RedFahrleistung_Lampe 0;
BA_ "GenSigSwitchedByIgnition" SG_ 967 MO_RedFahrleistung_Lampe 0;
BA_ "GenSigSendType" SG_ 967 MO_Systemlampe 0;
BA_ "GenSigSwitchedByIgnition" SG_ 967 MO_Systemlampe 0;
BA_ "GenSigSendType" SG_ 967 MO_Tankdeckel_Lampe 0;
BA_ "GenSigSwitchedByIgnition" SG_ 967 MO_Tankdeckel_Lampe 0;
BA_ "GenSigSendType" SG_ 967 MO_Text_Motorstart 0;
BA_ "GenSigSwitchedByIgnition" SG_ 967 MO_Text_Motorstart 0;
BA_ "GenSigSendType" SG_ 967 MO_Text_Partikelfil_Reg 0;
BA_ "GenSigSwitchedByIgnition" SG_ 967 MO_Text_Partikelfil_Reg 0;
BA_ "GenSigSendType" SG_ 967 MO_Text_Tankdeckelwarn 0;
BA_ "GenSigSwitchedByIgnition" SG_ 967 MO_Text_Tankdeckelwarn 0;
BA_ "GenSigSendType" SG_ 967 MO_Vorglueh_Lampe 0;
BA_ "GenSigSwitchedByIgnition" SG_ 967 MO_Vorglueh_Lampe 0;
BA_ "GenSigSendType" SG_ 967 MO_Zustand_HWP 0;
BA_ "GenSigStartValue" SG_ 967 MO_Zustand_HWP 1;
BA_ "GenSigSwitchedByIgnition" SG_ 967 MO_Zustand_HWP 0;
BA_ "GenSigSendType" SG_ 967 OLEV_Oelstand_nicht_vorhanden 0;
BA_ "GenSigSwitchedByIgnition" SG_ 967 OLEV_Oelstand_nicht_vorhanden 0;
BA_ "GenSigSendType" SG_ 967 OLEV_Systemstoerung 0;
BA_ "GenSigSwitchedByIgnition" SG_ 967 OLEV_Systemstoerung 0;
BA_ "GenSigSendType" SG_ 967 WIV_Anzeige_aktiv 0;
BA_ "GenSigSwitchedByIgnition" SG_ 967 WIV_Anzeige_aktiv 0;
BA_ "GenSigSendType" SG_ 967 WIV_laufender_Motor 0;
BA_ "GenSigSwitchedByIgnition" SG_ 967 WIV_laufender_Motor 0;
BA_ "GenSigSendType" SG_ 967 WIV_nachfuellanzeige_ein 0;
BA_ "GenSigSwitchedByIgnition" SG_ 967 WIV_nachfuellanzeige_ein 0;
BA_ "GenSigSendType" SG_ 967 WIV_nicht_betriebswarm 0;
BA_ "GenSigSwitchedByIgnition" SG_ 967 WIV_nicht_betriebswarm 0;
BA_ "GenSigSendType" SG_ 967 WIV_Oeldr_Warn_Motor 0;
BA_ "GenSigSwitchedByIgnition" SG_ 967 WIV_Oeldr_Warn_Motor 0;
BA_ "GenSigSendType" SG_ 967 WIV_Oeldyn_avl 0;
BA_ "GenSigSwitchedByIgnition" SG_ 967 WIV_Oeldyn_avl 0;
BA_ "GenSigSendType" SG_ 967 WIV_Oelmenge 0;
BA_ "GenSigSwitchedByIgnition" SG_ 967 WIV_Oelmenge 0;
BA_ "GenSigSendType" SG_ 967 WIV_Oelmin_Warn 0;
BA_ "GenSigSwitchedByIgnition" SG_ 967 WIV_Oelmin_Warn 0;
BA_ "GenSigSendType" SG_ 967 WIV_Oelstand 0;
BA_ "GenSigSwitchedByIgnition" SG_ 967 WIV_Oelstand 0;
BA_ "GenSigSendType" SG_ 967 WIV_Oelstand_nicht_vorhanden 0;
BA_ "GenSigSwitchedByIgnition" SG_ 967 WIV_Oelstand_nicht_vorhanden 0;
BA_ "GenSigSendType" SG_ 967 WIV_Oelsystem_aktiv 0;
BA_ "GenSigSwitchedByIgnition" SG_ 967 WIV_Oelsystem_aktiv 0;
BA_ "GenSigSendType" SG_ 967 WIV_Schieflage 0;
BA_ "GenSigSwitchedByIgnition" SG_ 967 WIV_Schieflage 0;
BA_ "GenSigSendType" SG_ 967 WIV_Sensorfehler 0;
BA_ "GenSigSwitchedByIgnition" SG_ 967 WIV_Sensorfehler 0;
BA_ "GenSigSendType" SG_ 967 WIV_Ueberfuell_deaktiv 0;
BA_ "GenSigSwitchedByIgnition" SG_ 967 WIV_Ueberfuell_deaktiv 0;
BA_ "GenSigSendType" SG_ 967 WIV_Ueberfuell_Warn 0;
BA_ "GenSigSwitchedByIgnition" SG_ 967 WIV_Ueberfuell_Warn 0;
BA_ "GenSigSendType" SG_ 967 WIV_Unterfuell_Warn 0;
BA_ "GenSigSwitchedByIgnition" SG_ 967 WIV_Unterfuell_Warn 0;
BA_ "GenSigSendType" SG_ 267 MO_Entkopplung_Sollschlupf 0;
BA_ "GenSigStartValue" SG_ 267 MO_Entkopplung_Sollschlupf 126;
BA_ "GenSigSwitchedByIgnition" SG_ 267 MO_Entkopplung_Sollschlupf 0;
BA_ "GenSigSendType" SG_ 267 MO_Fahrpedalgradient 0;
BA_ "GenSigSwitchedByIgnition" SG_ 267 MO_Fahrpedalgradient 0;
BA_ "Fehlerwert" SG_ 267 MO_Fahrpedalgradient 255;
BA_ "GenSigSendType" SG_ 267 MO_Fahrpedalrohwert_01 0;
BA_ "GenSigSwitchedByIgnition" SG_ 267 MO_Fahrpedalrohwert_01 0;
BA_ "Fehlerwert" SG_ 267 MO_Fahrpedalrohwert_01 255;
BA_ "GenSigSendType" SG_ 267 MO_Moment_im_Leerlauf 0;
BA_ "GenSigSwitchedByIgnition" SG_ 267 MO_Moment_im_Leerlauf 0;
BA_ "GenSigSendType" SG_ 267 MO_QBit_Fahrpedalwerte_01 0;
BA_ "GenSigStartValue" SG_ 267 MO_QBit_Fahrpedalwerte_01 1;
BA_ "GenSigSwitchedByIgnition" SG_ 267 MO_QBit_Fahrpedalwerte_01 0;
BA_ "GenSigSendType" SG_ 267 MO_rel_Saugrohrdruck 0;
BA_ "GenSigSwitchedByIgnition" SG_ 267 MO_rel_Saugrohrdruck 0;
BA_ "Fehlerwert" SG_ 267 MO_rel_Saugrohrdruck 63;
BA_ "GenSigSendType" SG_ 267 MO_rel_Saugrohrdruck_gem_err 0;
BA_ "GenSigSwitchedByIgnition" SG_ 267 MO_rel_Saugrohrdruck_gem_err 0;
BA_ "GenSigSendType" SG_ 267 MO_Schubabschaltung 0;
BA_ "GenSigSwitchedByIgnition" SG_ 267 MO_Schubabschaltung 0;
BA_ "GenSigSendType" SG_ 267 MO_Sig_Fahrpedalgradient 0;
BA_ "GenSigSwitchedByIgnition" SG_ 267 MO_Sig_Fahrpedalgradient 0;
BA_ "GenSigSendType" SG_ 267 MO_Solldrehz_Leerlauf 0;
BA_ "GenSigSwitchedByIgnition" SG_ 267 MO_Solldrehz_Leerlauf 0;
BA_ "GenSigSendType" SG_ 267 MO_StartStopp_StoppVorbereitung 0;
BA_ "GenSigSwitchedByIgnition" SG_ 267 MO_StartStopp_StoppVorbereitung 0;
BA_ "GenSigSendType" SG_ 267 MO_Status_MaxDrzEingriff 0;
BA_ "GenSigSwitchedByIgnition" SG_ 267 MO_Status_MaxDrzEingriff 0;
BA_ "GenSigSendType" SG_ 267 MO_Status_MaxDrzEingriff_sek 0;
BA_ "GenSigSwitchedByIgnition" SG_ 267 MO_Status_MaxDrzEingriff_sek 0;
BA_ "GenSigSendType" SG_ 267 MO_Status_MinDrzEingriff 0;
BA_ "GenSigSwitchedByIgnition" SG_ 267 MO_Status_MinDrzEingriff 0;
BA_ "GenSigSendType" SG_ 267 MO_Status_MinDrzEingriff_sek 0;
BA_ "GenSigSwitchedByIgnition" SG_ 267 MO_Status_MinDrzEingriff_sek 0;
BA_ "GenSigSendType" SG_ 267 MO_temporaere_Fahrerabwesenheit 0;
BA_ "GenSigSwitchedByIgnition" SG_ 267 MO_temporaere_Fahrerabwesenheit 0;
BA_ "GenSigSendType" SG_ 267 Motor_51_BZ 0;
BA_ "GenSigFuncType" SG_ 267 Motor_51_BZ 1;
BA_ "GenSigSwitchedByIgnition" SG_ 267 Motor_51_BZ 0;
BA_ "GenSigSendType" SG_ 267 Motor_51_CRC 0;
BA_ "GenSigFuncType" SG_ 267 Motor_51_CRC 2;
BA_ "GenSigSwitchedByIgnition" SG_ 267 Motor_51_CRC 0;
BA_ "GenSigSendType" SG_ 267 SOK_Motor_51_Signatur 0;
BA_ "GenSigFuncType" SG_ 267 SOK_Motor_51_Signatur 15;
BA_ "GenSigSendType" SG_ 267 TSK_a_Soll_gradientenbegrenzt 0;
BA_ "GenSigStartValue" SG_ 267 TSK_a_Soll_gradientenbegrenzt 127;
BA_ "GenSigSwitchedByIgnition" SG_ 267 TSK_a_Soll_gradientenbegrenzt 0;
BA_ "GenSigSendType" SG_ 267 TSK_ax_Getriebe_02 0;
BA_ "GenSigStartValue" SG_ 267 TSK_ax_Getriebe_02 511;
BA_ "GenSigSwitchedByIgnition" SG_ 267 TSK_ax_Getriebe_02 0;
BA_ "GenSigSendType" SG_ 267 TSK_Freig_Verzoeg_Anf 0;
BA_ "GenSigSwitchedByIgnition" SG_ 267 TSK_Freig_Verzoeg_Anf 0;
BA_ "GenSigSendType" SG_ 267 TSK_Hauptschalter_GRA_ACC 0;
BA_ "GenSigSwitchedByIgnition" SG_ 267 TSK_Hauptschalter_GRA_ACC 0;
BA_ "Fehlerwert" SG_ 267 TSK_Hauptschalter_GRA_ACC 3;
BA_ "GenSigSendType" SG_ 267 TSK_Kategorie_Verzoegerungsfkt 0;
BA_ "GenSigSwitchedByIgnition" SG_ 267 TSK_Kategorie_Verzoegerungsfkt 0;
BA_ "GenSigSendType" SG_ 267 TSK_Limiter_ausgewaehlt 0;
BA_ "GenSigSwitchedByIgnition" SG_ 267 TSK_Limiter_ausgewaehlt 0;
BA_ "GenSigSendType" SG_ 267 TSK_Notstopp_Anf 0;
BA_ "GenSigSwitchedByIgnition" SG_ 267 TSK_Notstopp_Anf 0;
BA_ "GenSigSendType" SG_ 267 TSK_Radbremsmom 0;
BA_ "GenSigSwitchedByIgnition" SG_ 267 TSK_Radbremsmom 0;
BA_ "GenSigSendType" SG_ 267 TSK_Radsollmoment 0;
BA_ "GenSigStartValue" SG_ 267 TSK_Radsollmoment 65534;
BA_ "GenSigSwitchedByIgnition" SG_ 267 TSK_Radsollmoment 0;
BA_ "Fehlerwert" SG_ 267 TSK_Radsollmoment 65535;
BA_ "GenSigSendType" SG_ 267 TSK_SRBM_Anf_ASIL 0;
BA_ "GenSigSwitchedByIgnition" SG_ 267 TSK_SRBM_Anf_ASIL 0;
BA_ "GenSigSendType" SG_ 267 TSK_SRBM_max_Gradient 0;
BA_ "GenSigStartValue" SG_ 267 TSK_SRBM_max_Gradient 126;
BA_ "GenSigSwitchedByIgnition" SG_ 267 TSK_SRBM_max_Gradient 0;
BA_ "Fehlerwert" SG_ 267 TSK_SRBM_max_Gradient 127;
BA_ "GenSigSendType" SG_ 267 TSK_Standby_Anf_ESP 0;
BA_ "GenSigSwitchedByIgnition" SG_ 267 TSK_Standby_Anf_ESP 0;
BA_ "GenSigSendType" SG_ 267 TSK_Status 0;
BA_ "GenSigStartValue" SG_ 267 TSK_Status 1;
BA_ "GenSigSwitchedByIgnition" SG_ 267 TSK_Status 0;
BA_ "GenSigSendType" SG_ 267 TSK_v_Begrenzung_aktiv 0;
BA_ "GenSigSwitchedByIgnition" SG_ 267 TSK_v_Begrenzung_aktiv 0;
BA_ "GenSigSendType" SG_ 267 TSK_zul_Regelabw 0;
BA_ "GenSigSwitchedByIgnition" SG_ 267 TSK_zul_Regelabw 0;
BA_ "GenSigSendType" SG_ 267 TSK_Zwangszusch_ESP 0;
BA_ "GenSigSwitchedByIgnition" SG_ 267 TSK_Zwangszusch_ESP 0;
BA_REL_ "GenSigTimeoutTime" BU_SG_REL_ BCM SG_ 1178 FS_MMB_storage 1000;
BA_REL_ "GenSigTimeoutTime" BU_SG_REL_ BCM SG_ 1178 FS_MMB_tipp 1000;
BA_REL_ "GenSigTimeoutTime" BU_SG_REL_ BCM SG_ 1178 FS_MMB_tast 1000;
BA_REL_ "GenSigTimeoutTime" BU_SG_REL_ BCM SG_ 1178 FS_MMB_glob_stop 1000;
BA_REL_ "GenSigTimeoutTime" BU_SG_REL_ BCM SG_ 1171 MFG_01_CRC 2000;
BA_REL_ "GenSigTimeoutTime" BU_SG_REL_ BCM SG_ 1171 MFG_01_BZ 2000;
BA_REL_ "GenSigTimeoutTime" BU_SG_REL_ BCM SG_ 1171 MF_ZV_Lock 2000;
BA_REL_ "GenSigTimeoutTime" BU_SG_REL_ BCM SG_ 1171 MF_Motorweiterlauf 2000;
BA_REL_ "GenSigTimeoutTime" BU_SG_REL_ BCM SG_ 1171 MF_Variante 2000;
BA_REL_ "GenSigTimeoutTime" BU_SG_REL_ BCM SG_ 1171 MF_Fernbed_ein 2000;
BA_REL_ "GenSigTimeoutTime" BU_SG_REL_ BCM SG_ 1171 MF_Standlicht 2000;
BA_REL_ "GenSigTimeoutTime" BU_SG_REL_ BCM SG_ 1171 MF_Fahrlicht 2000;
BA_REL_ "GenSigTimeoutTime" BU_SG_REL_ BCM SG_ 1171 MF_interm_Fernlicht 2000;
BA_REL_ "GenSigTimeoutTime" BU_SG_REL_ BCM SG_ 1171 MF_Warnblinker 2000;
BA_REL_ "GenSigTimeoutTime" BU_SG_REL_ BCM SG_ 1171 MF_Fussraumbel 2000;
BA_REL_ "GenSigTimeoutTime" BU_SG_REL_ BCM SG_ 1171 MF_Innenraumbel 2000;
BA_REL_ "GenSigTimeoutTime" BU_SG_REL_ BCM SG_ 1171 MF_Innenraumbel_Unterdrueck 2000;
BA_REL_ "GenSigTimeoutTime" BU_SG_REL_ BCM SG_ 1171 MF_Blk_li 2000;
BA_REL_ "GenSigTimeoutTime" BU_SG_REL_ BCM SG_ 1171 MF_Blk_re 2000;
BA_REL_ "GenSigTimeoutTime" BU_SG_REL_ BCM SG_ 1171 MF_Lichthupe 2000;
BA_REL_ "GenSigTimeoutTime" BU_SG_REL_ BCM SG_ 1171 MF_Fernlicht 2000;
BA_REL_ "GenSigTimeoutTime" BU_SG_REL_ BCM SG_ 1171 MF_HFS_verriegeln 2000;
BA_REL_ "GenSigTimeoutTime" BU_SG_REL_ BCM SG_ 1171 MF_HFS_entriegeln 2000;
BA_REL_ "GenSigTimeoutTime" BU_SG_REL_ BCM SG_ 1171 MF_HBFS_verriegeln 2000;
BA_REL_ "GenSigTimeoutTime" BU_SG_REL_ BCM SG_ 1171 MF_HBFS_entriegeln 2000;
BA_REL_ "GenSigTimeoutTime" BU_SG_REL_ BCM SG_ 1171 MF_Tippwischen 2000;
BA_REL_ "GenSigTimeoutTime" BU_SG_REL_ BCM SG_ 1171 MF_Frontintervall 2000;
BA_REL_ "GenSigTimeoutTime" BU_SG_REL_ BCM SG_ 1171 MF_Wischerstufe_1 2000;
BA_REL_ "GenSigTimeoutTime" BU_SG_REL_ BCM SG_ 1171 MF_Wischerstufe_2 2000;
BA_REL_ "GenSigTimeoutTime" BU_SG_REL_ BCM SG_ 1171 MF_Frontwaschen 2000;
BA_REL_ "GenSigTimeoutTime" BU_SG_REL_ BCM SG_ 1171 MF_Heckintervall 2000;
BA_REL_ "GenSigTimeoutTime" BU_SG_REL_ BCM SG_ 1171 MF_Heckwaschen 2000;
BA_REL_ "GenSigTimeoutTime" BU_SG_REL_ BCM SG_ 1171 MF_Alarm_Blinkertakt 2000;
BA_REL_ "GenSigTimeoutTime" BU_SG_REL_ BCM SG_ 1171 MF_Alarm_Blinker 2000;
BA_REL_ "GenSigTimeoutTime" BU_SG_REL_ BCM SG_ 1171 MF_TFL_Abschaltung 2000;
BA_REL_ "GenSigTimeoutTime" BU_SG_REL_ BCM SG_ 1171 MF_interm_Takt 2000;
BA_REL_ "GenSigTimeoutTime" BU_SG_REL_ BCM SG_ 1171 MF_Tuerentriegelung_hinten 2000;
BA_REL_ "GenSigTimeoutTime" BU_SG_REL_ BCM SG_ 1171 MF_interm_Fahrlicht 2000;
BA_REL_ "GenSigTimeoutTime" BU_SG_REL_ BCM SG_ 1171 MF_Signalhorn 2000;
BA_REL_ "GenSigTimeoutTime" BU_SG_REL_ BCM SG_ 1171 MF_FT_verriegeln 2000;
BA_REL_ "GenSigTimeoutTime" BU_SG_REL_ BCM SG_ 1171 MF_FT_entriegeln 2000;
BA_REL_ "GenSigTimeoutTime" BU_SG_REL_ BCM SG_ 1171 MF_BT_verriegeln 2000;
BA_REL_ "GenSigTimeoutTime" BU_SG_REL_ BCM SG_ 1171 MF_BT_entriegeln 2000;
BA_REL_ "GenSigTimeoutTime" BU_SG_REL_ BCM SG_ 1164 MF_Lampenausfall 2000;
BA_REL_ "GenSigTimeoutTime" BU_SG_REL_ BCM SG_ 1164 MF_Blinker_L_Sta 2000;
BA_REL_ "GenSigTimeoutTime" BU_SG_REL_ BCM SG_ 1164 MF_Blinker_R_Sta 2000;
BA_REL_ "GenSigTimeoutTime" BU_SG_REL_ BCM SG_ 1164 MF_Heck_entriegeln 2000;
BA_REL_ "GenSigTimeoutTime" BU_SG_REL_ BCM SG_ 1164 MF_Heck_verriegeln 2000;
BA_REL_ "GenSigTimeoutTime" BU_SG_REL_ BCM SG_ 1164 MF_ZV_Unlock 2000;
BA_REL_ "GenSigTimeoutTime" BU_SG_REL_ BCM SG_ 1164 MF_Tuerverriegelung_hinten 2000;
BA_REL_ "GenSigTimeoutTime" BU_SG_REL_ BCM SG_ 2463978865 MIK_01_CRC 1000;
BA_REL_ "GenSigTimeoutTime" BU_SG_REL_ BCM SG_ 2463978865 MIK_01_BZ 1000;
BA_REL_ "GenSigTimeoutTime" BU_SG_REL_ BCM SG_ 2463978865 MIK_Fahrer_erkannt 1000;
BA_REL_ "GenSigTimeoutTime" BU_SG_REL_ BCM SG_ 263 MO_Anzeigedrehz 1000;
BA_REL_ "GenSigTimeoutTime" BU_SG_REL_ BCM SG_ 1600 MO_KL15_Abschaltempfehlung 5000;
BA_REL_ "GenSigTimeoutTime" BU_SG_REL_ BCM SG_ 958 Motor_14_CRC 1000;
BA_REL_ "GenSigTimeoutTime" BU_SG_REL_ BCM SG_ 958 Motor_14_BZ 1000;
BA_REL_ "GenSigTimeoutTime" BU_SG_REL_ BCM SG_ 958 MO_StartStopp_Status 1000;
BA_REL_ "GenSigTimeoutTime" BU_SG_REL_ BCM SG_ 958 MO_StartStopp_Wiederstart 1000;
BA_REL_ "GenSigTimeoutTime" BU_SG_REL_ BCM SG_ 958 MO_StartStopp_Motorstopp 1000;
BA_REL_ "GenSigTimeoutTime" BU_SG_REL_ BCM SG_ 958 MO_Kl_75 1000;
BA_REL_ "GenSigTimeoutTime" BU_SG_REL_ BCM SG_ 958 MO_Kl_50 1000;
BA_REL_ "GenSigTimeoutTime" BU_SG_REL_ BCM SG_ 958 MO_StartStopp_Fahrerwunsch 1000;
BA_REL_ "GenSigTimeoutTime" BU_SG_REL_ BCM SG_ 958 MO_HYB_Fahrbereitschaft 1000;
BA_REL_ "GenSigTimeoutTime" BU_SG_REL_ BCM SG_ 958 MO_Fahrer_bremst 1000;
BA_REL_ "GenSigTimeoutTime" BU_SG_REL_ BCM SG_ 958 MO_QBit_Fahrer_bremst 1000;
BA_REL_ "GenSigTimeoutTime" BU_SG_REL_ BCM SG_ 958 MO_BLS 1000;
BA_REL_ "GenSigTimeoutTime" BU_SG_REL_ BCM SG_ 958 MO_Kuppl_schalter 1000;
BA_REL_ "GenSigTimeoutTime" BU_SG_REL_ BCM SG_ 958 MO_Motor_laeuft 1000;
BA_REL_ "GenSigTimeoutTime" BU_SG_REL_ BCM SG_ 958 MO_QBit_KL_75 1000;
BA_REL_ "GenSigTimeoutTime" BU_SG_REL_ BCM SG_ 958 MO_Remotestart_Betrieb 1000;
BA_REL_ "GenSigTimeoutTime" BU_SG_REL_ BCM SG_ 958 MO_StartVorauss_erfuellt 1000;
BA_REL_ "GenSigTimeoutTime" BU_SG_REL_ BCM SG_ 1648 MO_Bremslicht_Reku 5000;
BA_REL_ "GenSigTimeoutTime" BU_SG_REL_ BCM SG_ 1648 MO1_Sperr_Info_WFS 5000;
BA_REL_ "GenSigTimeoutTime" BU_SG_REL_ BCM SG_ 1648 MO_Fahrzeugtyp 5000;
BA_REL_ "GenSigTimeoutTime" BU_SG_REL_ BCM SG_ 1648 MO_Hybrid_StartStopp_LED 5000;
BA_REL_ "GenSigTimeoutTime" BU_SG_REL_ BCM SG_ 967 MO_Text_Motorstart 1000;
BA_REL_ "GenSigTimeoutTime" BU_SG_REL_ BCM SG_ 967 MO_E_Texte 1000;
BA_REL_ "GenSigTimeoutTime" BU_SG_REL_ BCM SG_ 267 Motor_51_CRC 1000;
BA_REL_ "GenSigTimeoutTime" BU_SG_REL_ BCM SG_ 267 Motor_51_BZ 1000;
BA_REL_ "GenSigTimeoutTime" BU_SG_REL_ BCM SG_ 267 MO_Fahrpedalrohwert_01 1000;
BA_REL_ "GenSigTimeoutTime" BU_SG_REL_ BCM SG_ 267 MO_QBit_Fahrpedalwerte_01 1000;
BA_REL_ "GenSigTimeoutTime" BU_SG_REL_ Gateway_Max SG_ 1180 MTBT_Pos1 1000;
BA_REL_ "GenSigTimeoutTime" BU_SG_REL_ Gateway_Max SG_ 1170 MTFT_On_Off 1000;
BA_REL_ "GenSigTimeoutTime" BU_SG_REL_ TSGGen3_BFS SG_ 1178 FS_Gurtbringer_Sperre 1000;
BA_REL_ "GenSigTimeoutTime" BU_SG_REL_ TSGGen3_BFS SG_ 1178 FS_Sitzfahrt_aktiv 1000;
BA_REL_ "GenSigTimeoutTime" BU_SG_REL_ TSGGen3_BFS SG_ 1171 MF_Variante 2000;
BA_REL_ "GenSigTimeoutTime" BU_SG_REL_ TSGGen3_BFS SG_ 1171 MF_Fernbed_ein 2000;
BA_REL_ "GenSigTimeoutTime" BU_SG_REL_ TSGGen3_BFS SG_ 1171 MF_Innenraumbel 2000;
BA_REL_ "GenSigTimeoutTime" BU_SG_REL_ TSGGen3_BFS SG_ 1171 MF_Innenraumbel_Unterdrueck 2000;
BA_REL_ "GenSigTimeoutTime" BU_SG_REL_ TSGGen3_BFS SG_ 1171 MF_FH_BT_hoch 2000;
BA_REL_ "GenSigTimeoutTime" BU_SG_REL_ TSGGen3_BFS SG_ 1171 MF_FH_BT_tief 2000;
BA_REL_ "GenSigTimeoutTime" BU_SG_REL_ TSGGen3_BFS SG_ 2463978883 MF_Vorfeldbel_Spiegel 1000;
BA_REL_ "GenSigTimeoutTime" BU_SG_REL_ TSGGen3_BFS SG_ 958 MO_StartStopp_Wiederstart 1000;
BA_REL_ "GenSigTimeoutTime" BU_SG_REL_ TSGGen3_BFS SG_ 958 MO_Kl_75 1000;
BA_REL_ "GenSigTimeoutTime" BU_SG_REL_ TSGGen3_BFS SG_ 958 MO_Kl_50 1000;
BA_REL_ "GenSigTimeoutTime" BU_SG_REL_ TSGGen3_BFS SG_ 958 MO_Motor_laeuft 1000;
BA_REL_ "GenSigTimeoutTime" BU_SG_REL_ TSGGen3_BFS SG_ 958 MO_QBit_KL_75 1000;
BA_REL_ "GenSigTimeoutTime" BU_SG_REL_ TSGGen3_FS SG_ 1178 FS_Gurtbringer_Sperre 1000;
BA_REL_ "GenSigTimeoutTime" BU_SG_REL_ TSGGen3_FS SG_ 1178 FS_Sitzfahrt_aktiv 1000;
BA_REL_ "GenSigTimeoutTime" BU_SG_REL_ TSGGen3_FS SG_ 1178 FS_MMB_storage 1000;
BA_REL_ "GenSigTimeoutTime" BU_SG_REL_ TSGGen3_FS SG_ 1178 FS_MMB_tipp 1000;
BA_REL_ "GenSigTimeoutTime" BU_SG_REL_ TSGGen3_FS SG_ 1178 FS_MMB_tast 1000;
BA_REL_ "GenSigTimeoutTime" BU_SG_REL_ TSGGen3_FS SG_ 1178 FS_MMB_store_LED_on 1000;
BA_REL_ "GenSigTimeoutTime" BU_SG_REL_ TSGGen3_FS SG_ 1178 FS_MMB_store 1000;
BA_REL_ "GenSigTimeoutTime" BU_SG_REL_ TSGGen3_FS SG_ 1178 FS_MMB_glob_stop 1000;
BA_REL_ "GenSigTimeoutTime" BU_SG_REL_ TSGGen3_FS SG_ 1171 MF_Variante 2000;
BA_REL_ "GenSigTimeoutTime" BU_SG_REL_ TSGGen3_FS SG_ 1171 MF_Fernbed_ein 2000;
BA_REL_ "GenSigTimeoutTime" BU_SG_REL_ TSGGen3_FS SG_ 1171 MF_Fussraumbel 2000;
BA_REL_ "GenSigTimeoutTime" BU_SG_REL_ TSGGen3_FS SG_ 1171 MF_Innenraumbel 2000;
BA_REL_ "GenSigTimeoutTime" BU_SG_REL_ TSGGen3_FS SG_ 1171 MF_Innenraumbel_Unterdrueck 2000;
BA_REL_ "GenSigTimeoutTime" BU_SG_REL_ TSGGen3_FS SG_ 1171 MF_FH_FT_hoch 2000;
BA_REL_ "GenSigTimeoutTime" BU_SG_REL_ TSGGen3_FS SG_ 1171 MF_FH_FT_tief 2000;
BA_REL_ "GenSigTimeoutTime" BU_SG_REL_ TSGGen3_FS SG_ 2463978883 MF_Vorfeldbel_Spiegel 1000;
BA_REL_ "GenSigTimeoutTime" BU_SG_REL_ TSGGen3_FS SG_ 958 MO_StartStopp_Wiederstart 1000;
BA_REL_ "GenSigTimeoutTime" BU_SG_REL_ TSGGen3_FS SG_ 958 MO_Kl_75 1000;
BA_REL_ "GenSigTimeoutTime" BU_SG_REL_ TSGGen3_FS SG_ 958 MO_Kl_50 1000;
BA_REL_ "GenSigTimeoutTime" BU_SG_REL_ TSGGen3_FS SG_ 958 MO_Motor_laeuft 1000;
BA_REL_ "GenSigTimeoutTime" BU_SG_REL_ TSGGen3_FS SG_ 958 MO_QBit_KL_75 1000;
BA_REL_ "GenSigTimeoutTime" BU_SG_REL_ TSGGen3_HBFS SG_ 1178 FS_Gurtbringer_Sperre 1000;
BA_REL_ "GenSigTimeoutTime" BU_SG_REL_ TSGGen3_HBFS SG_ 1178 FS_Sitzfahrt_aktiv 1000;
BA_REL_ "GenSigTimeoutTime" BU_SG_REL_ TSGGen3_HBFS SG_ 1171 MF_Variante 2000;
BA_REL_ "GenSigTimeoutTime" BU_SG_REL_ TSGGen3_HBFS SG_ 1171 MF_Fernbed_ein 2000;
BA_REL_ "GenSigTimeoutTime" BU_SG_REL_ TSGGen3_HBFS SG_ 1171 MF_Innenraumbel 2000;
BA_REL_ "GenSigTimeoutTime" BU_SG_REL_ TSGGen3_HBFS SG_ 1171 MF_Innenraumbel_Unterdrueck 2000;
BA_REL_ "GenSigTimeoutTime" BU_SG_REL_ TSGGen3_HBFS SG_ 958 MO_StartStopp_Wiederstart 1000;
BA_REL_ "GenSigTimeoutTime" BU_SG_REL_ TSGGen3_HBFS SG_ 958 MO_Kl_75 1000;
BA_REL_ "GenSigTimeoutTime" BU_SG_REL_ TSGGen3_HBFS SG_ 958 MO_Kl_50 1000;
BA_REL_ "GenSigTimeoutTime" BU_SG_REL_ TSGGen3_HBFS SG_ 958 MO_Motor_laeuft 1000;
BA_REL_ "GenSigTimeoutTime" BU_SG_REL_ TSGGen3_HBFS SG_ 958 MO_QBit_KL_75 1000;
BA_REL_ "GenSigTimeoutTime" BU_SG_REL_ TSGGen3_HFS SG_ 1178 FS_Gurtbringer_Sperre 1000;
BA_REL_ "GenSigTimeoutTime" BU_SG_REL_ TSGGen3_HFS SG_ 1178 FS_Sitzfahrt_aktiv 1000;
BA_REL_ "GenSigTimeoutTime" BU_SG_REL_ TSGGen3_HFS SG_ 1171 MF_Variante 2000;
BA_REL_ "GenSigTimeoutTime" BU_SG_REL_ TSGGen3_HFS SG_ 1171 MF_Fernbed_ein 2000;
BA_REL_ "GenSigTimeoutTime" BU_SG_REL_ TSGGen3_HFS SG_ 1171 MF_Innenraumbel 2000;
BA_REL_ "GenSigTimeoutTime" BU_SG_REL_ TSGGen3_HFS SG_ 1171 MF_Innenraumbel_Unterdrueck 2000;
BA_REL_ "GenSigTimeoutTime" BU_SG_REL_ TSGGen3_HFS SG_ 958 MO_StartStopp_Wiederstart 1000;
BA_REL_ "GenSigTimeoutTime" BU_SG_REL_ TSGGen3_HFS SG_ 958 MO_Kl_75 1000;
BA_REL_ "GenSigTimeoutTime" BU_SG_REL_ TSGGen3_HFS SG_ 958 MO_Kl_50 1000;
BA_REL_ "GenSigTimeoutTime" BU_SG_REL_ TSGGen3_HFS SG_ 958 MO_Motor_laeuft 1000;
BA_REL_ "GenSigTimeoutTime" BU_SG_REL_ TSGGen3_HFS SG_ 958 MO_QBit_KL_75 1000;
VAL_ 1178 FS_Fond_Bed_enable 0 "disable" 1 "enable" ;
VAL_ 1178 FS_Lehne_nicht_verriegelt 0 "keine Anzeige" 1 "Lehne_nicht_verriegelt" ;
VAL_ 1178 FS_Spezialposition_anfahren 0 "Fkt_inaktiv" 1 "Fkt_aktiv" ;
VAL_ 1178 FS_Gurtbringer_Sperre 0 "Gurtzubringer_freigegeben" 1 "Gurtzubringer_gesperrt" ;
VAL_ 1178 FS_BFS_Sitzsym_Anfahrt 0 "keine Sitzsymetrie Anfahrt BFS" 1 "Sitzsymetrie Anfahrt BFS" ;
VAL_ 1178 FS_Sitzfahrt_aktiv 0 "Sitz_nicht_in_Bewegung" 1 "Sitz_in_Bewegung" ;
VAL_ 1178 FS_SLV_aktiv 0 "nicht_aktiv" 1 "Sitzlaengsverstellung aktiv" ;
VAL_ 1178 FS_SHV_aktiv 0 "nicht_aktiv" 1 "Sitzhoehenverstellung aktiv" ;
VAL_ 1178 FS_LNV_aktiv 0 "nicht_aktiv" 1 "Lehnenneigungverstellung aktiv" ;
VAL_ 1178 FS_SNV_aktiv 0 "nicht_aktiv" 1 "Sitzneigungsverstellung_aktiv" ;
VAL_ 1178 FS_KSV_aktiv 0 "nicht_aktiv" 1 "Kopfstuetzenverstellung aktiv" ;
VAL_ 1178 FS_LKV_aktiv 0 "nicht_aktiv" 1 "Lehnenkopfverstellung aktiv" ;
VAL_ 1178 FS_STV_aktiv 0 "nicht_aktiv" 1 "Sitztiefeverstellung aktiv" ;
VAL_ 1178 FS_LHV_aktiv 0 "nicht_aktiv" 1 "Lordose Höhe Verstellung aktiv" ;
VAL_ 1178 FS_LWV_aktiv 0 "nicht_aktiv" 1 "Lordose W Verstellung aktiv" ;
VAL_ 1178 FS_GHV_aktiv 0 "nicht_aktiv" 1 "Gurthoehenverstellung aktiv" ;
VAL_ 1178 FS_BFS_KSS_Anfahrt 0 "keine Anfahrt KSS BFS" 1 "Anfahrt KSS BFS" ;
VAL_ 1178 FS_MMB_lokal_Stop 0 "kein_Abbruch" 1 "lokaler_Abbruch" ;
VAL_ 1178 FS_MMB_storage 0 "keine_Zuweisung" 1 "P1_FP1_Pos_Zuweisung" 2 "P2_FP2_Pos_Zuweisung" 3 "P3_FP3_Pos_Zuweisung" 4 "P4_FP4_Pos_Zuweisung" 5 "FS1_bzw_Benutzerkonto_1" 6 "FS2_bzw_Benutzerkonto_2" 7 "FS3_bzw_Benutzerkonto_3" 8 "FS4_bzw_Benutzerkonto_4" 9 "FS5_bzw_Benutzerkonto_5" 10 "FS6_bzw_Benutzerkonto_6" 11 "FS7_bzw_Benutzerkonto_7" ;
VAL_ 1178 FS_MMB_tipp 0 "kein_Tippbetrieb" 1 "Tippbetrieb__automatisches_Funks" ;
VAL_ 1178 FS_MMB_tast 0 "kein_Tastbetrieb" 1 "Tastbetrieb__Fingerprintautomati" ;
VAL_ 1178 FS_MMB_store_LED_on 0 "LED_aus" 1 "LED_ein" ;
VAL_ 1178 FS_MMB_storage_beep 0 "beep aus" 1 "beep ein" ;
VAL_ 1178 FS_MMB_store 0 "nicht_speichern__kein_keyless_ve" 1 "abspeichern__keyless_verbaut" ;
VAL_ 1178 FS_MMB_glob_stop 0 "kein_globaler_Abbrucht" 1 "globaler_Abbruch" ;
VAL_ 1178 FS_EE_Fond_FS_enable 0 "EE Fond links deaktiv" 1 "EE Fond links aktiv (default) vom MMI" ;
VAL_ 1178 FS_EE_Fond_BFS_enable 0 "EE Fond rechts deaktiv" 1 "EE Fond rechts aktiv (default) vom MMI" ;
VAL_ 1178 FS_EE_BFS_enable 0 "keine_EE_Freigabe" 1 "EE_Freigabe" ;
VAL_ 1180 MTBT_Pos1 0 "Taste_nicht_gedrueckt" 1 "Postionstaste_1_BT_gedrueckt" ;
VAL_ 1180 MTBT_Pos2 0 "Taste_nicht_gedrueckt" 1 "Postionstaste_2_BT_gedrueckt" ;
VAL_ 1180 MTBT_Pos3 0 "Taste_nicht_gedrueckt" 1 "Postionstaste_3_BT_gedrueckt" ;
VAL_ 1180 MTBT_Pos4 0 "Taste_nicht_gedrueckt" 1 "Postionstaste_4_BT_gedrueckt" ;
VAL_ 1180 MTBT_On_Off 0 "Taste_nicht_gedrueckt" 1 "OnOff_Taste_BT_gedrueckt" ;
VAL_ 1180 MTBT_M_Taste 0 "Taste_nicht_gedrueckt" 1 "MTaste_BT_gedrueckt" ;
VAL_ 1170 MTFT_Pos1_EE 0 "Taste_nicht_gedrueckt" 1 "Postionstaste_1_FT_gedrueckt" ;
VAL_ 1170 MTFT_Pos2 0 "Taste_nicht_gedrueckt" 1 "Postionstaste_2_FT_gedrueckt" ;
VAL_ 1170 MTFT_Pos3 0 "Taste_nicht_gedrueckt" 1 "Postionstaste_3_FT_gedrueckt" ;
VAL_ 1170 MTFT_Pos4 0 "Taste_nicht_gedrueckt" 1 "Postionstaste_4_FT_gedrueckt" ;
VAL_ 1170 MTFT_On_Off 0 "Taste_nicht_gedrueckt" 1 "On-Off Taste FT gedrückt" ;
VAL_ 1170 MTFT_Verst_akt 0 "Verstellung_nicht_aktiv" 1 "Verstellung_aktiv" ;
VAL_ 1170 MTFT_M_Taste 0 "Taste_nicht_gedrueckt" 1 "MTaste_FT_gedrueckt" ;
VAL_ 1173 BFS_Sitzhoehe_hoch 0 "aus" 1 "hoch" ;
VAL_ 1173 BFS_Sitzhoehe_runter 0 "aus" 1 "runter" ;
VAL_ 1173 MTHBF_ein 0 "aus" 1 "ein" ;
VAL_ 1173 BFS_Laengsverst_vor 0 "Taste_nicht_gedrueckt" 1 "Laengsverstellung_vor" ;
VAL_ 1173 BFS_Laengsverst_zurueck 0 "Taste_nicht_gedrueckt" 1 "Längsverstellung zurück (Wird bei Rechtslenker vom TSG HL gesendet)" ;
VAL_ 1173 BFS_Lehnenneigung_vor 0 "Taste_nicht_gedrueckt" 1 "Lehnenneigung vor (Wird bei Rechtslenker vom TSG HL gesendet)" ;
VAL_ 1173 BFS_Lehnenneigung_zurueck 0 "Taste_nicht_gedrueckt" 1 "Lehnenneigung_zurueck" ;
VAL_ 1173 BFS_Lehnenkopf_vor 0 "Taste_nicht_gedrueckt" 1 "Lehnenkopf_vor" ;
VAL_ 1173 BFS_Lehnenkopf_zurueck 0 "Taste_nicht_gedrueckt" 1 "Lehnenkopf_zurueck" ;
VAL_ 1173 BFS_Kopfstuetzen_hoch 0 "Taste_nicht_gedrueckt" 1 "Kopfstuetzen_hoch" ;
VAL_ 1173 BFS_Kopfstuetzen_runter 0 "Taste_nicht_gedrueckt" 1 "Kopfstuetzen_runter" ;
VAL_ 1171 MF_ZV_Lock 0 "Locktaster_nicht_betaetigt" 1 "Locktaster_betaetigt" ;
VAL_ 1171 MF_Motorweiterlauf 0 "inaktiv" 1 "aktiv" ;
VAL_ 1171 MF_Abzugssperre 0 "inaktiv" 1 "aktiv" ;
VAL_ 1171 MF_Anlassersperre 0 "inaktiv" 1 "aktiv" ;
VAL_ 1171 MF_Variante 0 "keine_Sonderfunktion" 1 "Sondersignalfahrzeug" 2 "Taxi" 3 "Fahrhilfe" 4 "Fahrschule_Extra" 5 "SSF" 6 "DBMC" 7 "Arbeitsmaschine" ;
VAL_ 1171 MF_Schluessel_scan 0 "inaktiv" 1 "aktiv" ;
VAL_ 1171 MF_Laderelais 0 "Relais_offen" 1 "Relais_geschlossen" ;
VAL_ 1171 MF_StartStopp_Info 0 "Motorlauf_nicht_notwendig_(Stoppfreigabe)" 1 "Motoranlauf_nicht_zwingend_notwendig_(Stoppverbot,keine_Startanforderung)" 2 "Motoranlauf_zwingend_notwendig_(Startanforderung)" 3 "Systemfehler" ;
VAL_ 1171 MF_Fernbed_ein 0 "inaktiv" 1 "aktiv" ;
VAL_ 1171 MF_Standlicht 0 "inaktiv" 1 "aktiv" ;
VAL_ 1171 MF_Fahrlicht 0 "inaktiv" 1 "aktiv" ;
VAL_ 1171 MF_interm_Fernlicht 0 "inaktiv" 1 "aktiv" ;
VAL_ 1171 MF_Warnblinker 0 "inaktiv" 1 "aktiv" ;
VAL_ 1171 MF_Fussraumbel 0 "inaktiv" 1 "aktiv" ;
VAL_ 1171 MF_Innenraumbel 0 "inaktiv" 1 "aktiv" ;
VAL_ 1171 MF_Innenraumbel_Unterdrueck 0 "inaktiv" 1 "aktiv" ;
VAL_ 1171 MF_Notstart 0 "kein_Notstart" 1 "Notstart" ;
VAL_ 1171 MF_Blk_li 0 "inaktiv" 1 "aktiv" ;
VAL_ 1171 MF_Blk_re 0 "inaktiv" 1 "aktiv" ;
VAL_ 1171 MF_Lichthupe 0 "inaktiv" 1 "aktiv" ;
VAL_ 1171 MF_Fernlicht 0 "inaktiv" 1 "aktiv" ;
VAL_ 1171 MF_HFS_verriegeln 0 "nicht_verriegeln" 1 "verriegeln" ;
VAL_ 1171 MF_HFS_entriegeln 0 "nicht_entriegeln" 1 "entriegeln" ;
VAL_ 1171 MF_HBFS_verriegeln 0 "nicht_verriegeln" 1 "verriegeln" ;
VAL_ 1171 MF_HBFS_entriegeln 0 "nicht_entriegeln" 1 "entriegeln" ;
VAL_ 1171 MF_Tippwischen 0 "inaktiv" 1 "aktiv" ;
VAL_ 1171 MF_Frontintervall 0 "inaktiv" 1 "aktiv" ;
VAL_ 1171 MF_Wischerstufe_1 0 "inaktiv" 1 "aktiv" ;
VAL_ 1171 MF_Wischerstufe_2 0 "inaktiv" 1 "aktiv" ;
VAL_ 1171 MF_Frontwaschen 0 "inaktiv" 1 "aktiv" ;
VAL_ 1171 MF_nachtr_Stopp_Anf 0 "nicht_angefordert" 1 "angefordert" ;
VAL_ 1171 MF_Heckintervall 0 "inaktiv" 1 "aktiv" ;
VAL_ 1171 MF_Heckwaschen 0 "inaktiv" 1 "aktiv" ;
VAL_ 1171 MF_Summer 0 "inaktiv" 1 "aktiv" ;
VAL_ 1171 MF_Alarm_Blinkertakt 0 "inaktiv" 1 "aktiv" ;
VAL_ 1171 MF_Alarm_Blinker 0 "inaktiv" 1 "aktiv" ;
VAL_ 1171 MF_TFL_Abschaltung 0 "inaktiv" 1 "aktiv" ;
VAL_ 1171 MF_interm_Takt 0 "inaktiv" 1 "aktiv" ;
VAL_ 1171 MF_Tuerentriegelung_hinten 0 "inaktiv" 1 "aktiv" ;
VAL_ 1171 MF_interm_Fahrlicht 0 "inaktiv" 1 "aktiv" ;
VAL_ 1171 MF_Signalhorn 0 "inaktiv" 1 "aktiv" ;
VAL_ 1171 MF_FH_FT_hoch 0 "inaktiv" 1 "aktiv" ;
VAL_ 1171 MF_FH_FT_tief 0 "inaktiv" 1 "aktiv" ;
VAL_ 1171 MF_FH_BT_hoch 0 "inaktiv" 1 "aktiv" ;
VAL_ 1171 MF_FH_BT_tief 0 "inaktiv" 1 "aktiv" ;
VAL_ 1171 MF_FT_verriegeln 0 "nicht_verriegeln" 1 "verriegeln" ;
VAL_ 1171 MF_FT_entriegeln 0 "nicht_entriegeln" 1 "entriegeln" ;
VAL_ 1171 MF_BT_verriegeln 0 "nicht_verriegeln" 1 "verriegeln" ;
VAL_ 1171 MF_BT_entriegeln 0 "nicht_entriegeln" 1 "entriegeln" ;
VAL_ 1164 MFG_Infotainment_Autark 0 "Autarkie_no" 1 "Autarkie_yes" ;
VAL_ 1164 MFG_Klappe_Status 0 "Init" 1 "Front" 2 "Heck" 3 "Front_u_Heck" 4 "misch_Front_u_Heck" ;
VAL_ 1164 MFG_LSH_DBetr_Ein 0 "Dauerbetrieb_nicht_gefordert" 1 "Dauerbetrieb_gefordert" ;
VAL_ 1164 MFG_LSH_Betriebsdauer 127 "Dauerbetrieb" ;
VAL_ 1164 MFG_LSH_DBetr_Bestaet 0 "kein_Dauerbetrieb" 1 "Dauerbetrieb_bestaetigt" ;
VAL_ 1164 MFG_LSH_Ansteuerung 0 "Aus" 1 "Ein" 2 "Kombi_Betrieb" 3 "Heizleistung_reduziert" ;
VAL_ 1164 MF_Radiomute 0 "Kein_Mute" 1 "Mute" ;
VAL_ 1164 MF_Relais_2_Batterie 0 "nicht_betaetigt" 1 "betaetigt" ;
VAL_ 1164 MF_Batteriediagnose 0 "keine_Anzeige" 1 "Anzeige_Batterieservice" 2 "Anzeige_aberkannte_Batterie" 3 "Anzeige_schwache_Batterie" 4 "Anzeige_Batterie_OK" 5 "Anzeige_Batterie_Laden" 6 "Anzeige_Batterie_Pruefen" 7 "Fehler" ;
VAL_ 1164 MFG_AppConnect_Anf 0 "AppConnect_keine_Anforderung" 1 "AppConnect_Anforderung" 2 "AppConnect_Darstellungsrueckgabe" ;
VAL_ 1164 MF_Lampenausfall 0 "iO" 1 "defekt" ;
VAL_ 1164 MF_Blinker_L_Sta 0 "inaktiv" 1 "aktiv" ;
VAL_ 1164 MF_Blinker_R_Sta 0 "inaktiv" 1 "aktiv" ;
VAL_ 1164 MF_interm_Nebelscheinwerfer 0 "inaktiv" 1 "aktiv" ;
VAL_ 1164 MF_Generatordiagnose 0 "keine_Warnung" 1 "Warnung_Stufe_1" 2 "Warnung_Stufe_2" 3 "Nicht_verbaut" ;
VAL_ 1164 MF_Heck_entriegeln 0 "nicht_entriegeln" 1 "entriegeln" ;
VAL_ 1164 MF_Heck_verriegeln 0 "nicht_verriegeln" 1 "verriegeln" ;
VAL_ 1164 MF_2BatSOCzugering 0 "inaktiv" 1 "aktiv" ;
VAL_ 1164 MF_Fahrerhinweis 0 "keine_Anzeige" 1 "Warnung_Verrollsicherheit" 2 "Warnung_Fahrzeug_im_Freien" 3 "Warnung_Verlassen_Verriegeln" 4 "reserved" 5 "reserved" 6 "reserved" 7 "reserved" ;
VAL_ 1164 MF_ZV_Unlock 0 "nicht_entriegeln" 1 "entriegeln" ;
VAL_ 1164 MF_Tuerverriegelung_hinten 0 "inaktiv" 1 "aktiv" ;
VAL_ 1164 MF_2BattAb 0 "inaktiv" 1 "aktiv" ;
VAL_ 1164 MF_2BattHlkAnf 0 "inaktiv" 1 "aktiv" ;
VAL_ 1164 MF_2BattLadWarn 0 "inaktiv" 1 "aktiv" ;
VAL_ 1164 MF_2BattLlaAnf 0 "inaktiv" 1 "aktiv" ;
VAL_ 1164 MF_2BattSpannungsAnf 0 "keine_Anforderung" 1 "Anforderung_Stufe1" 2 "Anforderung_Stufe2" 3 "Anforderung_Stufe3" ;
VAL_ 1164 MF_NotStartAktiv 0 "inaktiv" 1 "aktiv" ;
VAL_ 1164 MF_ExterneLadungWarn 0 "inaktiv" 1 "aktiv" ;
VAL_ 1164 MF_LSH_Zielzeit 14 "Init" 15 "Fehler" ;
VAL_ 1164 MF_LSH_Abschaltstufe 0 "Init" 1 "Stufe1" 2 "Stufe2" 3 "Stufe3" 4 "Transportmodus" 7 "Ruhestrommessmodus" ;
VAL_ 1164 MF_LSH_Einschaltverbot 0 "Init_volleVerfuegbarkeit" 1 "Standheizung_bzw_lueftung_nicht_aktivierbar" ;
VAL_ 2463978883 MF_Fahrerhinweis_2 0 "keine_Anzeige" 1 "Dach_zu_oft_bewegt" 2 "Aufstellvorbedingungen" 3 "Absenkvorbedingungen" 4 "Fehler_Aufstelldach_Werkstatt" 5 "Aufstelldach_offen" 6 "Aufstelldach_klemmt" 7 "Fehler_Aufstelldach_manuell" 8 "Aufstelldach_Endposition" 9 "Waehrend_Fahrt_nicht_moeglich" 10 "Zur_Zeit_nicht_moeglich" 11 "Batterie_schwach_Motorlauf" 12 "Ladestecker_ist_gesteckt" ;
VAL_ 2463978883 MF_U2Batt 251 "U_kleiner_min" 252 "U_groesser_max" 255 "init" ;
VAL_ 2463978883 MF_UBattVorgabe 63 "init" ;
VAL_ 2463978883 MF_I_U_VorgabeZwang 0 "Wunschvorgabe" 1 "Zwangsvorgabe" ;
VAL_ 2463978883 MF_Vorfeldbel_Spiegel 0 "Serienvorfeldbeleuchtung" 1 "Vorfeldbeleuchtung_Spiegel_aktiv" ;
VAL_ 2463978883 MF_DCDC_Istmodus 0 "Standby" 2 "Strom_ZusBn_ErstBn" 3 "Strom_ErstBn_ZusBn" 4 "Startunterstuetzung_ZusBn" 5 "Fehler" 7 "Init" 14 "Bypass" ;
VAL_ 1471 MFL_Tastencode_1 0 "Key_Released__No_Key" 1 "Context_Menu" 2 "Menu_Up__Next_Screen" 3 "Menu_Down__Previous_Screen" 4 "Up" 5 "Down" 6 "Up__Down_ThumbWheel" 7 "OK__ThumbWheel_Button" 8 "Cancel__Escape" 9 "Main_Menu" 10 "Side_Menu_left" 11 "Side_Menu_right" 12 "FAS_Menu" 13 "Left__Right_ThumbWheel" 14 "FAS_Menu_ThumbWheel" 16 "Volume_Up" 17 "Volume_Down" 18 "Volume_Up__Down_ThumbWheel" 19 "Volume_ThumbWheel_Button" 20 "Audio_Source" 21 "Arrow_A_Up__Right" 22 "Arrow_A_Down__Left" 23 "Arrow_B_Up__Right" 24 "Arrow_B_Down__Left" 25 "PTT__PushToTalk" 26 "PTT_Cancel" 27 "Route_Info" 28 "Hook" 29 "Hang_Up" 30 "Off_Hook" 31 "Light_On__Off" 32 "Mute" 33 "Joker1" 34 "Joker2" 35 "View" 36 "Arrow_A_Up__Down_ThumbWheel" 37 "Lenkradheizung" 38 "Rekuperation" 39 "Tube_Toggle" 40 "DRS_Drag_Reduction_System" 41 "Stopwatch_Start_Stop" 42 "Stopwatch_Nextlap" 100 "MAP" 101 "MAP_Boost" 102 "Turn_signal_left" 103 "Turn_signal_right" 104 "Turn_signal_off" 105 "Flashlight" 106 "Highbeam" 107 "Washer_button" 108 "Wiper_button_left" 109 "Wiper_button_right" 110 "Wiper_button_cancel" 111 "Exhaust_Sound" 112 "Drive_Select_button" 113 "Sport_button" 114 "ESP_Drift_Selection_ThumbWheel" 115 "PTT_special_vehicle" 116 "TravelAssist" 117 "Launch_Control" 118 "Drift_Mode_Button_Increase" 119 "Drift_Mode_Button_Decrease" 120 "Drift_Mode_Button_Select" 121 "Drive_Mode_Button_Increase" 122 "Drive_Mode_Button_Decrease" 123 "Drive_Mode_Button_Select" 124 "E_Boost_Button_Increase" 125 "E_Boost_Button_Decrease" 126 "E_Boost_Button_Select" 127 "PerformanceHybridButton_Increase" 128 "PerformanceHybridButton_Decrease" 129 "EV_Mode_Button" 130 "HUD_Button" 131 "PASM_Wheel" 132 "PASM_Button" 133 "PTV_Wheel" 134 "PTV_Button" 135 "TC_ESC_Wheel" 136 "TC_ESC_Button" 240 "Startup_Reset" 241 "Initialization" ;
VAL_ 1471 MFL_Tastencode_2 0 "Key_Released__No_Key" 1 "Context_Menu" 2 "Menu_Up__Next_Screen" 3 "Menu_Down__Previous_Screen" 4 "Up" 5 "Down" 6 "Up__Down_ThumbWheel" 7 "OK__ThumbWheel_Button" 8 "Cancel__Escape" 9 "Main_Menu" 10 "Side_Menu_left" 11 "Side_Menu_right" 12 "FAS_Menu" 13 "Left__Right_ThumbWheel" 14 "FAS_Menu_ThumbWheel" 16 "Volume_Up" 17 "Volume_Down" 18 "Volume_Up__Down_ThumbWheel" 19 "Volume_ThumbWheel_Button" 20 "Audio_Source" 21 "Arrow_A_Up__Right" 22 "Arrow_A_Down__Left" 23 "Arrow_B_Up__Right" 24 "Arrow_B_Down__Left" 25 "PTT__PushToTalk" 26 "PTT_Cancel" 27 "Route_Info" 28 "Hook" 29 "Hang_Up" 30 "Off_Hook" 31 "Light_On__Off" 32 "Mute" 33 "Joker1" 34 "Joker2" 35 "View" 36 "Arrow_A_Up_Right_Down_Left_ThumbWheel" 37 "Lenkradheizung" 38 "Rekuperation" 39 "Tube_Toggle" 40 "DRS_Drag_Reduction_System" 41 "Stopwatch_Start_Stop" 42 "Stopwatch_Nextlap" 100 "MAP" 101 "MAP_Boost" 102 "Turn_signal_left" 103 "Turn_signal_right" 104 "Turn_signal_off" 105 "Flashlight" 106 "Highbeam" 107 "Washer_button" 108 "Wiper_button_left" 109 "Wiper_button_right" 110 "Wiper_button_cancel" 111 "Exhaust_Sound" 112 "Drive_Select_button" 113 "Sport_button" 114 "ESP_Drift_Selection_ThumbWheel" 115 "PTT_special_vehicle" 116 "TravelAssist" 117 "Launch_Control" 118 "Drift_Mode_Button_Increase" 119 "Drift_Mode_Button_Decrease" 120 "Drift_Mode_Button_Select" 121 "Drive_Mode_Button_Increase" 122 "Drive_Mode_Button_Decrease" 123 "Drive_Mode_Button_Select" 124 "E_Boost_Button_Increase" 125 "E_Boost_Button_Decrease" 126 "E_Boost_Button_Select" 127 "PerformanceHybridButton_Increase" 128 "PerformanceHybridButton_Decrease" 129 "EV_Mode_Button" 130 "HUD_Button" 131 "PASM_Wheel" 132 "PASM_Button" 133 "PTV_Wheel" 134 "PTV_Button" 135 "TC_ESC_Wheel" 136 "TC_ESC_Button" 240 "Startup_Reset" 241 "Initialization" ;
VAL_ 1471 MFL_Eventcode_1 0 "W_no_event____T_no_event" 1 "W_1_Tick_up__T_pressed_normal" 2 "W_2_Ticks_up__T_touched" 3 "W_3_Ticks_up__T_double_click_nor" 4 "W_4_Ticks_up__T_long_press_nor_1" 5 "W_5_Ticks_up__T_long_press_nor_2" 6 "W_6_Ticks_up__T_long_press_nor_3" 7 "W_7_Ticks_up" 9 "W_7_Ticks_dn__T_pressed_strong" 10 "W_6_Ticks_dn" 11 "W_5_Ticks_dn__T_double_click_str" 12 "W_4_Ticks_dn__T_long_press_str_1" 13 "W_3_Ticks_dn__T_long_press_str_2" 14 "W_2_Ticks_dn__T_long_press_str_3" 15 "W_1_Tick_dn" ;
VAL_ 1471 MFL_Eventcode_2 0 "W_no_event____T_no_event" 1 "W_1_Tick_up__T_pressed_normal" 2 "W_2_Ticks_up__T_touched" 3 "W_3_Ticks_up__T_double_click_nor" 4 "W_4_Ticks_up__T_long_press_nor_1" 5 "W_5_Ticks_up__T_long_press_nor_2" 6 "W_6_Ticks_up__T_long_press_nor_3" 7 "W_7_Ticks_up" 9 "W_7_Ticks_dn__T_pressed_strong" 10 "W_6_Ticks_dn" 11 "W_5_Ticks_dn__T_double_click_str" 12 "W_4_Ticks_dn__T_long_press_str_1" 13 "W_3_Ticks_dn__T_long_press_str_2" 14 "W_2_Ticks_dn__T_long_press_str_3" 15 "W_1_Tick_dn" ;
VAL_ 1471 MFL_Marke 0 "VW" 1 "Audi" 2 "Seat" 3 "Skoda" 4 "VW_Nutzf" 5 "Bugatti" 6 "Lamborghini" 7 "Bentley" 8 "Rolls Royce" 9 "Quattro" 10 "kein_Hersteller_1" 11 "kein_Hersteller_2" 12 "kein_Hersteller_3" 13 "kein_Hersteller_4" 14 "Ford" 15 "Porsche" ;
VAL_ 2463978865 MIK_Fahrer_erkannt 0 "Init" 1 "Fahrer_nicht_erkannt" 2 "Fahrer_erkannt" 3 "Fehler" ;
VAL_ 2463978865 MIK_TotDurEyesNotOnTfc 1021 "Unknown" 1022 "Init" 1023 "Error" ;
VAL_ 2463978865 MIK_BlinkRate 28 "Max_value_reached" 29 "Unknown" 30 "Init" 31 "Error" ;
VAL_ 2463978865 MIK_Status 0 "Inactive" 1 "Running" 2 "Not_available" 6 "Init" 7 "Error" ;
VAL_ 2463978865 MIK_LeftHandPos 0 "Unknown" 1 "Infotainment_display" 2 "Center_console" 3 "Armrest" 4 "Upper_body" 5 "Lower_body" 6 "Rear_view_mirror" 7 "Sun_visor" 8 "Driver_door" 9 "Light_switch" 10 "Steering_wheel" 11 "Far_left" 12 "Far_right" 14 "Init" 15 "Error" ;
VAL_ 2463978865 MIK_LeftHandPosQual 13 "Unknown" 14 "Init" 15 "Error" ;
VAL_ 2463978865 MIK_RightHandPos 0 "Unknown" 1 "Infotainment_display" 2 "Center_console" 3 "Armrest" 4 "Upper_body" 5 "Lower_body" 6 "Rear_view_mirror" 7 "Sun_visor" 8 "Driver_door" 9 "Light_switch" 10 "Steering_wheel" 11 "Far_left" 12 "Far_right" 14 "Init" 15 "Error" ;
VAL_ 2463978865 MIK_RightHandPosQual 13 "Unknown" 14 "Init" 15 "Error" ;
VAL_ 2463978865 MIK_DrowsinessLevel 0 "Extremely_alert" 1 "Very_alert" 2 "Alert" 3 "Fairly_alert" 4 "Neither_alert_nor_sleepy" 5 "Signs_of_sleepiness" 6 "Sleepy_no_effort" 7 "Sleepy_some_effort" 8 "Very_Sleepy" 13 "Unknown" 14 "Init" 15 "Error" ;
VAL_ 2463978865 MIK_DrowsinessLevelQual 14 "Init" 15 "Error" ;
VAL_ 2463978865 MIK_DriverSmoking 0 "No_driver_smoking" 1 "Driver_smoking" 5 "Unknown" 6 "Init" 7 "Error" ;
VAL_ 2463978865 MIK_PassengerPresence 0 "No_passenger_present" 1 "Passenger_present" ;
VAL_ 2463978865 MIK_DriverSmokingQual 13 "Unknown" 14 "Init" 15 "Error" ;
VAL_ 2463978865 MIK_DriverTelephoneUsage 0 "No_telephone_usage" 1 "Telephone_usage" 5 "Unknown" 6 "Init" 7 "Error" ;
VAL_ 2463978865 MIK_DriverSpeaking 0 "Driver_not_speaking" 1 "Driver_speaking" ;
VAL_ 2463978865 MIK_DriverTelephoneUsageQual 13 "Unknown" 14 "Init" 15 "Error" ;
VAL_ 2463978865 MIK_DriverYawning 0 "No_driver_yawning" 1 "Driver_yawning" 5 "Unknown" 6 "Init" 7 "Error" ;
VAL_ 2463978865 FaceRec_Auth_Challenge_Request 0 "SEND_NOTHING" 1 "SEND_CHALLENGE" ;
VAL_ 2463978865 MIK_DriverYawningQual 13 "Unknown" 14 "Init" 15 "Error" ;
VAL_ 2463978865 MIK_Microsleep 0 "No_microsleep_detected" 1 "Microsleep_imminent" 2 "Microsleep_detected" 6 "Init" 7 "Error" ;
VAL_ 2463978865 FaceRec2_Status_Challenge_Req 0 "SEND_NOTHING" 1 "SEND_CHALLENGE" ;
VAL_ 2463978865 MIK_MicrosleepQual 13 "Unknown" 14 "Init" 15 "Error" ;
VAL_ 2463978865 MIK_UnusualHeadPose 0 "No_unusual_head_pose" 1 "Unusual_head_pose" 5 "Unknown" 6 "Init" 7 "Error" ;
VAL_ 2463978865 MIK_UnusualHeadPoseQual 13 "Unknown" 14 "Init" 15 "Error" ;
VAL_ 2463978865 MIK_VisualDistractionLevel 0 "Not_distracted" 1 "Slightly_distracted" 2 "Distracted" 3 "Very_distracted" 5 "Unknown" 6 "Init" 7 "Error" ;
VAL_ 2463978865 MIK_VisualDistractionLevelQual 14 "Init" 15 "Error" ;
VAL_ 2463978865 MIK_DurEyesNotOnTfc 508 "Max_value_reached" 509 "Unknown" 510 "Init" 511 "Error" ;
VAL_ 2463978865 MIK_DurEyesCl 124 "Max_value_reached" 125 "Unknown" 126 "Init" 127 "Error" ;
VAL_ 2463978865 MIK_PercentageEyesOnTraffic 125 "Unknown" 126 "Init" 127 "Error" ;
VAL_ 2463978865 MIK_SpaAttDstrAr_01 0 "Unknown" 1 "Windshield_top_left" 2 "Windshield_top_right" 3 "Windshield_bottom_left" 4 "Windshield_bottom_center" 5 "Windshield_bottom_right" 6 "Windshield_bottom_far_right" 7 "Light_switch" 8 "Sidemirror_left" 9 "Sidemirror_right" 10 "Rear_view_mirror" 11 "Instrument_cluster" 12 "Dashboard" 13 "Steering_wheel" 14 "Infotainment_display" 15 "Center_console" 16 "Driver_lap" 17 "Glovebox" 18 "Far_left" 19 "Far_right" 30 "Init" 31 "Error" ;
VAL_ 2463978865 MIK_SpaAttDstrProb_01 13 "Unknown" 14 "Init" 15 "Error" ;
VAL_ 2463978865 MIK_DetectionMode 0 "Gaze" 1 "Head_pose" 2 "Combined" 3 "None" 6 "Init" 7 "Error" ;
VAL_ 2463978865 MIK_DriverChange 0 "No_driver_change_detected" 1 "Driver_change_detected" ;
VAL_ 2463978865 MIK_DriverPresence 0 "No_driver_present" 1 "Driver_present" 2 "Driver_present_and_buckled" 6 "Init" 7 "Error" ;
VAL_ 2463978865 MIK_FakeDetected 0 "No_fake_detected" 1 "Fake_detected" ;
VAL_ 2463978865 MIK_ICV_Brightness 126 "init" ;
VAL_ 2463978865 MIK_ICV_FrameRate 31 "init" ;
VAL_ 2463978865 MIK_ICV_FieldOfView 0 "init" 1 "show_Driver" 2 "show_CoDriver" 3 "show_fullCabine" ;
VAL_ 2463978865 MIK_ICV_FunctionState 0 "init" 1 "started" 2 "shutDown" 3 "error" ;
VAL_ 2463978865 MIK_ICV_Resolution 0 "Init" 1 "Aufloesung_160x120" 2 "Aufloesung_320x240" 3 "Aufloesung_640x480" 4 "Aufloesung_1280x720" 5 "Aufloesung_1920x1080" ;
VAL_ 2463978865 MIK_ICV_Videostream_State 0 "init" 1 "on" 2 "off" 3 "blurred" 4 "standby" 5 "freezed" 6 "error" ;
VAL_ 2463978865 MIK_ICV_VideostreamResult 0 "init" 1 "started" 2 "freezed" 3 "cancelled" ;
VAL_ 2463978865 MIK_ICV_ColorMode 0 "init" 1 "RGB" 2 "IR" ;
VAL_ 2463978865 MIK_ICV_HDR 0 "init" 1 "on" 2 "off" ;
VAL_ 2463978865 MIK_ICV_Contrast 126 "init" ;
VAL_ 2463978865 MIK_Selfie_FunctionState 0 "init" 1 "VideoShot_Start" 2 "VideoShot_Stop" 3 "PhotoShot_Single" 4 "PhotoShot_Continuous" 5 "Cancel" 6 "Error" ;
VAL_ 2463978865 MIK_Selfie_Resolution 0 "init" 1 "Res_5M_pixels" 2 "Res_2M_pixels" ;
VAL_ 2463978865 MIK_ICV_AspectRatio 0 "init" 1 "AspectRatio_4_3" 2 "AspectRatio_16_9" 3 "AspectRatio_3_4" 4 "AspectRatio_9_16" ;
VAL_ 2463978865 MIK_ICV_VideoLength 0 "init" 1 "Lenght_15s" 2 "Lenght_30s" 3 "Lenght_60s" 4 "customized" ;
VAL_ 2463978865 MIK_ChildStatus 0 "init" 1 "awake" 2 "sleep" ;
VAL_ 2463978865 MIK_PetPresence 0 "no_pet_present" 1 "pet_present" 2 "init" ;
VAL_ 2463978865 MIK_CabinCare_state 0 "Off" 1 "Initialization" 2 "Standby" 3 "Active" 4 "error" ;
VAL_ 2463978865 MIK_PetsMode_Active 0 "Function_disabled" 1 "Function_enabled" ;
VAL_ 2463978865 MIK_ChildPresence 0 "no_child_present" 1 "child_present" 2 "init" ;
VAL_ 2463978865 MIK_CabinCare_Active 0 "Function_disabled" 1 "Function_enabled" ;
VAL_ 2463978865 MIK_ICC_RemoteAccessStatus 0 "init" 1 "enabled" 2 "disabled" ;
VAL_ 263 MO_rel_Ladedruck 255 "Fehler" ;
VAL_ 263 MO_Istgang 0 "kein_Gang_eingelegt" 1 "Gang_1" 2 "Gang_2" 3 "Gang_3" 4 "Gang_4" 5 "Gang_5" 6 "Gang_6" 7 "Gang_7" 8 "Gang_8" 9 "Gang_9" ;
VAL_ 263 MO_Sollgang 0 "keine_Empfehlung" 1 "Gang_1" 2 "Gang_2" 3 "Gang_3" 4 "Gang_4" 5 "Gang_5" 6 "Gang_6" 7 "Gang_7" 8 "Gang_8" 9 "Gang_9" 15 "Neutralgang" ;
VAL_ 263 MO_Oeldruck 254 "Init" 255 "Fehler" ;
VAL_ 263 MO_Anzeigedrehz 4095 "reserviert" ;
VAL_ 263 MO_Effizienzmodus 0 "nicht_im_Effizienz_Modus" 1 "Effizienz_Modus" ;
VAL_ 263 MO_Fehler_Oeldrucksensor 0 "kein_Fehler" 1 "Fehler" ;
VAL_ 263 MO_Schaltempf_verfbar 0 "nicht_verfuegbar" 1 "verfuegbar" ;
VAL_ 263 MO_Ladedruck 511 "Fehler" ;
VAL_ 263 MO_KVS_Ueberlauf 0 "kein Ueberlauf" 1 "Kraftstoffverbrauchsignale mindestens 1x übergelaufen" ;
VAL_ 1600 MO_QBit_Ansaugluft_Temp 0 "gueltiger_Wert" 1 "Ersatz_Init_oder_Fehlerwert" ;
VAL_ 1600 MO_QBit_Oel_Temp 0 "gueltiger_Wert" 1 "Ersatz_Init_oder_Fehlerwert" ;
VAL_ 1600 MO_QBit_Kuehlmittel_Temp 0 "gueltiger_Wert" 1 "Ersatz_Init_oder_Fehlerwert" ;
VAL_ 1600 MO_KL15_Abschaltempfehlung 0 "Keine Empfehlung" 1 "Abschaltempfehlung" ;
VAL_ 1600 MO_HYB_Fehler_HV_Netz 0 "i_O" 1 "kein_generatorischer_Betrieb_moeglich" ;
VAL_ 1600 MO_aktives_Getriebeheizen 0 "kein_Ventil_ansteuern" 1 "Ventil_muss_angesteuert_werden" ;
VAL_ 1600 MO_Absperrventil_oeffnen 0 "nicht_verfuegbar" 1 "Ansteuerung_Ventil_zulaessig" 2 "Ventil_oeffnen_oder_geoeffnet" 3 "Ventil_schliessen_oder_geschlossen" ;
VAL_ 1600 MO_Ansaugluft_Temp 254 "Init" 255 "Fehler" ;
VAL_ 1600 MO_Oel_Temp 253 "nicht_verbaut" 254 "Init" 255 "Fehler" ;
VAL_ 1600 MO_Kuehlmittel_Temp 254 "Init" 255 "Fehler" ;
VAL_ 1600 MO_Hoeheninfo 255 "Fehler" ;
VAL_ 1600 MO_Kennfeldk 0 "keine Kennfeldkühlung vorhanden" 1 "Kennfeldkühlung vorhanden" ;
VAL_ 1600 MO_Versionsinfo_02 0 "zum_Projektbeginn_aufgeraeumter_CAN" 1 "Motor_03_mit_10ms" 16 "MQB_mit_neuer_Momentenschnittstelle" ;
VAL_ 1600 MO_QBit_Hoeheninfo 0 "gueltiger_Wert" 1 "Ersatz_Init_oder_Fehlerwert" ;
VAL_ 1600 MO_Getriebe_kuehlen 0 "nicht_kuehlen" 1 "kuehlen" ;
VAL_ 1600 MO_Heizungspumpenansteuerung 13 "Fehler" 14 "Init" 15 "nicht_verbaut" ;
VAL_ 1600 MO_SpannungsAnf 0 "keine_Anforderung" 1 "Anforderung" ;
VAL_ 958 MO_StartStopp_Status 0 "System_in_diesem_KL15_Zyklus_nicht_verfuegbar" 1 "System_aktiv_keine_Freigabe_durch_StartStop_Koordinator" 2 "System_aktiv_alle_Freigaben_liegen_vor" 3 "System_aktiv_mindestens_eine_Freigabe_fehlt" ;
VAL_ 958 MO_StartStopp_Wiederstart 0 "Wiederstart_inaktiv" 1 "Wiederstart_aktiv" ;
VAL_ 958 MO_StartStopp_Motorstopp 0 "Motor_Stop_inaktiv" 1 "Motor_Stop_aktiv" ;
VAL_ 958 MO_Freig_Reku 0 "Rekuperations-Modus aus" 1 "Empfehlung Spannungsanhebung" 2 "Empfehlung Spannungsabsenkung" 3 "Rekuperationsmodus aktiv, Spannungsvariation nicht notwendig" ;
VAL_ 958 MO_Kl_75 0 "Aus" 1 "Ein" ;
VAL_ 958 MO_Kl_50 0 "aus" 1 "KL50_ein_Startausfuehrung_Fahrer" ;
VAL_ 958 MO_Gangposition 0 "Gang_N" 1 "Gang_1" 2 "Gang_2" 3 "Gang_3" 4 "Gang_4" 5 "Gang_5" 6 "Gang_6" 7 "Gang_7" 8 "Gang_8" 9 "Automat_P" 10 "Automat_Vorwaerts_S" 11 "Automat_Vorwaerts_D/E" 12 "Zwischenstellung" 13 "Gang_R" 14 "Istgang_nicht_definiert" 15 "Fehler" ;
VAL_ 958 MO_StartStopp_Fahrerwunsch 0 "Init" 1 "Stoppverbot_durch_Fahrer" 2 "Stoppfreigabe_durch_Fahrer" 3 "Stoppanforderung_durch_Fahrer" ;
VAL_ 958 MO_HYB_Fahrbereitschaft 0 "keine_Fahrbereitschaft" 1 "Fahrbereitschaft" ;
VAL_ 958 MO_Ext_E_Fahrt_aktiv 0 "Rueckmeldung_E_Taster_aus" 1 "Rueckmeldung_E_Taster_ein" ;
VAL_ 958 MO_Fahrer_bremst 0 "kein_Bremsen" 1 "Bremse_betaetigt" ;
VAL_ 958 MO_QBit_Fahrer_bremst 0 "gueltiger_Wert" 1 "Ersatz_Init_oder_Fehlerwert" ;
VAL_ 958 MO_BLS 0 "kein_Bremsen" 1 "Bremse_betaetigt" ;
VAL_ 958 MO_Konsistenz_Bremsped 0 "Bremspedalinformation_plausibel" 1 "Bremspedalinformation_unplausibel" ;
VAL_ 958 MO_Timeout_ESP 0 "Empfang_iO" 1 "Timeout" ;
VAL_ 958 MO_Klima_Eingr 0 "kein Eingriff" 1 "Klimakompressor ausschalten" 2 "Klimakompressor Leistungsreduzierung" 3 "Klimakompressor aufgrund der Heissleuchtenvorwarnung ausschalten" ;
VAL_ 958 MO_Aussp_Anlass 0 "Anlasser_darf_angesteuert_werden" 1 "Anlasser_ausspuren__Ansteuerung_nicht_moeglich" ;
VAL_ 958 MO_Freig_Anlass 0 "Start_nicht_zulaessig" 1 "Startfreigabe" ;
VAL_ 958 MO_Kuppl_schalter 0 "Schalter_sagt_ausgekuppelt" 1 "Schalter_sagt_eingekuppelt" ;
VAL_ 958 MO_Interlock 0 "Interlockschalter_nicht_betaetigt" 1 "Interlockschalter_betaetigt" ;
VAL_ 958 MO_Motor_laeuft 0 "Motor_laeuft_nicht" 1 "Motor_laeuft_autark_und_stabil_und_darf_mechanisch_belastet_werden" ;
VAL_ 958 MO_Kickdown 0 "kein_Kickdown" 1 "Kickdown" ;
VAL_ 958 MO_QBit_KL_75 0 "gueltiger_Wert" 1 "Ersatz_Init_oder_Fehlerwert" ;
VAL_ 958 MO_EKlKomLeiRed 0 "keine_Leistungsbegr" 1 "Leistungsbegr_75" 2 "Leistungsbegr_50" 3 "Leistungsbegr_25" ;
VAL_ 958 MO_Handshake_STH 0 "keine EKP-Ansteuerung durch STH-Anforderung" 1 "EKP-Ansteuerung durch STH-Anforderung" ;
VAL_ 958 MO_BKV_Unterdruckwarnung 0 "Unterdruckhaushalt_iO" 1 "Unterdruckhaushalt_niO" ;
VAL_ 958 MO_Freigabe_Segeln 0 "Segelbetrieb_nicht_freigegeben" 1 "Segelbetrieb_freigegeben" ;
VAL_ 958 MO_PTC_Status 0 "nicht_unterstuetzt" 1 "Stufe_0" 2 "Stufe_1" 3 "Stufe_2" 4 "Stufe_3" 7 "PTC_am_BCM" ;
VAL_ 958 MO_QBit_Gangposition 0 "gueltiger_Wert" 1 "Ersatz_Init_oder_Fehlerwert" ;
VAL_ 958 MO_Signalquelle_Gangposition 0 "Sensorsignal" 1 "Modellsignal" ;
VAL_ 958 MO_Remotestart_Betrieb 0 "MSG_nicht_bereit_fuer_RS_Betrieb" 1 "MSG_bereit_fuer_oder_im_RS_Betrieb" ;
VAL_ 958 MO_Remotestart_moeglich 0 "Remotestart_nicht_moeglich" 1 "Remotestart_moeglich" ;
VAL_ 958 MO_FMAus_aktiv 0 "inaktiv" 1 "Segeln_mit_Motor_aus_aktiv" ;
VAL_ 958 MO_FMAus_Startvariante 0 "kein_Motorstart" 1 "Motorstart_elektrischer_Starter" 2 "GetriebeAnschleppstart" 3 "GetriebeNotAnschleppstart" ;
VAL_ 958 MO_BMS_NV_Anf_stuetzen 0 "nicht_notwendig" 1 "notwendig" ;
VAL_ 958 MO_Zylinderabschaltung 0 "Vollmotorbetrieb_VMB" 1 "Uebergang_HMB_in_VMB" 2 "Uebergang_VMB_in_HMB" 3 "Halbmotorbetrieb_HMB" ;
VAL_ 958 MO_HYB_VM_aktiv 0 "VM_nicht_aktiv" 1 "VM_aktiv" ;
VAL_ 958 MO_StartVorauss_erfuellt 0 "Signal_nicht_bedient" 1 "StartVorauss_nicht_ueberpruefbar" 2 "StartVorauss_nicht_erfuellt" 3 "StartVorauss_erfuellt" ;
VAL_ 1648 MO_ANC_Kennfeld_Anf 0 "Kennfeld_1" 1 "Uebergang_Kennfeld_2_nach_1" 2 "Uebergang_Kennfeld_1_nach_2" 3 "Kennfeld_2" ;
VAL_ 1648 MO_Bremslicht_Reku 0 "Aus" 1 "Ein" ;
VAL_ 1648 MO_StartStopp_PopUp 0 "Statuswechsel_ohne_Taster (Init)" 1 "StSt_per_Taster_deaktiviert" 2 "StSt_per_Taster_aktiviert" 3 "nicht verwendet" ;
VAL_ 1648 MO1_Sperr_Info_WFS 0 "nicht_gesperrt" 1 "gesperrt" ;
VAL_ 1648 MO1_Freigabe_Info_WFS 0 "ungueltig" 1 "gueltig" ;
VAL_ 1648 MO_EPCL 0 "EPCL_aus_kein_Text" 1 "EPCL_gelb_Stoerung" 2 "EPCL_gelb_Leistungsbeschraenkung" 3 "EPCL_rot_Fzg_sicher_abstellen" ;
VAL_ 1648 MO_Zylabsch_Texte_02 0 "ein_ZAS_generell_keine_ZAS_Anzeigen" 1 "ZAS_im_VMB" 2 "ZAS_im_ASB_1_Zyl_aktiv" 3 "ZAS_im_ASB_2_Zyl_aktiv" 4 "ZAS_im_ASB_3_Zyl_aktiv" 5 "ZAS_im_ASB_4_Zyl_aktiv" 6 "ZAS_im_ASB_5_Zyl_aktiv" 7 "ZAS_im_ASB_6_Zyl_aktiv" 8 "ZAS_im_ASB_8_Zyl_aktiv" 9 "ZAS_im_ASB_12_Zyl_aktiv" 13 "Uebergangsbetrieb" 14 "keine_ZAS_Anzeige_ggf_Stopp_Schub_Betrieb" 15 "ZAS_Stoerungs_Anzeige" ;
VAL_ 1648 MO_Fahrzeugtyp 0 "Verbrenner_Fahrzeug" 1 "Hybrid" 2 "E_Fahrzeug" 3 "E_Fahrzeug_mit_Range_Extender" 4 "Brennstoffzellenfahrzeug" 5 "tbd" 6 "tbd" 7 "tbd" ;
VAL_ 1648 MO_Abstellzeit 254 "Init" 255 "reserviert" ;
VAL_ 1648 MO_Abstellzeit_Status 0 "Abstellzeit_nicht_berechnet" 1 "Abstellzeit_berechnet" 2 "Abstellzeit_Minimalwert" 3 "Abstellzeit_ungueltig" ;
VAL_ 1648 MO1_Freigabe_Verfallsinfo_WFS 0 "verfaellt_nicht" 1 "verfaellt" ;
VAL_ 1648 MO_Hybrid_StartStopp_LED 0 "LED_aus_und_Blinken_aus" 1 "LED_ein_und_Blinken_aus" 2 "LED_ein_und_Blinken_ein_50_percent" 3 "reserviert" ;
VAL_ 1648 MO_Fehler_Zylabsch 0 "kein_Fehler" 1 "Notlauf_Vollmotorbetrieb" 2 "Notlauf_mindestens_einem_abgesch_Zylinder" ;
VAL_ 1648 MO_Anzahl_Abgesch_Zyl 0 "Vollmotorbetrieb" 1 "1_Zylinder_abgeschaltet" 2 "2_Zylinder_abgeschaltet" 3 "3_Zylinder_abgeschaltet" 4 "4_Zylinder_abgeschaltet" 5 "5_Zylinder_abgeschaltet" 6 "6_Zylinder_abgeschaltet" 7 "8_Zylinder_abgeschaltet" ;
VAL_ 1648 MO_Zylabsch_Texte 0 "keine_Texte" 1 "Zylinderabschaltung_deaktivieren" 2 "Zylinderabschaltung_aktivieren" 3 "Zylinderabschaltung_unruhig" ;
VAL_ 1648 MO_Ethanol_BS_Texte 0 "kein_Text" 1 "E85_Warm_Up" 2 "FlexFuel_Warnung_Stufe_3" 3 "Warmfahrempfehlung_MQB__FlexFuel_Warnung_Stufe_1" 4 "FlexFuel_Warnung_Stufe_2" 5 "FlexFuel_Warnung_Stufe_4" 6 "E25_Warm_Up" ;
VAL_ 1648 MO_Drehzahl_Warnung 0 "keinen_Warnhinweis_anzeigen" 1 "Warnhinweis_anzeigen" ;
VAL_ 1648 MO_obere_Drehzahlgrenze 0 "Init" ;
VAL_ 967 MO_Kuehlerluefter_MUX 0 "Kuehlerluefter_1" 1 "Kuehlerluefter_2" ;
VAL_ 967 MO_Kuehlerluefter_1 126 "Init" 127 "Fehler" ;
VAL_ 967 MO_Kuehlerluefter_2 126 "Init" 127 "Fehler" ;
VAL_ 967 MO_EFLEX_Lampe 0 "Lampe_aus" 1 "Lampe_ein" 2 "Lampe_blinkend" 3 "Lampe_blinkend_mit_Akustik" ;
VAL_ 967 MO_KJS_nicht_bereit 0 "kein_Fehler" 1 "Fehler" ;
VAL_ 967 MO_ITM_Warnung_Pumpe 0 "keine_Warnung" 1 "ITM_Warnung" ;
VAL_ 967 WIV_Anzeige_aktiv 0 "Anzeige aus" 1 "WIV Anzeige aktiv" ;
VAL_ 967 WIV_Oelmin_Warn 0 "in_Ordnung" 1 "Warnung" ;
VAL_ 967 WIV_Sensorfehler 0 "in_Ordnung" 1 "Sensor_defekt" ;
VAL_ 967 WIV_Schieflage 0 "Fahrzeug_gerade" 1 "Fahrzeug_in_Schieflage" ;
VAL_ 967 MO_Zustand_HWP 0 "HWP_nicht_schaltbar" 1 "HWP_foerdert_nicht" 2 "HWP_foerdert" 3 "reserviert" ;
VAL_ 967 OLEV_Systemstoerung 0 "Ölsystem i.O." 1 "Systemstörung Ölsystem" ;
VAL_ 967 MO_Oelwarnung_max 0 "keine_Warnung" 1 "Warnfall_aktiv" ;
VAL_ 967 WIV_Oelsystem_aktiv 0 "Anzeige_aus" 1 "Anzeige_aktiv" ;
VAL_ 967 WIV_nicht_betriebswarm 0 "Motor_warm" 1 "Motor_nicht_betriebswarm" ;
VAL_ 967 WIV_Ueberfuell_Warn 0 "in_Ordnung" 1 "Ueberfuellwarnung" ;
VAL_ 967 WIV_laufender_Motor 0 "Messung_moeglich" 1 "Messung_nicht_moeglich" ;
VAL_ 967 MO_E_Warnungen 0 "keine_Anzeige" 1 "Fehler_Elektrosystem_Anhalten" 2 "Fehler_Elektrosystem_Werkstatt" 3 "Elektrosystem_ueberhitzt_Stopp" 4 "Fehler_Hybridsystem_Anhalten" 5 "Fehler_Hybridsystem_Werkstatt" 6 "Fehler_Wasserstoffsystem_Anhalte" 7 "Fehler_Wasserstoffsystem_Werksta" 8 "reserviert_keine_Anzeige" 9 "reserviert_keine_Anzeige" 10 "reserviert_keine_Anzeige" 11 "reserviert_keine_Anzeige" 12 "reserviert_keine_Anzeige" 13 "reserviert_keine_Anzeige" 14 "reserviert_keine_Anzeige" 15 "reserviert_keine_Anzeige" ;
VAL_ 967 MO_Text_Motorstart 0 "keine_Anzeige" 1 "Motor_im_Stoppbetrieb" 2 "StartStopp_sicherheitsbedingt_deaktiviert" 3 "System_fordert_Wiederstart" 4 "Aufforderung_Motorstart" 5 "Motorlauf_noetig" 6 "Motorlaufwarnung" 9 "Unerwuenschter_Motorstillstand" 10 "Motorstart_nicht_moeglich" 11 "Fehler_Kupplungsschalter" 12 "Motor_startet" 13 "Kupplung_betaetigen" 14 "Waehlhebel_in_PN_Position" 15 "Bremse_treten" ;
VAL_ 967 MO_E_Texte 0 "keine_Anzeige" 1 "Batterie_fast_leer" 2 "Ladestecker_nicht_fahrbereit" 3 "VM_Betrieb_erforderlich" 4 "Batterie_laedt_Nicht_ausschalten" 5 "Bitte_Bremse_treten" 6 "manueller_Neustart_erforderlich" 7 "Stopp_Fahrzeug_nicht_abschleppen" 8 "kein_Neustart_Haube_nicht_oeffnen" 9 "Motorstart_im_naechsten_Zyklus" 10 "VM_erforderlich_EVMode_abwaehlen" 11 "laengerer_VMBetrieb_Bordbuch" 12 "Tank_leer_VM_nicht_verfuegbar" 13 "Bitte_warten_Motor_startet" 14 "kein_Start_Batterietemperatur" 15 "Ende_elektrische_Reichweite_erreicht" ;
VAL_ 967 WIV_Oeldyn_avl 0 "Oeldyn_nicht_vorhanden" 1 "Oeldyn_vorhanden" ;
VAL_ 967 OLEV_Oelstand_nicht_vorhanden 0 "Ölstand vorhanden" 1 "Ölstand nicht vorhanden" ;
VAL_ 967 MO_Systemlampe 0 "Lampe aus" 1 "Lampe ein" ;
VAL_ 967 MO_OBD2_Lampe 0 "Lampe aus" 1 "Lampe ein" ;
VAL_ 967 MO_Heissleuchte 0 "Lampe aus" 1 "Lampe ein" ;
VAL_ 967 MO_Partikel_Lampe 0 "Lampe aus" 1 "Lampe ein" ;
VAL_ 967 MO_RedFahrleistung_Lampe 0 "Lampe_aus" 1 "Lampe_ein" ;
VAL_ 967 WIV_Oelstand_nicht_vorhanden 0 "Ölstand vorhanden" 1 "Ölstand nicht vorhanden" ;
VAL_ 967 WIV_nachfuellanzeige_ein 0 "keine_Nachfuellanzeige" 1 "Nachfuellanzeige" ;
VAL_ 967 WIV_Ueberfuell_deaktiv 0 "Ueberfuellwarnung_am_Kombi_aktiv" 1 "Ueberfuellwarnung_am_Kombi_deaktiv" ;
VAL_ 967 WIV_Unterfuell_Warn 0 "in_Ordnung" 1 "Unterfuellwarnung" ;
VAL_ 967 MO_Tankdeckel_Lampe 0 "Lampe aus" 1 "Lampe ein" ;
VAL_ 967 MO_Text_Tankdeckelwarn 0 "kein_Text" 1 "Anzeige_Text_Tankdeckelwarnung_im_Kombi" ;
VAL_ 967 MO_Vorglueh_Lampe 0 "Lampe_aus" 1 "Lampe_ein" ;
VAL_ 967 WIV_Oeldr_Warn_Motor 0 "keine_Warnung" 1 "niedrige_Oeldruckstufe_nicht_erreicht" ;
VAL_ 967 MO_E_Mode 0 "keine_Anzeige" 1 "E_Mode_passiv" 2 "E_Mode_aktiv" 3 "E_Mode_inaktiv_nicht_verfuegbar" 4 "E_Mode_aktiv_nicht_verfuegbar" 5 "reserviert_keine_Anzeige" 6 "reserviert_keine_Anzeige" 7 "reserviert_keine_Anzeige" ;
VAL_ 267 MO_Fahrpedalrohwert_01 255 "Fehler" ;
VAL_ 267 MO_QBit_Fahrpedalwerte_01 0 "gueltiger_Wert" 1 "Ersatz_Init_oder_Fehlerwert" ;
VAL_ 267 MO_Fahrpedalgradient 255 "Fehler" ;
VAL_ 267 MO_Sig_Fahrpedalgradient 0 "Fahrpedalgradient positiv" 1 "Fahrpedalgradient negativ" ;
VAL_ 267 MO_rel_Saugrohrdruck 0 "Init_Ueberdruck" 63 "Fehler" ;
VAL_ 267 MO_rel_Saugrohrdruck_gem_err 0 "errechnet" 1 "gemessen" ;
VAL_ 267 MO_Moment_im_Leerlauf 0 "kein_Leergas" 1 "Leergas" ;
VAL_ 267 MO_Schubabschaltung 0 "keine_Schubabschaltung" 1 "Schubabschaltung_aktiv" ;
VAL_ 267 MO_StartStopp_StoppVorbereitung 0 "Motorstopp_nicht_in_Vorbereitung" 1 "Motorstopp_in_Vorbereitung" ;
VAL_ 267 MO_Entkopplung_Sollschlupf 125 "Notoeffnen_Anfahrelement" 126 "Init" ;
VAL_ 267 MO_temporaere_Fahrerabwesenheit 0 "nicht_erkannt" 1 "erkannt" ;
VAL_ 267 TSK_a_Soll_gradientenbegrenzt 127 "Init_oder_nicht_aktiv" ;
VAL_ 267 TSK_Status 0 "Hauptschalter_aus" 1 "Init" 2 "passiv" 3 "aktiv" 4 "Uebertreten" 5 "brake_only_Mode" 6 "reversibel_aus" 7 "irreversibel_aus" ;
VAL_ 267 TSK_v_Begrenzung_aktiv 0 "inaktiv" 1 "aktiv" ;
VAL_ 267 TSK_Standby_Anf_ESP 0 "keine_Standby_Anforderung" 1 "Standby_Anforderung" ;
VAL_ 267 TSK_Freig_Verzoeg_Anf 0 "Verzoegerungsanforderung_nicht_freigegeben" 1 "Verzoegerungsanforderung_freigegeben" ;
VAL_ 267 TSK_Limiter_ausgewaehlt 0 "kein_Limiter_ausgewaehlt" 1 "Limiter_ausgewaehlt" ;
VAL_ 267 TSK_Hauptschalter_GRA_ACC 0 "Init" 1 "Aus" 2 "Ein" 3 "Fehler" ;
VAL_ 267 TSK_SRBM_Anf_ASIL 0 "keine_SRBM_Anforderung" 1 "SRBM_Anforderung_in_ASIL_QM" 2 "SRBM_Anforderung_in_ASIL_A" 3 "SRBM_Anforderung_in_ASIL_B" 4 "SRBM_Anforderung_in_ASIL_C" ;
VAL_ 267 TSK_ax_Getriebe_02 511 "Neutralwert" ;
VAL_ 267 TSK_Zwangszusch_ESP 0 "keine_ESP_ASR_Beeinflussung" 1 "ESP_ASR_Beeinflussung" ;
VAL_ 267 TSK_Radsollmoment 65534 "Init" 65535 "Fehler" ;
VAL_ 267 TSK_Kategorie_Verzoegerungsfkt 0 "Schnittstelle_nicht_vorhanden" 1 "Kategorie_Fahrerassistenz" 2 "Kategorie_Schubverzoegerung" 3 "reserviert" ;
VAL_ 267 TSK_Notstopp_Anf 0 "Ueberwachung_aus" 1 "Ueberwachung_ein" 2 "Notstopp_ausloesen" ;
VAL_ 267 MO_Status_MinDrzEingriff 0 "kein_Eingriff" 1 "Schalteingriff" 2 "ESP_Eingriff" 3 "Achsdifferenzdrehzahl" 4 "Bauteilschutz" 5 "Rennstart_Fahrbarkeit" ;
VAL_ 267 MO_Status_MaxDrzEingriff 0 "kein_Eingriff" 1 "Schalteingriff" 2 "ESP_Eingriff" 3 "Achsdifferenzdrehzahl" 4 "Bauteilschutz" 5 "Rennstart_Fahrbarkeit" ;
VAL_ 267 MO_Status_MinDrzEingriff_sek 0 "kein_Eingriff" 1 "Schalteingriff" 2 "ESP_Eingriff" 3 "Achsdifferenzdrehzahl" 4 "Bauteilschutz" 5 "Rennstart_Fahrbarkeit" ;
VAL_ 267 MO_Status_MaxDrzEingriff_sek 0 "kein_Eingriff" 1 "Schalteingriff" 2 "ESP_Eingriff" 3 "Achsdifferenzdrehzahl" 4 "Bauteilschutz" 5 "Rennstart_Fahrbarkeit" ;
VAL_ 267 TSK_SRBM_max_Gradient 126 "Init" 127 "Fehler" ;
